VERSION "12.2.7"

NS_ :

BS_:

BU_: AMP CPD EASC HUD MHU XGW_Info PAS_Info PAS_LITE FCAM_Info

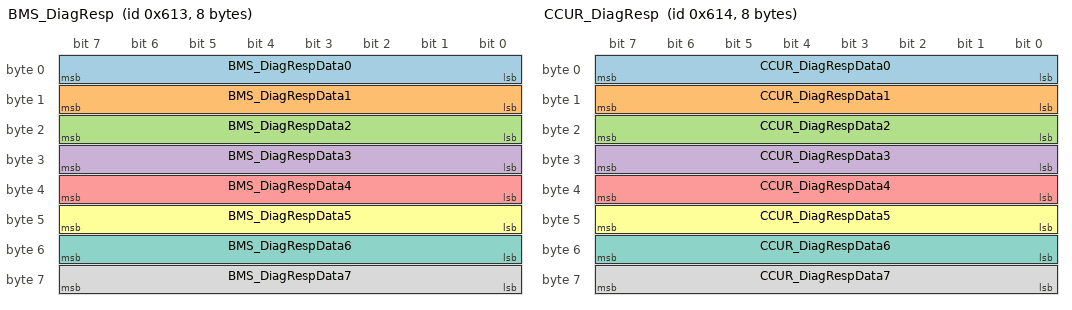
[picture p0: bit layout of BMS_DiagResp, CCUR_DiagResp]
BO_ 1555 BMS_DiagResp: 8 XGW_Info
  SG_ BMS_DiagRespData0 : 7|8@0+ (1,0) [0|255] "" MHU
  SG_ BMS_DiagRespData1 : 15|8@0+ (1,0) [0|255] "" MHU
  SG_ BMS_DiagRespData2 : 23|8@0+ (1,0) [0|255] "" MHU
  SG_ BMS_DiagRespData3 : 31|8@0+ (1,0) [0|255] "" MHU
  SG_ BMS_DiagRespData4 : 39|8@0+ (1,0) [0|255] "" MHU
  SG_ BMS_DiagRespData5 : 47|8@0+ (1,0) [0|255] "" MHU
  SG_ BMS_DiagRespData6 : 55|8@0+ (1,0) [0|255] "" MHU
  SG_ BMS_DiagRespData7 : 63|8@0+ (1,0) [0|255] "-" MHU

BO_ 1556 CCUR_DiagResp: 8 XGW_Info
  SG_ CCUR_DiagRespData0 : 7|8@0+ (1,0) [0|255] "" MHU
  SG_ CCUR_DiagRespData1 : 15|8@0+ (1,0) [0|255] "" MHU
  SG_ CCUR_DiagRespData2 : 23|8@0+ (1,0) [0|255] "" MHU
  SG_ CCUR_DiagRespData3 : 31|8@0+ (1,0) [0|255] "" MHU
  SG_ CCUR_DiagRespData4 : 39|8@0+ (1,0) [0|255] "-" MHU
  SG_ CCUR_DiagRespData5 : 47|8@0+ (1,0) [0|255] "" MHU
  SG_ CCUR_DiagRespData6 : 55|8@0+ (1,0) [0|255] "-" MHU
  SG_ CCUR_DiagRespData7 : 63|8@0+ (1,0) [0|255] "" MHU

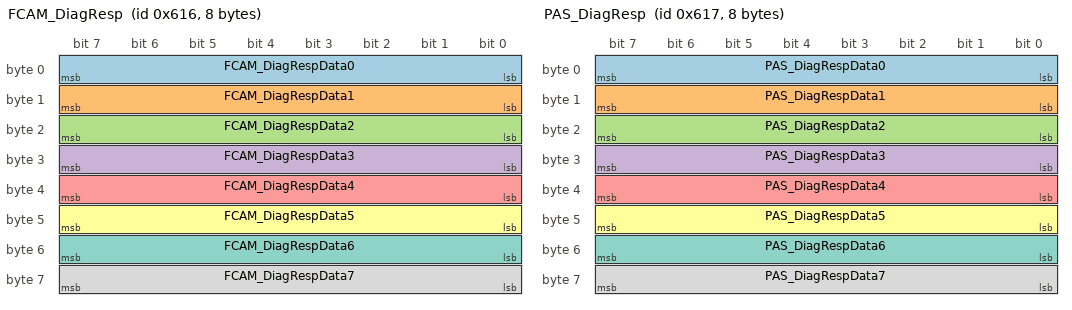
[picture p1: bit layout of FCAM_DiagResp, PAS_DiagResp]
BO_ 1558 FCAM_DiagResp: 8 XGW_Info
 SG_ FCAM_DiagRespData0 : 7|8@0+ (1,0) [0|255] ""  MHU
 SG_ FCAM_DiagRespData1 : 15|8@0+ (1,0) [0|255] ""  MHU
 SG_ FCAM_DiagRespData2 : 23|8@0+ (1,0) [0|255] ""  MHU
 SG_ FCAM_DiagRespData3 : 31|8@0+ (1,0) [0|255] ""  MHU
 SG_ FCAM_DiagRespData4 : 39|8@0+ (1,0) [0|255] ""  MHU
 SG_ FCAM_DiagRespData5 : 47|8@0+ (1,0) [0|255] ""  MHU
 SG_ FCAM_DiagRespData6 : 55|8@0+ (1,0) [0|255] ""  MHU
 SG_ FCAM_DiagRespData7 : 63|8@0+ (1,0) [0|255] ""  MHU

BO_ 1559 PAS_DiagResp: 8 XGW_Info
 SG_ PAS_DiagRespData0 : 7|8@0+ (1,0) [0|255] ""  MHU
 SG_ PAS_DiagRespData1 : 15|8@0+ (1,0) [0|255] ""  MHU
 SG_ PAS_DiagRespData2 : 23|8@0+ (1,0) [0|255] ""  MHU
 SG_ PAS_DiagRespData3 : 31|8@0+ (1,0) [0|255] ""  MHU
 SG_ PAS_DiagRespData4 : 39|8@0+ (1,0) [0|255] ""  MHU
 SG_ PAS_DiagRespData5 : 47|8@0+ (1,0) [0|255] ""  MHU
 SG_ PAS_DiagRespData6 : 55|8@0+ (1,0) [0|255] ""  MHU
 SG_ PAS_DiagRespData7 : 63|8@0+ (1,0) [0|255] ""  MHU

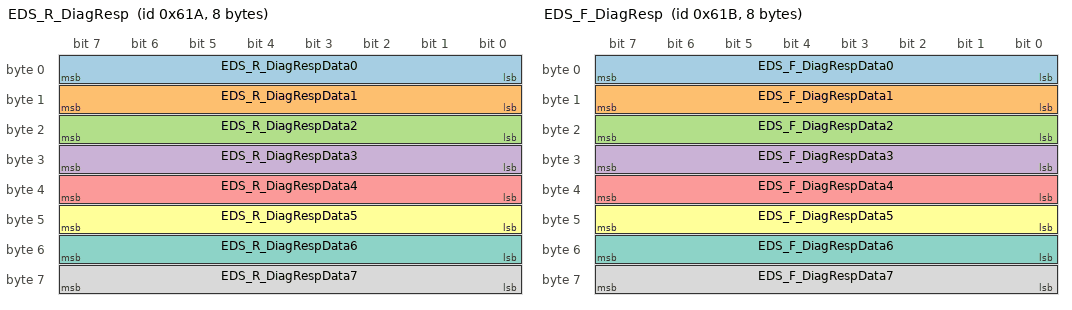
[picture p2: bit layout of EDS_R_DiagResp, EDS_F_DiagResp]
BO_ 1562 EDS_R_DiagResp: 8 XGW_Info
  SG_ EDS_R_DiagRespData0 : 7|8@0+ (1,0) [0|255] "" MHU
  SG_ EDS_R_DiagRespData1 : 15|8@0+ (1,0) [0|255] "" MHU
  SG_ EDS_R_DiagRespData2 : 23|8@0+ (1,0) [0|255] "-" MHU
  SG_ EDS_R_DiagRespData3 : 31|8@0+ (1,0) [0|255] "" MHU
  SG_ EDS_R_DiagRespData4 : 39|8@0+ (1,0) [0|255] "" MHU
  SG_ EDS_R_DiagRespData5 : 47|8@0+ (1,0) [0|255] "-" MHU
  SG_ EDS_R_DiagRespData6 : 55|8@0+ (1,0) [0|255] "-" MHU
  SG_ EDS_R_DiagRespData7 : 63|8@0+ (1,0) [0|255] "-" MHU

BO_ 1563 EDS_F_DiagResp: 8 XGW_Info
  SG_ EDS_F_DiagRespData0 : 7|8@0+ (1,0) [0|255] "" MHU
  SG_ EDS_F_DiagRespData1 : 15|8@0+ (1,0) [0|255] "" MHU
  SG_ EDS_F_DiagRespData2 : 23|8@0+ (1,0) [0|255] "-" MHU
  SG_ EDS_F_DiagRespData3 : 31|8@0+ (1,0) [0|255] "" MHU
  SG_ EDS_F_DiagRespData4 : 39|8@0+ (1,0) [0|255] "" MHU
  SG_ EDS_F_DiagRespData5 : 47|8@0+ (1,0) [0|255] "" MHU
  SG_ EDS_F_DiagRespData6 : 55|8@0+ (1,0) [0|255] "-" MHU
  SG_ EDS_F_DiagRespData7 : 63|8@0+ (1,0) [0|255] "" MHU

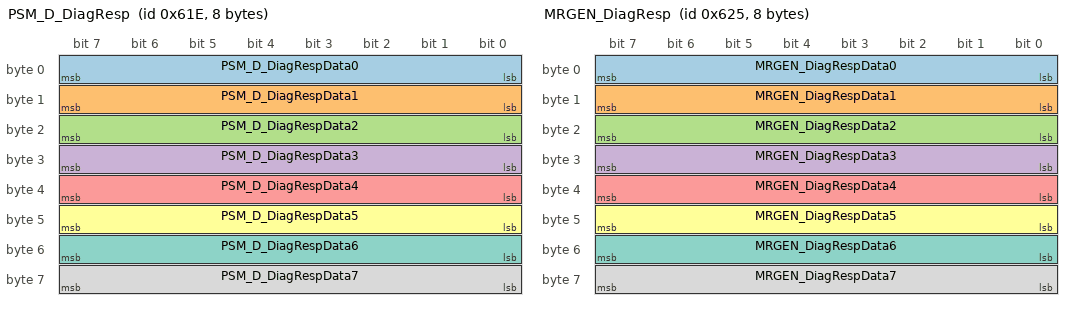
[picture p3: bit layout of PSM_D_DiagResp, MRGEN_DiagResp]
BO_ 1566 PSM_D_DiagResp: 8 XGW_Info
  SG_ PSM_D_DiagRespData0 : 7|8@0+ (1,0) [0|255] "" MHU
  SG_ PSM_D_DiagRespData1 : 15|8@0+ (1,0) [0|255] "" MHU
  SG_ PSM_D_DiagRespData2 : 23|8@0+ (1,0) [0|255] "" MHU
  SG_ PSM_D_DiagRespData3 : 31|8@0+ (1,0) [0|255] "-" MHU
  SG_ PSM_D_DiagRespData4 : 39|8@0+ (1,0) [0|255] "" MHU
  SG_ PSM_D_DiagRespData5 : 47|8@0+ (1,0) [0|255] "" MHU
  SG_ PSM_D_DiagRespData6 : 55|8@0+ (1,0) [0|255] "" MHU
  SG_ PSM_D_DiagRespData7 : 63|8@0+ (1,0) [0|255] "" MHU

BO_ 1573 MRGEN_DiagResp: 8 XGW_Info
  SG_ MRGEN_DiagRespData0 : 7|8@0+ (1,0) [0|255] "" MHU
  SG_ MRGEN_DiagRespData1 : 15|8@0+ (1,0) [0|255] "" MHU
  SG_ MRGEN_DiagRespData2 : 23|8@0+ (1,0) [0|255] "" MHU
  SG_ MRGEN_DiagRespData3 : 31|8@0+ (1,0) [0|255] "" MHU
  SG_ MRGEN_DiagRespData4 : 39|8@0+ (1,0) [0|255] "" MHU
  SG_ MRGEN_DiagRespData5 : 47|8@0+ (1,0) [0|255] "" MHU
  SG_ MRGEN_DiagRespData6 : 55|8@0+ (1,0) [0|255] "" MHU
  SG_ MRGEN_DiagRespData7 : 63|8@0+ (1,0) [0|255] "" MHU

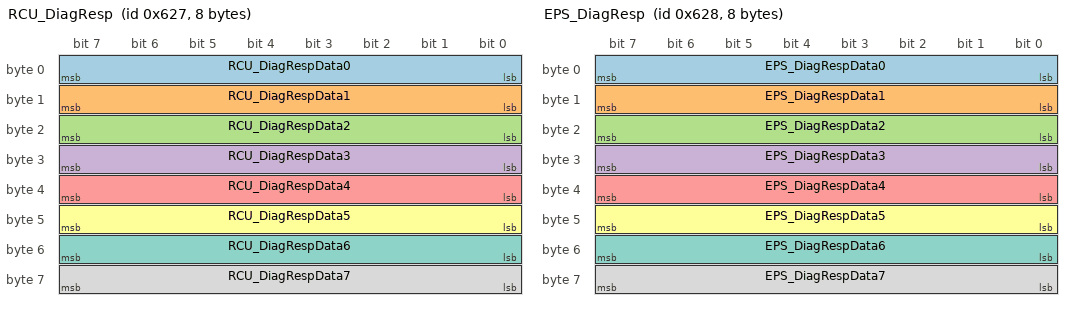
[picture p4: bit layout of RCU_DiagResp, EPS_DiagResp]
BO_ 1575 RCU_DiagResp: 8 XGW_Info
  SG_ RCU_DiagRespData0 : 7|8@0+ (1,0) [0|255] "" MHU
  SG_ RCU_DiagRespData1 : 15|8@0+ (1,0) [0|255] "" MHU
  SG_ RCU_DiagRespData2 : 23|8@0+ (1,0) [0|255] "" MHU
  SG_ RCU_DiagRespData3 : 31|8@0+ (1,0) [0|255] "" MHU
  SG_ RCU_DiagRespData4 : 39|8@0+ (1,0) [0|255] "" MHU
  SG_ RCU_DiagRespData5 : 47|8@0+ (1,0) [0|255] "" MHU
  SG_ RCU_DiagRespData6 : 55|8@0+ (1,0) [0|255] "" MHU
  SG_ RCU_DiagRespData7 : 63|8@0+ (1,0) [0|255] "" MHU

BO_ 1576 EPS_DiagResp: 8 XGW_Info
  SG_ EPS_DiagRespData0 : 7|8@0+ (1,0) [0|255] "-" MHU
  SG_ EPS_DiagRespData1 : 15|8@0+ (1,0) [0|255] "" MHU
  SG_ EPS_DiagRespData2 : 23|8@0+ (1,0) [0|255] "" MHU
  SG_ EPS_DiagRespData3 : 31|8@0+ (1,0) [0|255] "-" MHU
  SG_ EPS_DiagRespData4 : 39|8@0+ (1,0) [0|255] "" MHU
  SG_ EPS_DiagRespData5 : 47|8@0+ (1,0) [0|255] "" MHU
  SG_ EPS_DiagRespData6 : 55|8@0+ (1,0) [0|255] "-" MHU
  SG_ EPS_DiagRespData7 : 63|8@0+ (1,0) [0|255] "-" MHU

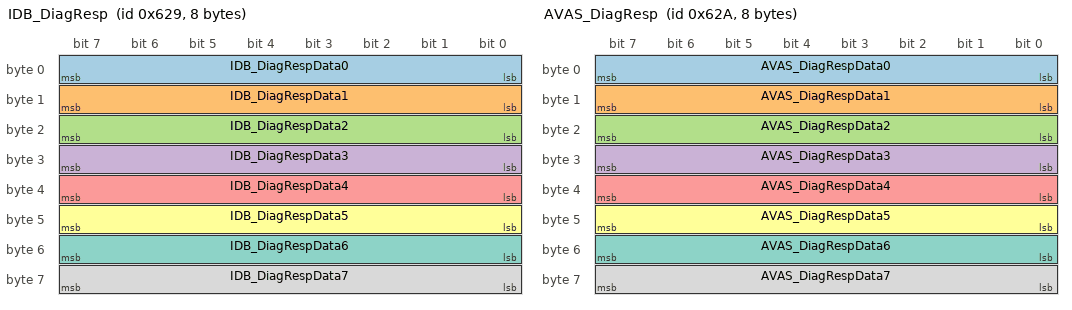
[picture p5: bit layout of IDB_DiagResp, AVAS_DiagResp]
BO_ 1577 IDB_DiagResp: 8 XGW_Info
  SG_ IDB_DiagRespData0 : 7|8@0+ (1,0) [0|255] "" MHU
  SG_ IDB_DiagRespData1 : 15|8@0+ (1,0) [0|255] "-" MHU
  SG_ IDB_DiagRespData2 : 23|8@0+ (1,0) [0|255] "-" MHU
  SG_ IDB_DiagRespData3 : 31|8@0+ (1,0) [0|255] "" MHU
  SG_ IDB_DiagRespData4 : 39|8@0+ (1,0) [0|255] "" MHU
  SG_ IDB_DiagRespData5 : 47|8@0+ (1,0) [0|255] "-" MHU
  SG_ IDB_DiagRespData6 : 55|8@0+ (1,0) [0|255] "-" MHU
  SG_ IDB_DiagRespData7 : 63|8@0+ (1,0) [0|255] "" MHU

BO_ 1578 AVAS_DiagResp: 8 XGW_Info
  SG_ AVAS_DiagRespData0 : 7|8@0+ (1,0) [0|255] "" MHU
  SG_ AVAS_DiagRespData1 : 15|8@0+ (1,0) [0|255] "" MHU
  SG_ AVAS_DiagRespData2 : 23|8@0+ (1,0) [0|255] "" MHU
  SG_ AVAS_DiagRespData3 : 31|8@0+ (1,0) [0|255] "" MHU
  SG_ AVAS_DiagRespData4 : 39|8@0+ (1,0) [0|255] "" MHU
  SG_ AVAS_DiagRespData5 : 47|8@0+ (1,0) [0|255] "" MHU
  SG_ AVAS_DiagRespData6 : 55|8@0+ (1,0) [0|255] "" MHU
  SG_ AVAS_DiagRespData7 : 63|8@0+ (1,0) [0|255] "-" MHU

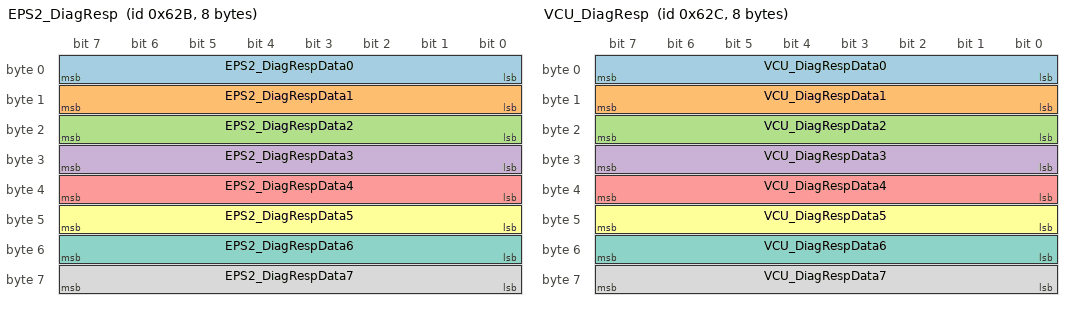
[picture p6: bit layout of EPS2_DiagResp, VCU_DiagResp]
BO_ 1579 EPS2_DiagResp: 8 XGW_Info
  SG_ EPS2_DiagRespData0 : 7|8@0+ (1,0) [0|255] "" MHU
  SG_ EPS2_DiagRespData1 : 15|8@0+ (1,0) [0|255] "-" MHU
  SG_ EPS2_DiagRespData2 : 23|8@0+ (1,0) [0|255] "-" MHU
  SG_ EPS2_DiagRespData3 : 31|8@0+ (1,0) [0|255] "" MHU
  SG_ EPS2_DiagRespData4 : 39|8@0+ (1,0) [0|255] "-" MHU
  SG_ EPS2_DiagRespData5 : 47|8@0+ (1,0) [0|255] "" MHU
  SG_ EPS2_DiagRespData6 : 55|8@0+ (1,0) [0|255] "-" MHU
  SG_ EPS2_DiagRespData7 : 63|8@0+ (1,0) [0|255] "-" MHU

BO_ 1580 VCU_DiagResp: 8 XGW_Info
  SG_ VCU_DiagRespData0 : 7|8@0+ (1,0) [0|255] "" MHU
  SG_ VCU_DiagRespData1 : 15|8@0+ (1,0) [0|255] "" MHU
  SG_ VCU_DiagRespData2 : 23|8@0+ (1,0) [0|255] "" MHU
  SG_ VCU_DiagRespData3 : 31|8@0+ (1,0) [0|255] "" MHU
  SG_ VCU_DiagRespData4 : 39|8@0+ (1,0) [0|255] "-" MHU
  SG_ VCU_DiagRespData5 : 47|8@0+ (1,0) [0|255] "" MHU
  SG_ VCU_DiagRespData6 : 55|8@0+ (1,0) [0|255] "" MHU
  SG_ VCU_DiagRespData7 : 63|8@0+ (1,0) [0|255] "-" MHU

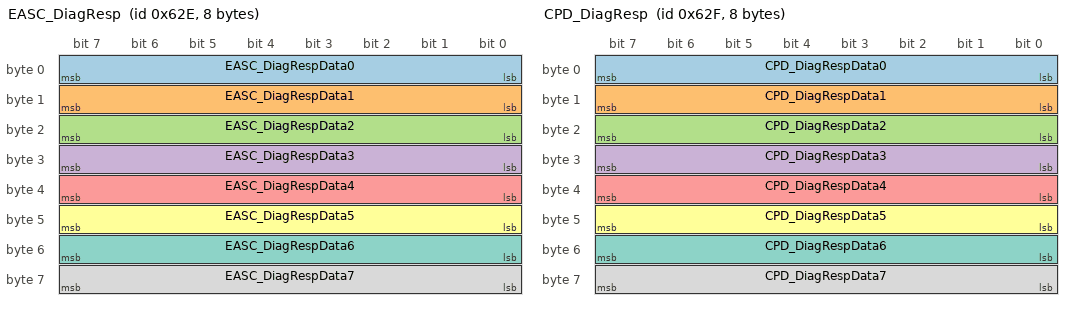
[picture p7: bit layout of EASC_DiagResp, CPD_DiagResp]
BO_ 1582 EASC_DiagResp: 8 EASC
  SG_ EASC_DiagRespData0 : 7|8@0+ (1,0) [0|255] "-" XGW_Info
  SG_ EASC_DiagRespData1 : 15|8@0+ (1,0) [0|255] "-" XGW_Info
  SG_ EASC_DiagRespData2 : 23|8@0+ (1,0) [0|255] "-" XGW_Info
  SG_ EASC_DiagRespData3 : 31|8@0+ (1,0) [0|255] "" XGW_Info
  SG_ EASC_DiagRespData4 : 39|8@0+ (1,0) [0|255] "" XGW_Info
  SG_ EASC_DiagRespData5 : 47|8@0+ (1,0) [0|255] "" XGW_Info
  SG_ EASC_DiagRespData6 : 55|8@0+ (1,0) [0|255] "" XGW_Info
  SG_ EASC_DiagRespData7 : 63|8@0+ (1,0) [0|255] "" XGW_Info

BO_ 1583 CPD_DiagResp: 8 CPD
  SG_ CPD_DiagRespData0 : 7|8@0+ (1,0) [0|255] "-" XGW_Info
  SG_ CPD_DiagRespData1 : 15|8@0+ (1,0) [0|255] "-" XGW_Info
  SG_ CPD_DiagRespData2 : 23|8@0+ (1,0) [0|255] "" XGW_Info
  SG_ CPD_DiagRespData3 : 31|8@0+ (1,0) [0|255] "-" XGW_Info
  SG_ CPD_DiagRespData4 : 39|8@0+ (1,0) [0|255] "-" XGW_Info
  SG_ CPD_DiagRespData5 : 47|8@0+ (1,0) [0|255] "" XGW_Info
  SG_ CPD_DiagRespData6 : 55|8@0+ (1,0) [0|255] "-" XGW_Info
  SG_ CPD_DiagRespData7 : 63|8@0+ (1,0) [0|255] "" XGW_Info

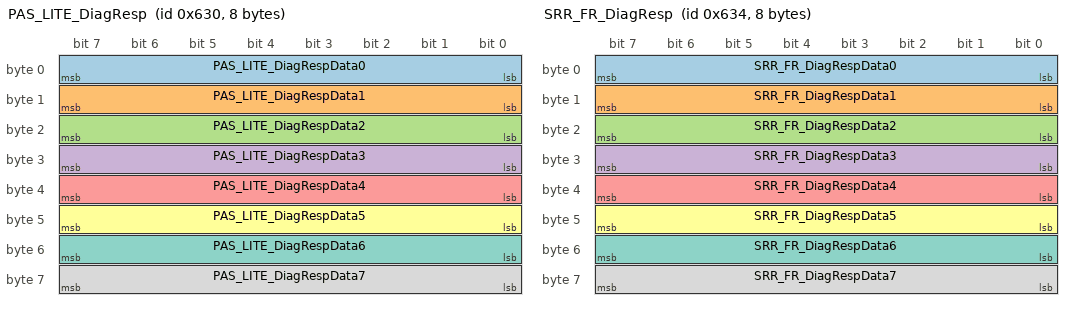
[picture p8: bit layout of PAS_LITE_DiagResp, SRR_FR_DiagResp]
BO_ 1584 PAS_LITE_DiagResp: 8 PAS_LITE
  SG_ PAS_LITE_DiagRespData0 : 7|8@0+ (1,0) [0|255] ""  XGW_Info
  SG_ PAS_LITE_DiagRespData1 : 15|8@0+ (1,0) [0|255] ""  XGW_Info
  SG_ PAS_LITE_DiagRespData2 : 23|8@0+ (1,0) [0|255] ""  XGW_Info
  SG_ PAS_LITE_DiagRespData3 : 31|8@0+ (1,0) [0|255] ""  XGW_Info
  SG_ PAS_LITE_DiagRespData4 : 39|8@0+ (1,0) [0|255] ""  XGW_Info
  SG_ PAS_LITE_DiagRespData5 : 47|8@0+ (1,0) [0|255] ""  XGW_Info
  SG_ PAS_LITE_DiagRespData6 : 55|8@0+ (1,0) [0|255] ""  XGW_Info
  SG_ PAS_LITE_DiagRespData7 : 63|8@0+ (1,0) [0|255] ""  XGW_Info

BO_ 1588 SRR_FR_DiagResp: 8 XGW_Info
  SG_ SRR_FR_DiagRespData0 : 7|8@0+ (1,0) [0|255] "-" MHU
  SG_ SRR_FR_DiagRespData1 : 15|8@0+ (1,0) [0|255] "-" MHU
  SG_ SRR_FR_DiagRespData2 : 23|8@0+ (1,0) [0|255] "-" MHU
  SG_ SRR_FR_DiagRespData3 : 31|8@0+ (1,0) [0|255] "" MHU
  SG_ SRR_FR_DiagRespData4 : 39|8@0+ (1,0) [0|255] "" MHU
  SG_ SRR_FR_DiagRespData5 : 47|8@0+ (1,0) [0|255] "" MHU
  SG_ SRR_FR_DiagRespData6 : 55|8@0+ (1,0) [0|255] "" MHU
  SG_ SRR_FR_DiagRespData7 : 63|8@0+ (1,0) [0|255] "" MHU

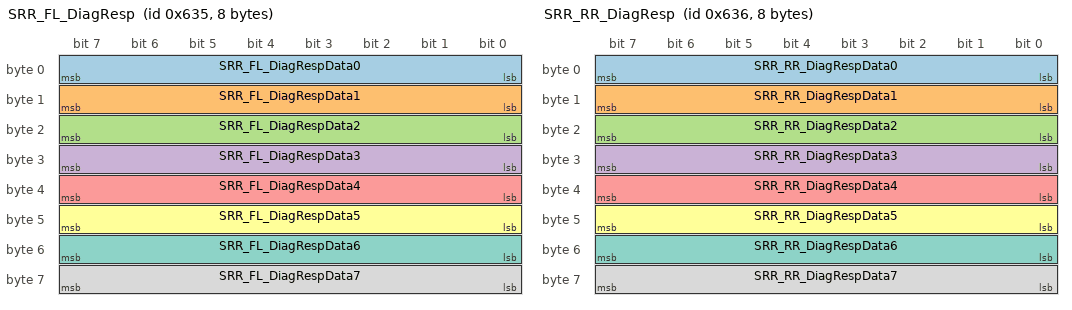
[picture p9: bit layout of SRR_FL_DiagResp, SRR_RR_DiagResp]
BO_ 1589 SRR_FL_DiagResp: 8 XGW_Info
  SG_ SRR_FL_DiagRespData0 : 7|8@0+ (1,0) [0|255] "" MHU
  SG_ SRR_FL_DiagRespData1 : 15|8@0+ (1,0) [0|255] "-" MHU
  SG_ SRR_FL_DiagRespData2 : 23|8@0+ (1,0) [0|255] "" MHU
  SG_ SRR_FL_DiagRespData3 : 31|8@0+ (1,0) [0|255] "-" MHU
  SG_ SRR_FL_DiagRespData4 : 39|8@0+ (1,0) [0|255] "" MHU
  SG_ SRR_FL_DiagRespData5 : 47|8@0+ (1,0) [0|255] "-" MHU
  SG_ SRR_FL_DiagRespData6 : 55|8@0+ (1,0) [0|255] "-" MHU
  SG_ SRR_FL_DiagRespData7 : 63|8@0+ (1,0) [0|255] "" MHU

BO_ 1590 SRR_RR_DiagResp: 8 XGW_Info
  SG_ SRR_RR_DiagRespData0 : 7|8@0+ (1,0) [0|255] "" MHU
  SG_ SRR_RR_DiagRespData1 : 15|8@0+ (1,0) [0|255] "-" MHU
  SG_ SRR_RR_DiagRespData2 : 23|8@0+ (1,0) [0|255] "-" MHU
  SG_ SRR_RR_DiagRespData3 : 31|8@0+ (1,0) [0|255] "" MHU
  SG_ SRR_RR_DiagRespData4 : 39|8@0+ (1,0) [0|255] "-" MHU
  SG_ SRR_RR_DiagRespData5 : 47|8@0+ (1,0) [0|255] "-" MHU
  SG_ SRR_RR_DiagRespData6 : 55|8@0+ (1,0) [0|255] "-" MHU
  SG_ SRR_RR_DiagRespData7 : 63|8@0+ (1,0) [0|255] "-" MHU

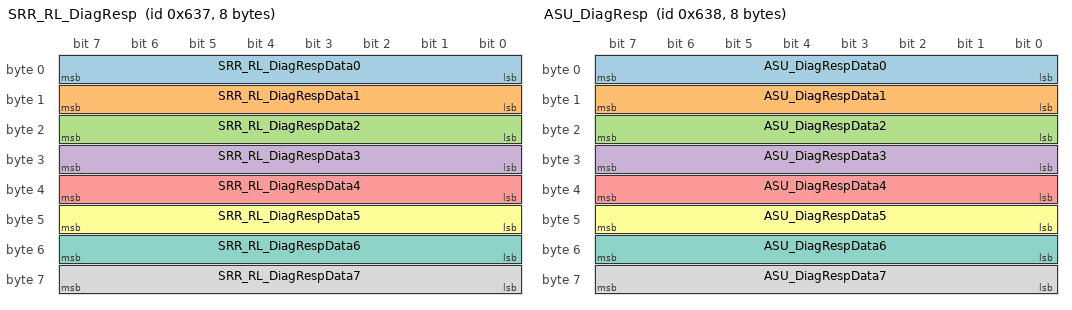
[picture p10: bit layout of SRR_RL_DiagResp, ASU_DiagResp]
BO_ 1591 SRR_RL_DiagResp: 8 XGW_Info
  SG_ SRR_RL_DiagRespData0 : 7|8@0+ (1,0) [0|255] "" MHU
  SG_ SRR_RL_DiagRespData1 : 15|8@0+ (1,0) [0|255] "-" MHU
  SG_ SRR_RL_DiagRespData2 : 23|8@0+ (1,0) [0|255] "-" MHU
  SG_ SRR_RL_DiagRespData3 : 31|8@0+ (1,0) [0|255] "-" MHU
  SG_ SRR_RL_DiagRespData4 : 39|8@0+ (1,0) [0|255] "" MHU
  SG_ SRR_RL_DiagRespData5 : 47|8@0+ (1,0) [0|255] "-" MHU
  SG_ SRR_RL_DiagRespData6 : 55|8@0+ (1,0) [0|255] "-" MHU
  SG_ SRR_RL_DiagRespData7 : 63|8@0+ (1,0) [0|255] "-" MHU

BO_ 1592 ASU_DiagResp: 8 XGW_Info
  SG_ ASU_DiagRespData0 : 7|8@0+ (1,0) [0|255] "-" MHU
  SG_ ASU_DiagRespData1 : 15|8@0+ (1,0) [0|255] "-" MHU
  SG_ ASU_DiagRespData2 : 23|8@0+ (1,0) [0|255] "-" MHU
  SG_ ASU_DiagRespData3 : 31|8@0+ (1,0) [0|255] "-" MHU
  SG_ ASU_DiagRespData4 : 39|8@0+ (1,0) [0|255] "-" MHU
  SG_ ASU_DiagRespData5 : 47|8@0+ (1,0) [0|255] "-" MHU
  SG_ ASU_DiagRespData6 : 55|8@0+ (1,0) [0|255] "-" MHU
  SG_ ASU_DiagRespData7 : 63|8@0+ (1,0) [0|255] "-" MHU

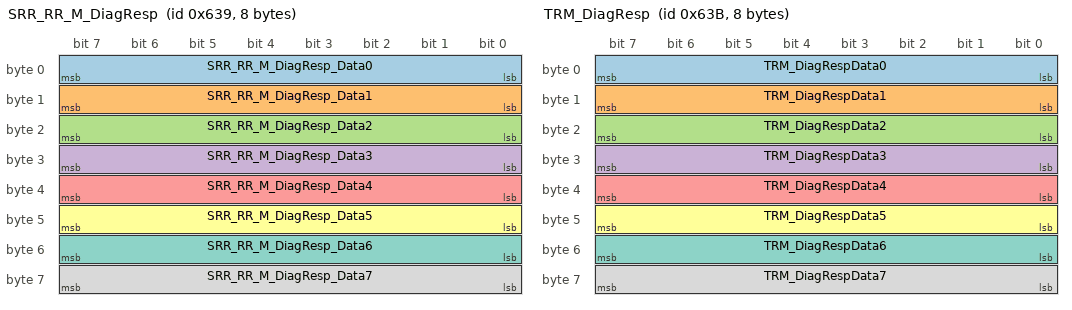
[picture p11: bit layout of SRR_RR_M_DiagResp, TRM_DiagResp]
BO_ 1593 SRR_RR_M_DiagResp: 8 XGW_Info
  SG_ SRR_RR_M_DiagResp_Data0 : 7|8@0+ (1,0) [0|255] "" MHU
  SG_ SRR_RR_M_DiagResp_Data1 : 15|8@0+ (1,0) [0|255] "-" MHU
  SG_ SRR_RR_M_DiagResp_Data2 : 23|8@0+ (1,0) [0|255] "-" MHU
  SG_ SRR_RR_M_DiagResp_Data3 : 31|8@0+ (1,0) [0|255] "" MHU
  SG_ SRR_RR_M_DiagResp_Data4 : 39|8@0+ (1,0) [0|255] "-" MHU
  SG_ SRR_RR_M_DiagResp_Data5 : 47|8@0+ (1,0) [0|255] "-" MHU
  SG_ SRR_RR_M_DiagResp_Data6 : 55|8@0+ (1,0) [0|255] "-" MHU
  SG_ SRR_RR_M_DiagResp_Data7 : 63|8@0+ (1,0) [0|255] "-" MHU

BO_ 1595 TRM_DiagResp: 8 XGW_Info
  SG_ TRM_DiagRespData0 : 7|8@0+ (1,0) [0|255] "" MHU
  SG_ TRM_DiagRespData1 : 15|8@0+ (1,0) [0|255] "" MHU
  SG_ TRM_DiagRespData2 : 23|8@0+ (1,0) [0|255] "" MHU
  SG_ TRM_DiagRespData3 : 31|8@0+ (1,0) [0|255] "-" MHU
  SG_ TRM_DiagRespData4 : 39|8@0+ (1,0) [0|255] "-" MHU
  SG_ TRM_DiagRespData5 : 47|8@0+ (1,0) [0|255] "-" MHU
  SG_ TRM_DiagRespData6 : 55|8@0+ (1,0) [0|255] "" MHU
  SG_ TRM_DiagRespData7 : 63|8@0+ (1,0) [0|255] "-" MHU

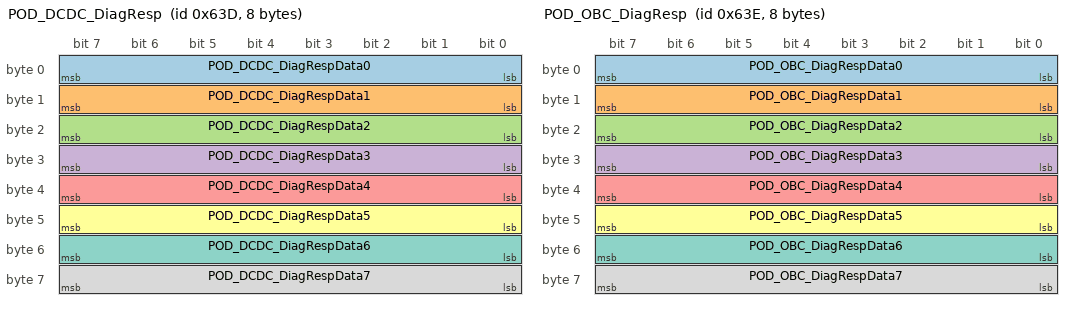
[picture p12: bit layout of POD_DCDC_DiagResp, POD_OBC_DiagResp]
BO_ 1597 POD_DCDC_DiagResp: 8 XGW_Info
  SG_ POD_DCDC_DiagRespData0 : 7|8@0+ (1,0) [0|255] "" MHU
  SG_ POD_DCDC_DiagRespData1 : 15|8@0+ (1,0) [0|255] "" MHU
  SG_ POD_DCDC_DiagRespData2 : 23|8@0+ (1,0) [0|255] "-" MHU
  SG_ POD_DCDC_DiagRespData3 : 31|8@0+ (1,0) [0|255] "-" MHU
  SG_ POD_DCDC_DiagRespData4 : 39|8@0+ (1,0) [0|255] "" MHU
  SG_ POD_DCDC_DiagRespData5 : 47|8@0+ (1,0) [0|255] "" MHU
  SG_ POD_DCDC_DiagRespData6 : 55|8@0+ (1,0) [0|255] "-" MHU
  SG_ POD_DCDC_DiagRespData7 : 63|8@0+ (1,0) [0|255] "" MHU

BO_ 1598 POD_OBC_DiagResp: 8 XGW_Info
  SG_ POD_OBC_DiagRespData0 : 7|8@0+ (1,0) [0|255] "" MHU
  SG_ POD_OBC_DiagRespData1 : 15|8@0+ (1,0) [0|255] "-" MHU
  SG_ POD_OBC_DiagRespData2 : 23|8@0+ (1,0) [0|255] "" MHU
  SG_ POD_OBC_DiagRespData3 : 31|8@0+ (1,0) [0|255] "-" MHU
  SG_ POD_OBC_DiagRespData4 : 39|8@0+ (1,0) [0|255] "" MHU
  SG_ POD_OBC_DiagRespData5 : 47|8@0+ (1,0) [0|255] "-" MHU
  SG_ POD_OBC_DiagRespData6 : 55|8@0+ (1,0) [0|255] "" MHU
  SG_ POD_OBC_DiagRespData7 : 63|8@0+ (1,0) [0|255] "-" MHU

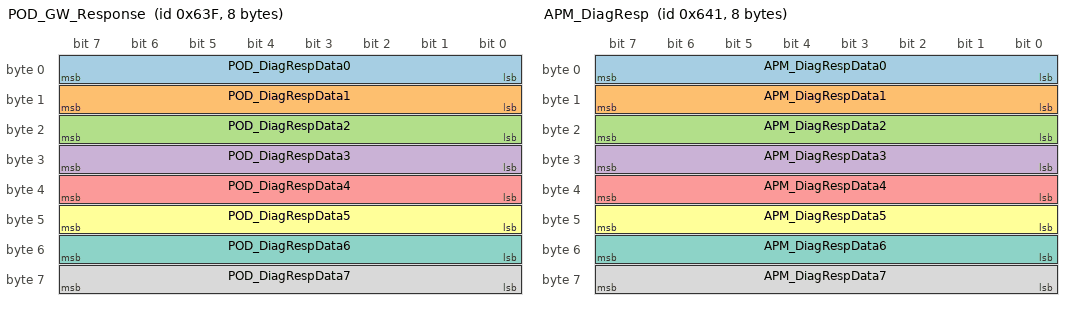
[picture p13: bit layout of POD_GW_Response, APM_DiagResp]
BO_ 1599 POD_GW_Response: 8 XGW_Info
  SG_ POD_DiagRespData0 : 7|8@0+ (1,0) [0|255] "-" MHU
  SG_ POD_DiagRespData1 : 15|8@0+ (1,0) [0|255] "" MHU
  SG_ POD_DiagRespData2 : 23|8@0+ (1,0) [0|255] "" MHU
  SG_ POD_DiagRespData3 : 31|8@0+ (1,0) [0|255] "-" MHU
  SG_ POD_DiagRespData4 : 39|8@0+ (1,0) [0|255] "-" MHU
  SG_ POD_DiagRespData5 : 47|8@0+ (1,0) [0|255] "-" MHU
  SG_ POD_DiagRespData6 : 55|8@0+ (1,0) [0|255] "" MHU
  SG_ POD_DiagRespData7 : 63|8@0+ (1,0) [0|255] "" MHU

BO_ 1601 APM_DiagResp: 8 XGW_Info
  SG_ APM_DiagRespData0 : 7|8@0+ (1,0) [0|255] "" MHU
  SG_ APM_DiagRespData1 : 15|8@0+ (1,0) [0|255] "" MHU
  SG_ APM_DiagRespData2 : 23|8@0+ (1,0) [0|255] "" MHU
  SG_ APM_DiagRespData3 : 31|8@0+ (1,0) [0|255] "" MHU
  SG_ APM_DiagRespData4 : 39|8@0+ (1,0) [0|255] "-" MHU
  SG_ APM_DiagRespData5 : 47|8@0+ (1,0) [0|255] "" MHU
  SG_ APM_DiagRespData6 : 55|8@0+ (1,0) [0|255] "-" MHU
  SG_ APM_DiagRespData7 : 63|8@0+ (1,0) [0|255] "" MHU

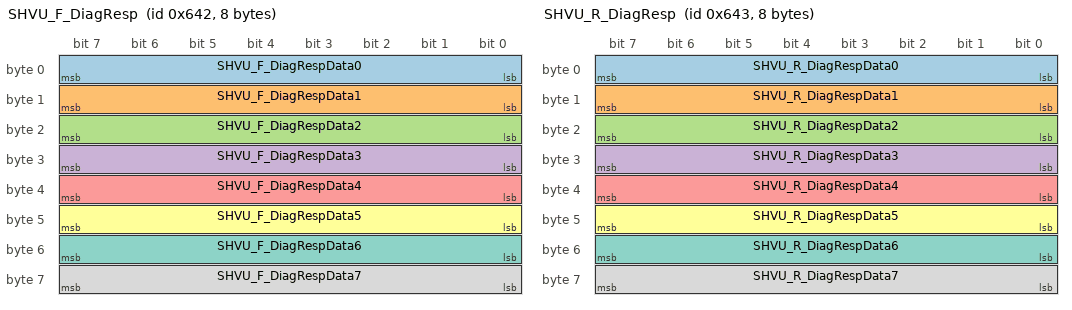
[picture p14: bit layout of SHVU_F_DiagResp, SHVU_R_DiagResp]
BO_ 1602 SHVU_F_DiagResp: 8 XGW_Info
  SG_ SHVU_F_DiagRespData0 : 7|8@0+ (1,0) [0|255] "" MHU
  SG_ SHVU_F_DiagRespData1 : 15|8@0+ (1,0) [0|255] "" MHU
  SG_ SHVU_F_DiagRespData2 : 23|8@0+ (1,0) [0|255] "-" MHU
  SG_ SHVU_F_DiagRespData3 : 31|8@0+ (1,0) [0|255] "" MHU
  SG_ SHVU_F_DiagRespData4 : 39|8@0+ (1,0) [0|255] "" MHU
  SG_ SHVU_F_DiagRespData5 : 47|8@0+ (1,0) [0|255] "" MHU
  SG_ SHVU_F_DiagRespData6 : 55|8@0+ (1,0) [0|255] "-" MHU
  SG_ SHVU_F_DiagRespData7 : 63|8@0+ (1,0) [0|255] "" MHU

BO_ 1603 SHVU_R_DiagResp: 8 XGW_Info
  SG_ SHVU_R_DiagRespData0 : 7|8@0+ (1,0) [0|255] "" MHU
  SG_ SHVU_R_DiagRespData1 : 15|8@0+ (1,0) [0|255] "-" MHU
  SG_ SHVU_R_DiagRespData2 : 23|8@0+ (1,0) [0|255] "" MHU
  SG_ SHVU_R_DiagRespData3 : 31|8@0+ (1,0) [0|255] "-" MHU
  SG_ SHVU_R_DiagRespData4 : 39|8@0+ (1,0) [0|255] "-" MHU
  SG_ SHVU_R_DiagRespData5 : 47|8@0+ (1,0) [0|255] "" MHU
  SG_ SHVU_R_DiagRespData6 : 55|8@0+ (1,0) [0|255] "-" MHU
  SG_ SHVU_R_DiagRespData7 : 63|8@0+ (1,0) [0|255] "" MHU

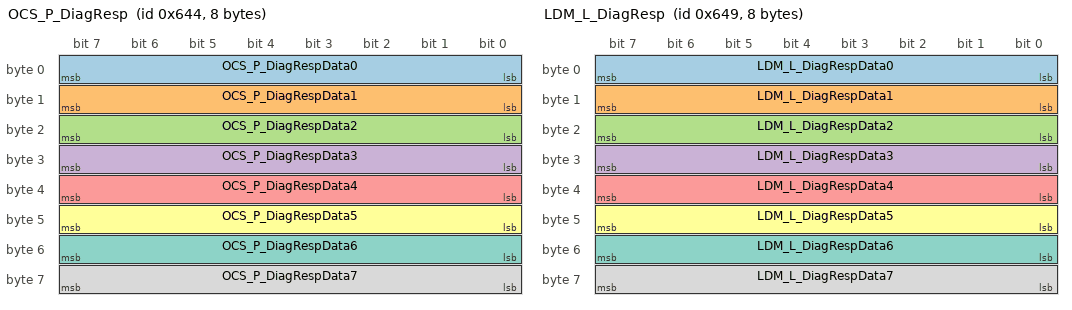
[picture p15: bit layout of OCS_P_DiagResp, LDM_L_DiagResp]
BO_ 1604 OCS_P_DiagResp: 8 XGW_Info
  SG_ OCS_P_DiagRespData0 : 7|8@0+ (1,0) [0|255] "" MHU
  SG_ OCS_P_DiagRespData1 : 15|8@0+ (1,0) [0|255] "-" MHU
  SG_ OCS_P_DiagRespData2 : 23|8@0+ (1,0) [0|255] "" MHU
  SG_ OCS_P_DiagRespData3 : 31|8@0+ (1,0) [0|255] "-" MHU
  SG_ OCS_P_DiagRespData4 : 39|8@0+ (1,0) [0|255] "" MHU
  SG_ OCS_P_DiagRespData5 : 47|8@0+ (1,0) [0|255] "" MHU
  SG_ OCS_P_DiagRespData6 : 55|8@0+ (1,0) [0|255] "" MHU
  SG_ OCS_P_DiagRespData7 : 63|8@0+ (1,0) [0|255] "" MHU

BO_ 1609 LDM_L_DiagResp: 8 XGW_Info
  SG_ LDM_L_DiagRespData0 : 7|8@0+ (1,0) [0|255] "-" MHU
  SG_ LDM_L_DiagRespData1 : 15|8@0+ (1,0) [0|255] "" MHU
  SG_ LDM_L_DiagRespData2 : 23|8@0+ (1,0) [0|255] "-" MHU
  SG_ LDM_L_DiagRespData3 : 31|8@0+ (1,0) [0|255] "" MHU
  SG_ LDM_L_DiagRespData4 : 39|8@0+ (1,0) [0|255] "" MHU
  SG_ LDM_L_DiagRespData5 : 47|8@0+ (1,0) [0|255] "-" MHU
  SG_ LDM_L_DiagRespData6 : 55|8@0+ (1,0) [0|255] "" MHU
  SG_ LDM_L_DiagRespData7 : 63|8@0+ (1,0) [0|255] "-" MHU

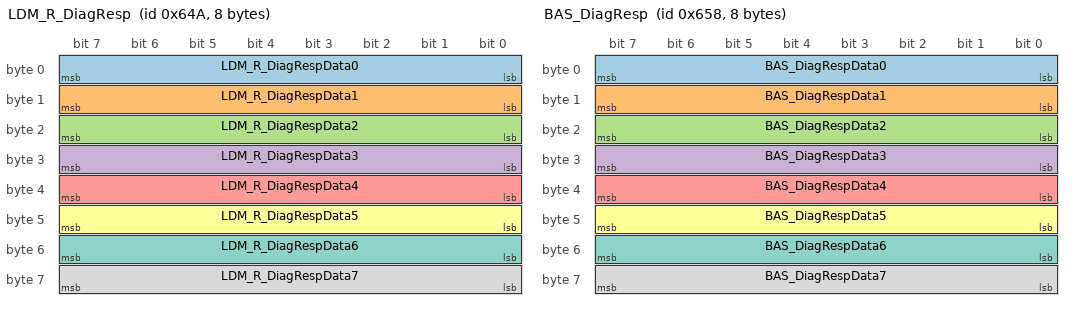
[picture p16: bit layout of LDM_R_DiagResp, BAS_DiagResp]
BO_ 1610 LDM_R_DiagResp: 8 XGW_Info
  SG_ LDM_R_DiagRespData0 : 7|8@0+ (1,0) [0|255] "" MHU
  SG_ LDM_R_DiagRespData1 : 15|8@0+ (1,0) [0|255] "-" MHU
  SG_ LDM_R_DiagRespData2 : 23|8@0+ (1,0) [0|255] "" MHU
  SG_ LDM_R_DiagRespData3 : 31|8@0+ (1,0) [0|255] "" MHU
  SG_ LDM_R_DiagRespData4 : 39|8@0+ (1,0) [0|255] "-" MHU
  SG_ LDM_R_DiagRespData5 : 47|8@0+ (1,0) [0|255] "" MHU
  SG_ LDM_R_DiagRespData6 : 55|8@0+ (1,0) [0|255] "" MHU
  SG_ LDM_R_DiagRespData7 : 63|8@0+ (1,0) [0|255] "-" MHU

BO_ 1624 BAS_DiagResp: 8 XGW_Info
  SG_ BAS_DiagRespData0 : 7|8@0+ (1,0) [0|255] "" MHU
  SG_ BAS_DiagRespData1 : 15|8@0+ (1,0) [0|255] "" MHU
  SG_ BAS_DiagRespData2 : 23|8@0+ (1,0) [0|255] "" MHU
  SG_ BAS_DiagRespData3 : 31|8@0+ (1,0) [0|255] "" MHU
  SG_ BAS_DiagRespData4 : 39|8@0+ (1,0) [0|255] "" MHU
  SG_ BAS_DiagRespData5 : 47|8@0+ (1,0) [0|255] "" MHU
  SG_ BAS_DiagRespData6 : 55|8@0+ (1,0) [0|255] "-" MHU
  SG_ BAS_DiagRespData7 : 63|8@0+ (1,0) [0|255] "-" MHU

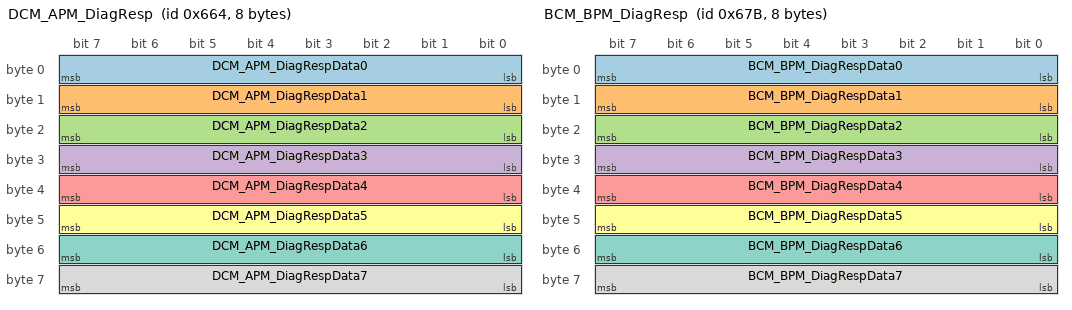
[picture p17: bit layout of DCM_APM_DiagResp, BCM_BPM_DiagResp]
BO_ 1636 DCM_APM_DiagResp: 8 XGW_Info
  SG_ DCM_APM_DiagRespData0 : 7|8@0+ (1,0) [0|255] "-" MHU
  SG_ DCM_APM_DiagRespData1 : 15|8@0+ (1,0) [0|255] "-" MHU
  SG_ DCM_APM_DiagRespData2 : 23|8@0+ (1,0) [0|255] "" MHU
  SG_ DCM_APM_DiagRespData3 : 31|8@0+ (1,0) [0|255] "-" MHU
  SG_ DCM_APM_DiagRespData4 : 39|8@0+ (1,0) [0|255] "" MHU
  SG_ DCM_APM_DiagRespData5 : 47|8@0+ (1,0) [0|255] "-" MHU
  SG_ DCM_APM_DiagRespData6 : 55|8@0+ (1,0) [0|255] "-" MHU
  SG_ DCM_APM_DiagRespData7 : 63|8@0+ (1,0) [0|255] "" MHU

BO_ 1659 BCM_BPM_DiagResp: 8 XGW_Info
  SG_ BCM_BPM_DiagRespData0 : 7|8@0+ (1,0) [0|255] "" MHU
  SG_ BCM_BPM_DiagRespData1 : 15|8@0+ (1,0) [0|255] "-" MHU
  SG_ BCM_BPM_DiagRespData2 : 23|8@0+ (1,0) [0|255] "" MHU
  SG_ BCM_BPM_DiagRespData3 : 31|8@0+ (1,0) [0|255] "" MHU
  SG_ BCM_BPM_DiagRespData4 : 39|8@0+ (1,0) [0|255] "-" MHU
  SG_ BCM_BPM_DiagRespData5 : 47|8@0+ (1,0) [0|255] "" MHU
  SG_ BCM_BPM_DiagRespData6 : 55|8@0+ (1,0) [0|255] "-" MHU
  SG_ BCM_BPM_DiagRespData7 : 63|8@0+ (1,0) [0|255] "" MHU

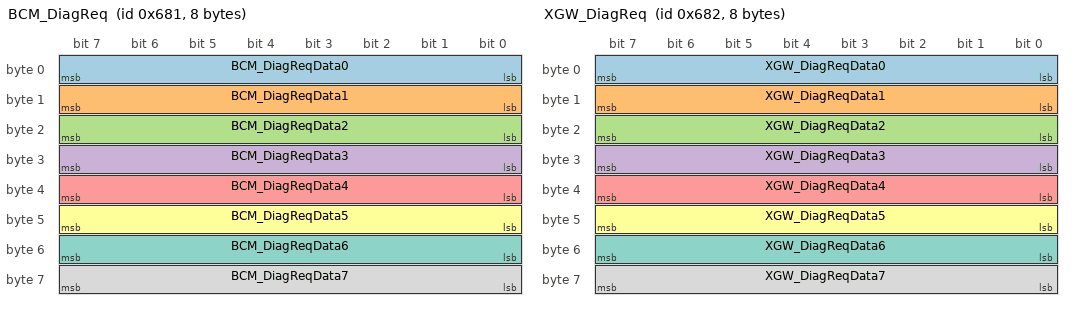
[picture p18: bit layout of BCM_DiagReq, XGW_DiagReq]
BO_ 1665 BCM_DiagReq: 8 MHU
  SG_ BCM_DiagReqData0 : 7|8@0+ (1,0) [0|255] "" XGW_Info
  SG_ BCM_DiagReqData1 : 15|8@0+ (1,0) [0|255] "" XGW_Info
  SG_ BCM_DiagReqData2 : 23|8@0+ (1,0) [0|255] "" XGW_Info
  SG_ BCM_DiagReqData3 : 31|8@0+ (1,0) [0|255] "" XGW_Info
  SG_ BCM_DiagReqData4 : 39|8@0+ (1,0) [0|255] "" XGW_Info
  SG_ BCM_DiagReqData5 : 47|8@0+ (1,0) [0|255] "" XGW_Info
  SG_ BCM_DiagReqData6 : 55|8@0+ (1,0) [0|255] "-" XGW_Info
  SG_ BCM_DiagReqData7 : 63|8@0+ (1,0) [0|255] "-" XGW_Info

BO_ 1666 XGW_DiagReq: 8 MHU
  SG_ XGW_DiagReqData0 : 7|8@0+ (1,0) [0|255] "" XGW_Info
  SG_ XGW_DiagReqData1 : 15|8@0+ (1,0) [0|255] "" XGW_Info
  SG_ XGW_DiagReqData2 : 23|8@0+ (1,0) [0|255] "-" XGW_Info
  SG_ XGW_DiagReqData3 : 31|8@0+ (1,0) [0|255] "-" XGW_Info
  SG_ XGW_DiagReqData4 : 39|8@0+ (1,0) [0|255] "" XGW_Info
  SG_ XGW_DiagReqData5 : 47|8@0+ (1,0) [0|255] "" XGW_Info
  SG_ XGW_DiagReqData6 : 55|8@0+ (1,0) [0|255] "" XGW_Info
  SG_ XGW_DiagReqData7 : 63|8@0+ (1,0) [0|255] "" XGW_Info

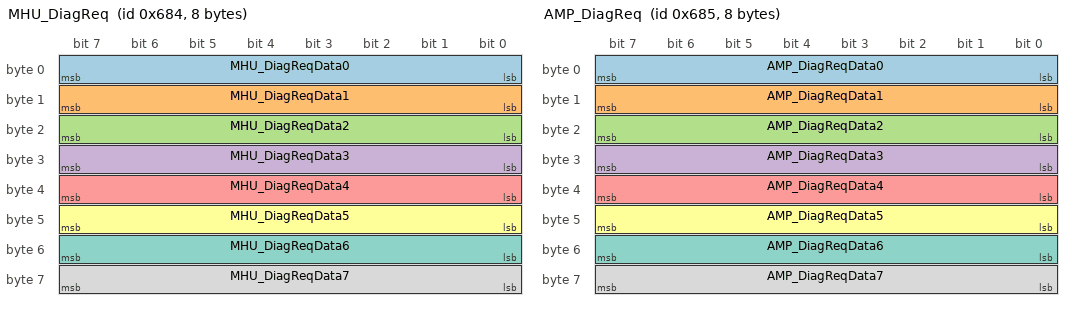
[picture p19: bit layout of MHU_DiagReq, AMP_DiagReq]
BO_ 1668 MHU_DiagReq: 8 XGW_Info
  SG_ MHU_DiagReqData0 : 7|8@0+ (1,0) [0|255] "" MHU
  SG_ MHU_DiagReqData1 : 15|8@0+ (1,0) [0|255] "" MHU
  SG_ MHU_DiagReqData2 : 23|8@0+ (1,0) [0|255] "-" MHU
  SG_ MHU_DiagReqData3 : 31|8@0+ (1,0) [0|255] "-" MHU
  SG_ MHU_DiagReqData4 : 39|8@0+ (1,0) [0|255] "" MHU
  SG_ MHU_DiagReqData5 : 47|8@0+ (1,0) [0|255] "-" MHU
  SG_ MHU_DiagReqData6 : 55|8@0+ (1,0) [0|255] "-" MHU
  SG_ MHU_DiagReqData7 : 63|8@0+ (1,0) [0|255] "-" MHU

BO_ 1669 AMP_DiagReq: 8 XGW_Info
  SG_ AMP_DiagReqData0 : 7|8@0+ (1,0) [0|255] "" AMP
  SG_ AMP_DiagReqData1 : 15|8@0+ (1,0) [0|255] "-" AMP
  SG_ AMP_DiagReqData2 : 23|8@0+ (1,0) [0|255] "" AMP
  SG_ AMP_DiagReqData3 : 31|8@0+ (1,0) [0|255] "" AMP
  SG_ AMP_DiagReqData4 : 39|8@0+ (1,0) [0|255] "" AMP
  SG_ AMP_DiagReqData5 : 47|8@0+ (1,0) [0|255] "-" AMP
  SG_ AMP_DiagReqData6 : 55|8@0+ (1,0) [0|255] "-" AMP
  SG_ AMP_DiagReqData7 : 63|8@0+ (1,0) [0|255] "" AMP

BO_ 1672 ACM_DiagReq: 8 MHU
  SG_ ACM_DiagReqData0 : 7|8@0+ (1,0) [0|255] "" XGW_Info
  SG_ ACM_DiagReqData1 : 15|8@0+ (1,0) [0|255] "" XGW_Info
  SG_ ACM_DiagReqData2 : 23|8@0+ (1,0) [0|255] "" XGW_Info
  SG_ ACM_DiagReqData3 : 31|8@0+ (1,0) [0|255] "-" XGW_Info
  SG_ ACM_DiagReqData4 : 39|8@0+ (1,0) [0|255] "" XGW_Info
  SG_ ACM_DiagReqData5 : 47|8@0+ (1,0) [0|255] "" XGW_Info
  SG_ ACM_DiagReqData6 : 55|8@0+ (1,0) [0|255] "-" XGW_Info
  SG_ ACM_DiagReqData7 : 63|8@0+ (1,0) [0|255] "" XGW_Info

BO_ 1673 CCUF_DiagReq: 8 MHU
  SG_ CCUF_DiagReqData0 : 7|8@0+ (1,0) [0|255] "-" XGW_Info
  SG_ CCUF_DiagReqData1 : 15|8@0+ (1,0) [0|255] "" XGW_Info
  SG_ CCUF_DiagReqData2 : 23|8@0+ (1,0) [0|255] "" XGW_Info
  SG_ CCUF_DiagReqData3 : 31|8@0+ (1,0) [0|255] "" XGW_Info
  SG_ CCUF_DiagReqData4 : 39|8@0+ (1,0) [0|255] "" XGW_Info
  SG_ CCUF_DiagReqData5 : 47|8@0+ (1,0) [0|255] "" XGW_Info
  SG_ CCUF_DiagReqData6 : 55|8@0+ (1,0) [0|255] "" XGW_Info
  SG_ CCUF_DiagReqData7 : 63|8@0+ (1,0) [0|255] "" XGW_Info

BO_ 1677 HUD_DiagReq: 8 XGW_Info
  SG_ HUD_DiagReqData0 : 7|8@0+ (1,0) [0|255] "-" HUD
  SG_ HUD_DiagReqData1 : 15|8@0+ (1,0) [0|255] "" HUD
  SG_ HUD_DiagReqData2 : 23|8@0+ (1,0) [0|255] "-" HUD
  SG_ HUD_DiagReqData3 : 31|8@0+ (1,0) [0|255] "" HUD
  SG_ HUD_DiagReqData4 : 39|8@0+ (1,0) [0|255] "-" HUD
  SG_ HUD_DiagReqData5 : 47|8@0+ (1,0) [0|255] "-" HUD
  SG_ HUD_DiagReqData6 : 55|8@0+ (1,0) [0|255] "" HUD
  SG_ HUD_DiagReqData7 : 63|8@0+ (1,0) [0|255] "" HUD

BO_ 1678 ETG_DiagReq: 8 MHU
  SG_ ETG_DiagReqData0 : 7|8@0+ (1,0) [0|255] "" XGW_Info
  SG_ ETG_DiagReqData1 : 15|8@0+ (1,0) [0|255] "" XGW_Info
  SG_ ETG_DiagReqData2 : 23|8@0+ (1,0) [0|255] "" XGW_Info
  SG_ ETG_DiagReqData3 : 31|8@0+ (1,0) [0|255] "" XGW_Info
  SG_ ETG_DiagReqData4 : 39|8@0+ (1,0) [0|255] "" XGW_Info
  SG_ ETG_DiagReqData5 : 47|8@0+ (1,0) [0|255] "" XGW_Info
  SG_ ETG_DiagReqData6 : 55|8@0+ (1,0) [0|255] "" XGW_Info
  SG_ ETG_DiagReqData7 : 63|8@0+ (1,0) [0|255] "-" XGW_Info

BO_ 1679 YSS_DiagReq: 8 MHU
  SG_ YSS_DiagReqData0 : 7|8@0+ (1,0) [0|255] "" XGW_Info
  SG_ YSS_DiagReqData1 : 15|8@0+ (1,0) [0|255] "" XGW_Info
  SG_ YSS_DiagReqData2 : 23|8@0+ (1,0) [0|255] "-" XGW_Info
  SG_ YSS_DiagReqData3 : 31|8@0+ (1,0) [0|255] "-" XGW_Info
  SG_ YSS_DiagReqData4 : 39|8@0+ (1,0) [0|255] "-" XGW_Info
  SG_ YSS_DiagReqData5 : 47|8@0+ (1,0) [0|255] "-" XGW_Info
  SG_ YSS_DiagReqData6 : 55|8@0+ (1,0) [0|255] "" XGW_Info
  SG_ YSS_DiagReqData7 : 63|8@0+ (1,0) [0|255] "" XGW_Info

BO_ 1680 GS_DiagReq: 8 MHU
  SG_ GS_DiagReqData0 : 7|8@0+ (1,0) [0|255] "" XGW_Info
  SG_ GS_DiagReqData1 : 15|8@0+ (1,0) [0|255] "" XGW_Info
  SG_ GS_DiagReqData2 : 23|8@0+ (1,0) [0|255] "" XGW_Info
  SG_ GS_DiagReqData3 : 31|8@0+ (1,0) [0|255] "" XGW_Info
  SG_ GS_DiagReqData4 : 39|8@0+ (1,0) [0|255] "-" XGW_Info
  SG_ GS_DiagReqData5 : 47|8@0+ (1,0) [0|255] "" XGW_Info
  SG_ GS_DiagReqData6 : 55|8@0+ (1,0) [0|255] "" XGW_Info
  SG_ GS_DiagReqData7 : 63|8@0+ (1,0) [0|255] "" XGW_Info

BO_ 1683 BMS_DiagReq: 8 MHU
  SG_ BMS_DiagReqData0 : 7|8@0+ (1,0) [0|255] "" XGW_Info
  SG_ BMS_DiagReqData1 : 15|8@0+ (1,0) [0|255] "" XGW_Info
  SG_ BMS_DiagReqData2 : 23|8@0+ (1,0) [0|255] "" XGW_Info
  SG_ BMS_DiagReqData3 : 31|8@0+ (1,0) [0|255] "-" XGW_Info
  SG_ BMS_DiagReqData4 : 39|8@0+ (1,0) [0|255] "-" XGW_Info
  SG_ BMS_DiagReqData5 : 47|8@0+ (1,0) [0|255] "-" XGW_Info
  SG_ BMS_DiagReqData6 : 55|8@0+ (1,0) [0|255] "" XGW_Info
  SG_ BMS_DiagReqData7 : 63|8@0+ (1,0) [0|255] "" XGW_Info

BO_ 1684 CCUR_DiagReq: 8 MHU
  SG_ CCUR_DiagReqData0 : 7|8@0+ (1,0) [0|255] "" XGW_Info
  SG_ CCUR_DiagReqData1 : 15|8@0+ (1,0) [0|255] "" XGW_Info
  SG_ CCUR_DiagReqData2 : 23|8@0+ (1,0) [0|255] "" XGW_Info
  SG_ CCUR_DiagReqData3 : 31|8@0+ (1,0) [0|255] "-" XGW_Info
  SG_ CCUR_DiagReqData4 : 39|8@0+ (1,0) [0|255] "-" XGW_Info
  SG_ CCUR_DiagReqData5 : 47|8@0+ (1,0) [0|255] "" XGW_Info
  SG_ CCUR_DiagReqData6 : 55|8@0+ (1,0) [0|255] "" XGW_Info
  SG_ CCUR_DiagReqData7 : 63|8@0+ (1,0) [0|255] "" XGW_Info

BO_ 1686 FCAM_DiagReq: 8 MHU
 SG_ FCAM_DiagReqData0 : 7|8@0+ (1,0) [0|255] ""  XGW_Info
 SG_ FCAM_DiagReqData1 : 15|8@0+ (1,0) [0|255] ""  XGW_Info
 SG_ FCAM_DiagReqData2 : 23|8@0+ (1,0) [0|255] ""  XGW_Info
 SG_ FCAM_DiagReqData3 : 31|8@0+ (1,0) [0|255] ""  XGW_Info
 SG_ FCAM_DiagReqData4 : 39|8@0+ (1,0) [0|255] ""  XGW_Info
 SG_ FCAM_DiagReqData5 : 47|8@0+ (1,0) [0|255] ""  XGW_Info
 SG_ FCAM_DiagReqData6 : 55|8@0+ (1,0) [0|255] ""  XGW_Info
 SG_ FCAM_DiagReqData7 : 63|8@0+ (1,0) [0|255] ""  XGW_Info

BO_ 1687 PAS_DiagReq: 8 MHU
 SG_ PAS_DiagReqData0 : 7|8@0+ (1,0) [0|255] ""  XGW_Info
 SG_ PAS_DiagReqData1 : 15|8@0+ (1,0) [0|255] ""  XGW_Info
 SG_ PAS_DiagReqData2 : 23|8@0+ (1,0) [0|255] ""  XGW_Info
 SG_ PAS_DiagReqData3 : 31|8@0+ (1,0) [0|255] ""  XGW_Info
 SG_ PAS_DiagReqData4 : 39|8@0+ (1,0) [0|255] ""  XGW_Info
 SG_ PAS_DiagReqData5 : 47|8@0+ (1,0) [0|255] ""  XGW_Info
 SG_ PAS_DiagReqData6 : 55|8@0+ (1,0) [0|255] ""  XGW_Info
 SG_ PAS_DiagReqData7 : 63|8@0+ (1,0) [0|255] ""  XGW_Info

BO_ 1690 EDS_R_DiagReq: 8 MHU
  SG_ EDS_R_DiagReqData0 : 7|8@0+ (1,0) [0|255] "" XGW_Info
  SG_ EDS_R_DiagReqData1 : 15|8@0+ (1,0) [0|255] "-" XGW_Info
  SG_ EDS_R_DiagReqData2 : 23|8@0+ (1,0) [0|255] "" XGW_Info
  SG_ EDS_R_DiagReqData3 : 31|8@0+ (1,0) [0|255] "-" XGW_Info
  SG_ EDS_R_DiagReqData4 : 39|8@0+ (1,0) [0|255] "-" XGW_Info
  SG_ EDS_R_DiagReqData5 : 47|8@0+ (1,0) [0|255] "" XGW_Info
  SG_ EDS_R_DiagReqData6 : 55|8@0+ (1,0) [0|255] "-" XGW_Info
  SG_ EDS_R_DiagReqData7 : 63|8@0+ (1,0) [0|255] "" XGW_Info

BO_ 1691 EDS_F_DiagReq: 8 MHU
  SG_ EDS_F_DiagReqData0 : 7|8@0+ (1,0) [0|255] "-" XGW_Info
  SG_ EDS_F_DiagReqData1 : 15|8@0+ (1,0) [0|255] "" XGW_Info
  SG_ EDS_F_DiagReqData2 : 23|8@0+ (1,0) [0|255] "-" XGW_Info
  SG_ EDS_F_DiagReqData3 : 31|8@0+ (1,0) [0|255] "" XGW_Info
  SG_ EDS_F_DiagReqData4 : 39|8@0+ (1,0) [0|255] "" XGW_Info
  SG_ EDS_F_DiagReqData5 : 47|8@0+ (1,0) [0|255] "" XGW_Info
  SG_ EDS_F_DiagReqData6 : 55|8@0+ (1,0) [0|255] "" XGW_Info
  SG_ EDS_F_DiagReqData7 : 63|8@0+ (1,0) [0|255] "" XGW_Info

BO_ 1694 PSM_D_DiagReq: 8 MHU
  SG_ PSM_D_DiagReqData0 : 7|8@0+ (1,0) [0|255] "-" XGW_Info
  SG_ PSM_D_DiagReqData1 : 15|8@0+ (1,0) [0|255] "" XGW_Info
  SG_ PSM_D_DiagReqData2 : 23|8@0+ (1,0) [0|255] "-" XGW_Info
  SG_ PSM_D_DiagReqData3 : 31|8@0+ (1,0) [0|255] "" XGW_Info
  SG_ PSM_D_DiagReqData4 : 39|8@0+ (1,0) [0|255] "" XGW_Info
  SG_ PSM_D_DiagReqData5 : 47|8@0+ (1,0) [0|255] "-" XGW_Info
  SG_ PSM_D_DiagReqData6 : 55|8@0+ (1,0) [0|255] "-" XGW_Info
  SG_ PSM_D_DiagReqData7 : 63|8@0+ (1,0) [0|255] "" XGW_Info

BO_ 1701 MRGEN_DiagReq: 8 MHU
  SG_ MRGEN_DiagReqData0 : 7|8@0+ (1,0) [0|255] "" XGW_Info
  SG_ MRGEN_DiagReqData1 : 15|8@0+ (1,0) [0|255] "" XGW_Info
  SG_ MRGEN_DiagReqData2 : 23|8@0+ (1,0) [0|255] "" XGW_Info
  SG_ MRGEN_DiagReqData3 : 31|8@0+ (1,0) [0|255] "" XGW_Info
  SG_ MRGEN_DiagReqData4 : 39|8@0+ (1,0) [0|255] "" XGW_Info
  SG_ MRGEN_DiagReqData5 : 47|8@0+ (1,0) [0|255] "" XGW_Info
  SG_ MRGEN_DiagReqData6 : 55|8@0+ (1,0) [0|255] "" XGW_Info
  SG_ MRGEN_DiagReqData7 : 63|8@0+ (1,0) [0|255] "" XGW_Info

BO_ 1703 RCU_DiagReq: 8 MHU
  SG_ RCU_DiagReqData0 : 7|8@0+ (1,0) [0|255] "" XGW_Info
  SG_ RCU_DiagReqData1 : 15|8@0+ (1,0) [0|255] "" XGW_Info
  SG_ RCU_DiagReqData2 : 23|8@0+ (1,0) [0|255] "" XGW_Info
  SG_ RCU_DiagReqData3 : 31|8@0+ (1,0) [0|255] "" XGW_Info
  SG_ RCU_DiagReqData4 : 39|8@0+ (1,0) [0|255] "-" XGW_Info
  SG_ RCU_DiagReqData5 : 47|8@0+ (1,0) [0|255] "" XGW_Info
  SG_ RCU_DiagReqData6 : 55|8@0+ (1,0) [0|255] "-" XGW_Info
  SG_ RCU_DiagReqData7 : 63|8@0+ (1,0) [0|255] "-" XGW_Info

BO_ 1704 EPS_DiagReq: 8 MHU
  SG_ EPS_DiagReqData0 : 7|8@0+ (1,0) [0|255] "-" XGW_Info
  SG_ EPS_DiagReqData1 : 15|8@0+ (1,0) [0|255] "" XGW_Info
  SG_ EPS_DiagReqData2 : 23|8@0+ (1,0) [0|255] "" XGW_Info
  SG_ EPS_DiagReqData3 : 31|8@0+ (1,0) [0|255] "" XGW_Info
  SG_ EPS_DiagReqData4 : 39|8@0+ (1,0) [0|255] "-" XGW_Info
  SG_ EPS_DiagReqData5 : 47|8@0+ (1,0) [0|255] "-" XGW_Info
  SG_ EPS_DiagReqData6 : 55|8@0+ (1,0) [0|255] "-" XGW_Info
  SG_ EPS_DiagReqData7 : 63|8@0+ (1,0) [0|255] "" XGW_Info

BO_ 1705 IDB_DiagReq: 8 MHU
  SG_ IDB_DiagReqData0 : 7|8@0+ (1,0) [0|255] "" XGW_Info
  SG_ IDB_DiagReqData1 : 15|8@0+ (1,0) [0|255] "" XGW_Info
  SG_ IDB_DiagReqData2 : 23|8@0+ (1,0) [0|255] "" XGW_Info
  SG_ IDB_DiagReqData3 : 31|8@0+ (1,0) [0|255] "" XGW_Info
  SG_ IDB_DiagReqData4 : 39|8@0+ (1,0) [0|255] "" XGW_Info
  SG_ IDB_DiagReqData5 : 47|8@0+ (1,0) [0|255] "" XGW_Info
  SG_ IDB_DiagReqData6 : 55|8@0+ (1,0) [0|255] "-" XGW_Info
  SG_ IDB_DiagReqData7 : 63|8@0+ (1,0) [0|255] "" XGW_Info

BO_ 1706 AVAS_DiagReq: 8 MHU
  SG_ AVAS_DiagReqData0 : 7|8@0+ (1,0) [0|255] "-" XGW_Info
  SG_ AVAS_DiagReqData1 : 15|8@0+ (1,0) [0|255] "" XGW_Info
  SG_ AVAS_DiagReqData2 : 23|8@0+ (1,0) [0|255] "" XGW_Info
  SG_ AVAS_DiagReqData3 : 31|8@0+ (1,0) [0|255] "-" XGW_Info
  SG_ AVAS_DiagReqData4 : 39|8@0+ (1,0) [0|255] "" XGW_Info
  SG_ AVAS_DiagReqData5 : 47|8@0+ (1,0) [0|255] "" XGW_Info
  SG_ AVAS_DiagReqData6 : 55|8@0+ (1,0) [0|255] "" XGW_Info
  SG_ AVAS_DiagReqData7 : 63|8@0+ (1,0) [0|255] "" XGW_Info

BO_ 1707 EPS2_DiagReq: 8 MHU
  SG_ EPS2_DiagReqData0 : 7|8@0+ (1,0) [0|255] "" XGW_Info
  SG_ EPS2_DiagReqData1 : 15|8@0+ (1,0) [0|255] "" XGW_Info
  SG_ EPS2_DiagReqData2 : 23|8@0+ (1,0) [0|255] "" XGW_Info
  SG_ EPS2_DiagReqData3 : 31|8@0+ (1,0) [0|255] "-" XGW_Info
  SG_ EPS2_DiagReqData4 : 39|8@0+ (1,0) [0|255] "" XGW_Info
  SG_ EPS2_DiagReqData5 : 47|8@0+ (1,0) [0|255] "-" XGW_Info
  SG_ EPS2_DiagReqData6 : 55|8@0+ (1,0) [0|255] "" XGW_Info
  SG_ EPS2_DiagReqData7 : 63|8@0+ (1,0) [0|255] "" XGW_Info

BO_ 1708 VCU_DiagReq: 8 MHU
  SG_ VCU_DiagReqData0 : 7|8@0+ (1,0) [0|255] "-" XGW_Info
  SG_ VCU_DiagReqData1 : 15|8@0+ (1,0) [0|255] "" XGW_Info
  SG_ VCU_DiagReqData2 : 23|8@0+ (1,0) [0|255] "-" XGW_Info
  SG_ VCU_DiagReqData3 : 31|8@0+ (1,0) [0|255] "" XGW_Info
  SG_ VCU_DiagReqData4 : 39|8@0+ (1,0) [0|255] "" XGW_Info
  SG_ VCU_DiagReqData5 : 47|8@0+ (1,0) [0|255] "-" XGW_Info
  SG_ VCU_DiagReqData6 : 55|8@0+ (1,0) [0|255] "" XGW_Info
  SG_ VCU_DiagReqData7 : 63|8@0+ (1,0) [0|255] "-" XGW_Info

BO_ 1710 EASC_DiagReq: 8 XGW_Info
  SG_ EASC_DiagReqData0 : 7|8@0+ (1,0) [0|255] "" EASC
  SG_ EASC_DiagReqData1 : 15|8@0+ (1,0) [0|255] "-" EASC
  SG_ EASC_DiagReqData2 : 23|8@0+ (1,0) [0|255] "-" EASC
  SG_ EASC_DiagReqData3 : 31|8@0+ (1,0) [0|255] "" EASC
  SG_ EASC_DiagReqData4 : 39|8@0+ (1,0) [0|255] "-" EASC
  SG_ EASC_DiagReqData5 : 47|8@0+ (1,0) [0|255] "-" EASC
  SG_ EASC_DiagReqData6 : 55|8@0+ (1,0) [0|255] "" EASC
  SG_ EASC_DiagReqData7 : 63|8@0+ (1,0) [0|255] "-" EASC

BO_ 1711 CPD_DiagReq: 8 XGW_Info
  SG_ CPD_DiagReqData0 : 7|8@0+ (1,0) [0|255] "-" CPD
  SG_ CPD_DiagReqData1 : 15|8@0+ (1,0) [0|255] "-" CPD
  SG_ CPD_DiagReqData2 : 23|8@0+ (1,0) [0|255] "-" CPD
  SG_ CPD_DiagReqData3 : 31|8@0+ (1,0) [0|255] "" CPD
  SG_ CPD_DiagReqData4 : 39|8@0+ (1,0) [0|255] "-" CPD
  SG_ CPD_DiagReqData5 : 47|8@0+ (1,0) [0|255] "" CPD
  SG_ CPD_DiagReqData6 : 55|8@0+ (1,0) [0|255] "-" CPD
  SG_ CPD_DiagReqData7 : 63|8@0+ (1,0) [0|255] "-" CPD

BO_ 1712 PAS_LITE_DiagReq: 8 XGW_Info
  SG_ PAS_LITE_DiagReqData0 : 7|8@0+ (1,0) [0|255] ""  PAS_LITE
  SG_ PAS_LITE_DiagReqData1 : 15|8@0+ (1,0) [0|255] ""  PAS_LITE
  SG_ PAS_LITE_DiagReqData2 : 23|8@0+ (1,0) [0|255] ""  PAS_LITE
  SG_ PAS_LITE_DiagReqData3 : 31|8@0+ (1,0) [0|255] ""  PAS_LITE
  SG_ PAS_LITE_DiagReqData4 : 39|8@0+ (1,0) [0|255] ""  PAS_LITE
  SG_ PAS_LITE_DiagReqData5 : 47|8@0+ (1,0) [0|255] ""  PAS_LITE
  SG_ PAS_LITE_DiagReqData6 : 55|8@0+ (1,0) [0|255] ""  PAS_LITE
  SG_ PAS_LITE_DiagReqData7 : 63|8@0+ (1,0) [0|255] ""  PAS_LITE

BO_ 1716 SRR_FR_DiagReq: 8 MHU
  SG_ SRR_FR_DiagReqData0 : 7|8@0+ (1,0) [0|255] "" XGW_Info
  SG_ SRR_FR_DiagReqData1 : 15|8@0+ (1,0) [0|255] "" XGW_Info
  SG_ SRR_FR_DiagReqData2 : 23|8@0+ (1,0) [0|255] "" XGW_Info
  SG_ SRR_FR_DiagReqData3 : 31|8@0+ (1,0) [0|255] "" XGW_Info
  SG_ SRR_FR_DiagReqData4 : 39|8@0+ (1,0) [0|255] "" XGW_Info
  SG_ SRR_FR_DiagReqData5 : 47|8@0+ (1,0) [0|255] "" XGW_Info
  SG_ SRR_FR_DiagReqData6 : 55|8@0+ (1,0) [0|255] "" XGW_Info
  SG_ SRR_FR_DiagReqData7 : 63|8@0+ (1,0) [0|255] "" XGW_Info

BO_ 1717 SRR_FL_DiagReq: 8 MHU
  SG_ SRR_FL_DiagReqData0 : 7|8@0+ (1,0) [0|255] "" XGW_Info
  SG_ SRR_FL_DiagReqData1 : 15|8@0+ (1,0) [0|255] "" XGW_Info
  SG_ SRR_FL_DiagReqData2 : 23|8@0+ (1,0) [0|255] "" XGW_Info
  SG_ SRR_FL_DiagReqData3 : 31|8@0+ (1,0) [0|255] "" XGW_Info
  SG_ SRR_FL_DiagReqData4 : 39|8@0+ (1,0) [0|255] "" XGW_Info
  SG_ SRR_FL_DiagReqData5 : 47|8@0+ (1,0) [0|255] "" XGW_Info
  SG_ SRR_FL_DiagReqData6 : 55|8@0+ (1,0) [0|255] "" XGW_Info
  SG_ SRR_FL_DiagReqData7 : 63|8@0+ (1,0) [0|255] "" XGW_Info

BO_ 1718 SRR_RR_DiagReq: 8 MHU
  SG_ SRR_RR_DiagReqData0 : 7|8@0+ (1,0) [0|255] "" XGW_Info
  SG_ SRR_RR_DiagReqData1 : 15|8@0+ (1,0) [0|255] "" XGW_Info
  SG_ SRR_RR_DiagReqData2 : 23|8@0+ (1,0) [0|255] "" XGW_Info
  SG_ SRR_RR_DiagReqData3 : 31|8@0+ (1,0) [0|255] "" XGW_Info
  SG_ SRR_RR_DiagReqData4 : 39|8@0+ (1,0) [0|255] "" XGW_Info
  SG_ SRR_RR_DiagReqData5 : 47|8@0+ (1,0) [0|255] "" XGW_Info
  SG_ SRR_RR_DiagReqData6 : 55|8@0+ (1,0) [0|255] "" XGW_Info
  SG_ SRR_RR_DiagReqData7 : 63|8@0+ (1,0) [0|255] "" XGW_Info

BO_ 1719 SRR_RL_DiagReq: 8 MHU
  SG_ SRR_RL_DiagReqData0 : 7|8@0+ (1,0) [0|255] "" XGW_Info
  SG_ SRR_RL_DiagReqData1 : 15|8@0+ (1,0) [0|255] "" XGW_Info
  SG_ SRR_RL_DiagReqData2 : 23|8@0+ (1,0) [0|255] "" XGW_Info
  SG_ SRR_RL_DiagReqData3 : 31|8@0+ (1,0) [0|255] "" XGW_Info
  SG_ SRR_RL_DiagReqData4 : 39|8@0+ (1,0) [0|255] "" XGW_Info
  SG_ SRR_RL_DiagReqData5 : 47|8@0+ (1,0) [0|255] "" XGW_Info
  SG_ SRR_RL_DiagReqData6 : 55|8@0+ (1,0) [0|255] "" XGW_Info
  SG_ SRR_RL_DiagReqData7 : 63|8@0+ (1,0) [0|255] "" XGW_Info

BO_ 1721 SRR_RR_M_DiagReq: 8 MHU
  SG_ SRR_RR_M_DiagReq_Data0 : 7|8@0+ (1,0) [0|255] "" XGW_Info
  SG_ SRR_RR_M_DiagReq_Data1 : 15|8@0+ (1,0) [0|255] "" XGW_Info
  SG_ SRR_RR_M_DiagReq_Data2 : 23|8@0+ (1,0) [0|255] "" XGW_Info
  SG_ SRR_RR_M_DiagReq_Data3 : 31|8@0+ (1,0) [0|255] "" XGW_Info
  SG_ SRR_RR_M_DiagReq_Data4 : 39|8@0+ (1,0) [0|255] "" XGW_Info
  SG_ SRR_RR_M_DiagReq_Data5 : 47|8@0+ (1,0) [0|255] "" XGW_Info
  SG_ SRR_RR_M_DiagReq_Data6 : 55|8@0+ (1,0) [0|255] "" XGW_Info
  SG_ SRR_RR_M_DiagReq_Data7 : 63|8@0+ (1,0) [0|255] "" XGW_Info

BO_ 1723 TRM_DiagReq: 8 MHU
  SG_ TRM_DiagReqData0 : 7|8@0+ (1,0) [0|255] "" XGW_Info
  SG_ TRM_DiagReqData1 : 15|8@0+ (1,0) [0|255] "" XGW_Info
  SG_ TRM_DiagReqData2 : 23|8@0+ (1,0) [0|255] "-" XGW_Info
  SG_ TRM_DiagReqData3 : 31|8@0+ (1,0) [0|255] "-" XGW_Info
  SG_ TRM_DiagReqData4 : 39|8@0+ (1,0) [0|255] "-" XGW_Info
  SG_ TRM_DiagReqData5 : 47|8@0+ (1,0) [0|255] "" XGW_Info
  SG_ TRM_DiagReqData6 : 55|8@0+ (1,0) [0|255] "" XGW_Info
  SG_ TRM_DiagReqData7 : 63|8@0+ (1,0) [0|255] "-" XGW_Info

BO_ 1725 POD_DCDC_DiagReq: 8 MHU
  SG_ POD_DCDC_DiagReqData0 : 7|8@0+ (1,0) [0|255] "" XGW_Info
  SG_ POD_DCDC_DiagReqData1 : 15|8@0+ (1,0) [0|255] "" XGW_Info
  SG_ POD_DCDC_DiagReqData2 : 23|8@0+ (1,0) [0|255] "-" XGW_Info
  SG_ POD_DCDC_DiagReqData3 : 31|8@0+ (1,0) [0|255] "" XGW_Info
  SG_ POD_DCDC_DiagReqData4 : 39|8@0+ (1,0) [0|255] "-" XGW_Info
  SG_ POD_DCDC_DiagReqData5 : 47|8@0+ (1,0) [0|255] "-" XGW_Info
  SG_ POD_DCDC_DiagReqData6 : 55|8@0+ (1,0) [0|255] "" XGW_Info
  SG_ POD_DCDC_DiagReqData7 : 63|8@0+ (1,0) [0|255] "" XGW_Info

BO_ 1726 POD_OBC_DiagReq: 8 MHU
  SG_ POD_OBC_DiagReqData0 : 7|8@0+ (1,0) [0|255] "" XGW_Info
  SG_ POD_OBC_DiagReqData1 : 15|8@0+ (1,0) [0|255] "" XGW_Info
  SG_ POD_OBC_DiagReqData2 : 23|8@0+ (1,0) [0|255] "" XGW_Info
  SG_ POD_OBC_DiagReqData3 : 31|8@0+ (1,0) [0|255] "-" XGW_Info
  SG_ POD_OBC_DiagReqData4 : 39|8@0+ (1,0) [0|255] "" XGW_Info
  SG_ POD_OBC_DiagReqData5 : 47|8@0+ (1,0) [0|255] "" XGW_Info
  SG_ POD_OBC_DiagReqData6 : 55|8@0+ (1,0) [0|255] "" XGW_Info
  SG_ POD_OBC_DiagReqData7 : 63|8@0+ (1,0) [0|255] "-" XGW_Info

BO_ 1727 POD_GW_Request: 8 MHU
  SG_ POD_DiagReqData0 : 7|8@0+ (1,0) [0|255] "-" XGW_Info
  SG_ POD_DiagReqData1 : 15|8@0+ (1,0) [0|255] "" XGW_Info
  SG_ POD_DiagReqData2 : 23|8@0+ (1,0) [0|255] "" XGW_Info
  SG_ POD_DiagReqData3 : 31|8@0+ (1,0) [0|255] "" XGW_Info
  SG_ POD_DiagReqData4 : 39|8@0+ (1,0) [0|255] "" XGW_Info
  SG_ POD_DiagReqData5 : 47|8@0+ (1,0) [0|255] "" XGW_Info
  SG_ POD_DiagReqData6 : 55|8@0+ (1,0) [0|255] "" XGW_Info
  SG_ POD_DiagReqData7 : 63|8@0+ (1,0) [0|255] "" XGW_Info

BO_ 1729 APM_DiagReq: 8 MHU
  SG_ APM_DiagReqData0 : 7|8@0+ (1,0) [0|255] "" XGW_Info
  SG_ APM_DiagReqData1 : 15|8@0+ (1,0) [0|255] "" XGW_Info
  SG_ APM_DiagReqData2 : 23|8@0+ (1,0) [0|255] "-" XGW_Info
  SG_ APM_DiagReqData3 : 31|8@0+ (1,0) [0|255] "" XGW_Info
  SG_ APM_DiagReqData4 : 39|8@0+ (1,0) [0|255] "" XGW_Info
  SG_ APM_DiagReqData5 : 47|8@0+ (1,0) [0|255] "-" XGW_Info
  SG_ APM_DiagReqData6 : 55|8@0+ (1,0) [0|255] "" XGW_Info
  SG_ APM_DiagReqData7 : 63|8@0+ (1,0) [0|255] "" XGW_Info

BO_ 1730 SHVU_F_DiagReq: 8 MHU
  SG_ SHVU_F_DiagReqData0 : 7|8@0+ (1,0) [0|255] "" XGW_Info
  SG_ SHVU_F_DiagReqData1 : 15|8@0+ (1,0) [0|255] "" XGW_Info
  SG_ SHVU_F_DiagReqData2 : 23|8@0+ (1,0) [0|255] "" XGW_Info
  SG_ SHVU_F_DiagReqData3 : 31|8@0+ (1,0) [0|255] "-" XGW_Info
  SG_ SHVU_F_DiagReqData4 : 39|8@0+ (1,0) [0|255] "" XGW_Info
  SG_ SHVU_F_DiagReqData5 : 47|8@0+ (1,0) [0|255] "" XGW_Info
  SG_ SHVU_F_DiagReqData6 : 55|8@0+ (1,0) [0|255] "-" XGW_Info
  SG_ SHVU_F_DiagReqData7 : 63|8@0+ (1,0) [0|255] "" XGW_Info

BO_ 1731 SHVU_R_DiagReq: 8 MHU
  SG_ SHVU_R_DiagReqData0 : 7|8@0+ (1,0) [0|255] "" XGW_Info
  SG_ SHVU_R_DiagReqData1 : 15|8@0+ (1,0) [0|255] "" XGW_Info
  SG_ SHVU_R_DiagReqData2 : 23|8@0+ (1,0) [0|255] "" XGW_Info
  SG_ SHVU_R_DiagReqData3 : 31|8@0+ (1,0) [0|255] "" XGW_Info
  SG_ SHVU_R_DiagReqData4 : 39|8@0+ (1,0) [0|255] "" XGW_Info
  SG_ SHVU_R_DiagReqData5 : 47|8@0+ (1,0) [0|255] "-" XGW_Info
  SG_ SHVU_R_DiagReqData6 : 55|8@0+ (1,0) [0|255] "" XGW_Info
  SG_ SHVU_R_DiagReqData7 : 63|8@0+ (1,0) [0|255] "" XGW_Info

BO_ 1732 OCS_P_DiagReq: 8 MHU
  SG_ OCS_P_DiagReqData0 : 7|8@0+ (1,0) [0|255] "-" XGW_Info
  SG_ OCS_P_DiagReqData1 : 15|8@0+ (1,0) [0|255] "" XGW_Info
  SG_ OCS_P_DiagReqData2 : 23|8@0+ (1,0) [0|255] "" XGW_Info
  SG_ OCS_P_DiagReqData3 : 31|8@0+ (1,0) [0|255] "" XGW_Info
  SG_ OCS_P_DiagReqData4 : 39|8@0+ (1,0) [0|255] "" XGW_Info
  SG_ OCS_P_DiagReqData5 : 47|8@0+ (1,0) [0|255] "" XGW_Info
  SG_ OCS_P_DiagReqData6 : 55|8@0+ (1,0) [0|255] "" XGW_Info
  SG_ OCS_P_DiagReqData7 : 63|8@0+ (1,0) [0|255] "-" XGW_Info

BO_ 1737 LDM_L_DiagReq: 8 MHU
  SG_ LDM_L_DiagReqData0 : 7|8@0+ (1,0) [0|255] "-" XGW_Info
  SG_ LDM_L_DiagReqData1 : 15|8@0+ (1,0) [0|255] "" XGW_Info
  SG_ LDM_L_DiagReqData2 : 23|8@0+ (1,0) [0|255] "" XGW_Info
  SG_ LDM_L_DiagReqData3 : 31|8@0+ (1,0) [0|255] "" XGW_Info
  SG_ LDM_L_DiagReqData4 : 39|8@0+ (1,0) [0|255] "-" XGW_Info
  SG_ LDM_L_DiagReqData5 : 47|8@0+ (1,0) [0|255] "" XGW_Info
  SG_ LDM_L_DiagReqData6 : 55|8@0+ (1,0) [0|255] "" XGW_Info
  SG_ LDM_L_DiagReqData7 : 63|8@0+ (1,0) [0|255] "" XGW_Info

BO_ 1738 LDM_R_DiagReq: 8 MHU
  SG_ LDM_R_DiagReqData0 : 7|8@0+ (1,0) [0|255] "" XGW_Info
  SG_ LDM_R_DiagReqData1 : 15|8@0+ (1,0) [0|255] "" XGW_Info
  SG_ LDM_R_DiagReqData2 : 23|8@0+ (1,0) [0|255] "" XGW_Info
  SG_ LDM_R_DiagReqData3 : 31|8@0+ (1,0) [0|255] "-" XGW_Info
  SG_ LDM_R_DiagReqData4 : 39|8@0+ (1,0) [0|255] "" XGW_Info
  SG_ LDM_R_DiagReqData5 : 47|8@0+ (1,0) [0|255] "" XGW_Info
  SG_ LDM_R_DiagReqData6 : 55|8@0+ (1,0) [0|255] "-" XGW_Info
  SG_ LDM_R_DiagReqData7 : 63|8@0+ (1,0) [0|255] "-" XGW_Info

BO_ 1752 BAS_DiagReq: 8 MHU
  SG_ BAS_DiagReqData0 : 7|8@0+ (1,0) [0|255] "" XGW_Info
  SG_ BAS_DiagReqData1 : 15|8@0+ (1,0) [0|255] "" XGW_Info
  SG_ BAS_DiagReqData2 : 23|8@0+ (1,0) [0|255] "" XGW_Info
  SG_ BAS_DiagReqData3 : 31|8@0+ (1,0) [0|255] "-" XGW_Info
  SG_ BAS_DiagReqData4 : 39|8@0+ (1,0) [0|255] "" XGW_Info
  SG_ BAS_DiagReqData5 : 47|8@0+ (1,0) [0|255] "" XGW_Info
  SG_ BAS_DiagReqData6 : 55|8@0+ (1,0) [0|255] "-" XGW_Info
  SG_ BAS_DiagReqData7 : 63|8@0+ (1,0) [0|255] "-" XGW_Info

BO_ 1764 DCM_APM_DiagReq: 8 MHU
  SG_ DCM_APM_DiagReqData0 : 7|8@0+ (1,0) [0|255] "-" XGW_Info
  SG_ DCM_APM_DiagReqData1 : 15|8@0+ (1,0) [0|255] "-" XGW_Info
  SG_ DCM_APM_DiagReqData2 : 23|8@0+ (1,0) [0|255] "-" XGW_Info
  SG_ DCM_APM_DiagReqData3 : 31|8@0+ (1,0) [0|255] "-" XGW_Info
  SG_ DCM_APM_DiagReqData4 : 39|8@0+ (1,0) [0|255] "" XGW_Info
  SG_ DCM_APM_DiagReqData5 : 47|8@0+ (1,0) [0|255] "" XGW_Info
  SG_ DCM_APM_DiagReqData6 : 55|8@0+ (1,0) [0|255] "" XGW_Info
  SG_ DCM_APM_DiagReqData7 : 63|8@0+ (1,0) [0|255] "" XGW_Info

BO_ 1774 MHU_FOTA_ReqAll: 8 MHU
  SG_ MHU_FOTA_ReqAll_00 : 7|8@0+ (1,0) [0|255] "-" XGW_Info
  SG_ MHU_FOTA_ReqAll_01 : 15|8@0+ (1,0) [0|255] "-" XGW_Info
  SG_ MHU_FOTA_ReqAll_02 : 23|8@0+ (1,0) [0|255] "-" XGW_Info
  SG_ MHU_FOTA_ReqAll_03 : 31|8@0+ (1,0) [0|255] "-" XGW_Info
  SG_ MHU_FOTA_ReqAll_04 : 39|8@0+ (1,0) [0|255] "-" XGW_Info
  SG_ MHU_FOTA_ReqAll_05 : 47|8@0+ (1,0) [0|255] "-" XGW_Info
  SG_ MHU_FOTA_ReqAll_06 : 55|8@0+ (1,0) [0|255] "-" XGW_Info
  SG_ MHU_FOTA_ReqAll_07 : 63|8@0+ (1,0) [0|255] "-" XGW_Info

BO_ 1777 ASU_DiagReq: 8 MHU
  SG_ ASU_DiagReqData0 : 7|8@0+ (1,0) [0|255] "-" XGW_Info
  SG_ ASU_DiagReqData1 : 15|8@0+ (1,0) [0|255] "-" XGW_Info
  SG_ ASU_DiagReqData2 : 23|8@0+ (1,0) [0|255] "-" XGW_Info
  SG_ ASU_DiagReqData3 : 31|8@0+ (1,0) [0|255] "-" XGW_Info
  SG_ ASU_DiagReqData4 : 39|8@0+ (1,0) [0|255] "-" XGW_Info
  SG_ ASU_DiagReqData5 : 47|8@0+ (1,0) [0|255] "-" XGW_Info
  SG_ ASU_DiagReqData6 : 55|8@0+ (1,0) [0|255] "-" XGW_Info
  SG_ ASU_DiagReqData7 : 63|8@0+ (1,0) [0|255] "-" XGW_Info

BO_ 1787 BCM_BPM_DiagReq: 8 MHU
  SG_ BCM_BPM_DiagReqData0 : 7|8@0+ (1,0) [0|255] "-" XGW_Info
  SG_ BCM_BPM_DiagReqData1 : 15|8@0+ (1,0) [0|255] "" XGW_Info
  SG_ BCM_BPM_DiagReqData2 : 23|8@0+ (1,0) [0|255] "" XGW_Info
  SG_ BCM_BPM_DiagReqData3 : 31|8@0+ (1,0) [0|255] "" XGW_Info
  SG_ BCM_BPM_DiagReqData4 : 39|8@0+ (1,0) [0|255] "" XGW_Info
  SG_ BCM_BPM_DiagReqData5 : 47|8@0+ (1,0) [0|255] "" XGW_Info
  SG_ BCM_BPM_DiagReqData6 : 55|8@0+ (1,0) [0|255] "-" XGW_Info
  SG_ BCM_BPM_DiagReqData7 : 63|8@0+ (1,0) [0|255] "-" XGW_Info

BO_ 1791 DIAG_Req_All_Ecu: 8 XGW_Info
  SG_ DiagReqAllEcuData0 : 7|8@0+ (1,0) [0|255] "-" AMP,CPD,EASC,HUD,MHU
  SG_ DiagReqAllEcuData1 : 15|8@0+ (1,0) [0|255] "" AMP,CPD,EASC,HUD,MHU
  SG_ DiagReqAllEcuData2 : 23|8@0+ (1,0) [0|255] "" AMP,CPD,EASC,HUD,MHU
  SG_ DiagReqAllEcuData3 : 31|8@0+ (1,0) [0|255] "" AMP,CPD,EASC,HUD,MHU
  SG_ DiagReqAllEcuData4 : 39|8@0+ (1,0) [0|255] "-" AMP,CPD,EASC,HUD,MHU
  SG_ DiagReqAllEcuData5 : 47|8@0+ (1,0) [0|255] "" AMP,CPD,EASC,HUD,MHU
  SG_ DiagReqAllEcuData6 : 55|8@0+ (1,0) [0|255] "" AMP,CPD,EASC,HUD,MHU
  SG_ DiagReqAllEcuData7 : 63|8@0+ (1,0) [0|255] "" AMP,CPD,EASC,HUD,MHU

BO_ 1803 SEED_CAN_Req6_BCM: 8 XGW_Info
  SG_ SEED_CAN_Req6 : 7|64@0+ (1,0) [0|1.84467440737096E+019] "" MHU,FCAM_Info,PAS_Info

BO_ 1805 SEED_CAN_Req7_VCU_PT: 8 XGW_Info
  SG_ SEED_CAN_Req7 : 7|64@0+ (1,0) [0|1.84467440737096E+019] "" MHU, PAS_Info

BO_ 1841 SEED_CAN_Req17_HUD: 8 HUD
  SG_ SEED_CAN_Req17 : 7|64@0+ (1,0) [0|1.84467440737096E+019] "" MHU

BO_ 1843 SEED_CAN_Req18_MHU: 8 MHU
  SG_ SEED_CAN_Req18 : 7|64@0+ (1,0) [0|1.84467440737096E+019] "" Vector__XXX,EASC,HUD,XGW_Info,PAS_Info,FCAM_Info

BO_ 1845 SEED_CAN_Req20_EASC: 8 EASC
  SG_ SEED_CAN_Req20 : 7|64@0+ (1,0) [0|1.84467440737096E+019] "" MHU

BO_ 1847 SEED_CAN_Req21_ETG: 8 XGW_Info
  SG_ SEED_CAN_Req21 : 7|64@0+ (1,0) [0|1.84467440737096E+019] "" MHU

BO_ 1850 SEED_CAN_Req25_FCAM: 8 FCAM_Info
 SG_ SEED_CAN_Req25 : 7|64@0+ (1,0) [0|1.84467440737096E+019] ""  MHU,XGW_Info

BO_ 1853 SEED_CAN_Req29_PAS: 8 PAS_Info
 SG_ SEED_CAN_Req29 : 7|64@0+ (1,0) [0|1.84467440737096E+019] ""  MHU, XGW_Info

BO_ 1873 VCU_DebugDiag: 8 XGW_Info
  SG_ VCU_DebugDiag2 : 4|3@0+ (1,0) [0|4] "" MHU
  SG_ VCU_DebugDiag1 : 7|3@0+ (1,0) [0|4] "" MHU
  SG_ VCU_DebugDiag5 : 9|3@0+ (1,0) [0|4] "" MHU
  SG_ VCU_DebugDiag4 : 12|3@0+ (1,0) [0|4] "" MHU
  SG_ VCU_DebugDiag3 : 15|3@0+ (1,0) [0|4] "" MHU
  SG_ VCU_DebugDiag8 : 16|3@0+ (1,0) [0|4] "" MHU
  SG_ VCU_DebugDiag7 : 19|3@0+ (1,0) [0|4] "" MHU
  SG_ VCU_DebugDiag6 : 22|3@0+ (1,0) [0|4] "" MHU
  SG_ VCU_DebugDiag10 : 26|3@0+ (1,0) [0|4] "" MHU
  SG_ VCU_DebugDiag9 : 29|3@0+ (1,0) [0|4] "" MHU
  SG_ VCU_DebugDiag13 : 33|3@0+ (1,0) [0|4] "" MHU
  SG_ VCU_DebugDiag12 : 36|3@0+ (1,0) [0|4] "" MHU
  SG_ VCU_DebugDiag11 : 39|3@0+ (1,0) [0|4] "" MHU
  SG_ VCU_DebugDiag16 : 40|3@0+ (1,0) [0|4] "" MHU
  SG_ VCU_DebugDiag15 : 43|3@0+ (1,0) [0|4] "" MHU
  SG_ VCU_DebugDiag14 : 46|3@0+ (1,0) [0|4] "" MHU
  SG_ VCU_DebugDiag18 : 50|3@0+ (1,0) [0|4] "" MHU
  SG_ VCU_DebugDiag17 : 53|3@0+ (1,0) [0|4] "" MHU
  SG_ VCU_DebugDiag20 : 60|3@0+ (1,0) [0|4] "" MHU
  SG_ VCU_DebugDiag19 : 63|3@0+ (1,0) [0|4] "" MHU

BO_ 2015 Diag_Request_ECU: 8 XGW_Info
  SG_ Diag_Request_ECU_Data0 : 7|8@0+ (1,0) [0|255] "" AMP,CPD,EASC,HUD,MHU
  SG_ Diag_Request_ECU_Data1 : 15|8@0+ (1,0) [0|255] "-" AMP,CPD,EASC,HUD,MHU
  SG_ Diag_Request_ECU_Data2 : 23|8@0+ (1,0) [0|255] "-" AMP,CPD,EASC,HUD,MHU
  SG_ Diag_Request_ECU_Data3 : 31|8@0+ (1,0) [0|255] "" AMP,CPD,EASC,HUD,MHU
  SG_ Diag_Request_ECU_Data4 : 39|8@0+ (1,0) [0|255] "-" AMP,CPD,EASC,HUD,MHU
  SG_ Diag_Request_ECU_Data5 : 47|8@0+ (1,0) [0|255] "" AMP,CPD,EASC,HUD,MHU
  SG_ Diag_Request_ECU_Data6 : 55|8@0+ (1,0) [0|255] "-" AMP,CPD,EASC,HUD,MHU
  SG_ Diag_Request_ECU_Data7 : 63|8@0+ (1,0) [0|255] "" AMP,CPD,EASC,HUD,MHU

BO_ 287 MHU_BCM_Ctrl: 8 MHU
 SG_ MHU_DrvInhibitSts : 13|2@0+ (1,0) [0|3] "" XGW_Info
 SG_ TBOX_AuthCode_0x11F : 55|16@0+ (1,0) [0|65535] "" XGW_Info

BO_ 280 BCM_MHU_Ctrl_Fbk: 8 XGW_Info
 SG_ CHKSM_BCM_MHU_Ctrl_Fbk : 7|8@0+ (1,0) [0|255] "" MHU
 SG_ ALV_BCM_MHU_Ctrl_Fbk : 11|4@0+ (1,0) [0|14] "" MHU
 SG_ BCM_DrvInhibitStsFbk : 13|2@0+ (1,0) [0|3] "" MHU

CM_ BO_ 1555 "BMS Diagnostic Responde";
CM_ BO_ 1556 "CCUR Diagnostic Response";
CM_ BO_ 1558 "FCAM Diagnostic Response";
CM_ BO_ 1559 "PAS Diagnostic Response";
CM_ BO_ 1562 "EDS Rear Diagnostic Responde";
CM_ BO_ 1563 "EDS Front Diagnostic Responde";
CM_ BO_ 1566 "PSM D DiagResp";
CM_ BO_ 1573 "MRGEN_DiagResp";
CM_ BO_ 1575 "Diagnostic Response for RCU     ";
CM_ BO_ 1576 "Diagnostic response";
CM_ BO_ 1577 "IDB Diagnostic Response";
CM_ BO_ 1578 "AVAS Diagnostic Responde";
CM_ BO_ 1579 "Diagnostic Response for EPS2     ";
CM_ BO_ 1580 "VCU Diagnostic Responde";
CM_ BO_ 1582 "EASC DiagResp";
CM_ BO_ 1583 "CPD DiagResp";
CM_ BO_ 1584 "PAS_LITE DiagResp";
CM_ BO_ 1588 "SRR FR Diagnostic Response";
CM_ BO_ 1589 "SRR FL Diagnostic Response";
CM_ BO_ 1590 "SRR RR Diagnostic Response";
CM_ BO_ 1591 "SRR RL Diagnostic Response";
CM_ BO_ 1592 "ASU Diagnostic Response";
CM_ BO_ 1593 "SRR RR M Diagnostic Response";
CM_ BO_ 1595 "TRM DiagResp";
CM_ BO_ 1597 "POD DCDC Diagnostic Response";
CM_ BO_ 1598 "POD OBC Diagnostic Response";
CM_ BO_ 1599 "POD Diagnostic Response";
CM_ BO_ 1601 "APM DiagResp";
CM_ BO_ 1602 "SHVU F DiagResp";
CM_ BO_ 1603 "SHVU R DiagResp";
CM_ BO_ 1604 "OCS_P_DiagResp";
CM_ BO_ 1609 "LDM_L DiagResp";
CM_ BO_ 1610 "LDM_R DiagResp";
CM_ BO_ 1624 "BAS DiagResp";
CM_ BO_ 1636 "DCM_APM_DiagResp";
CM_ BO_ 1659 "BCM_BPM Diagnostic Response";
CM_ BO_ 1665 "BCM DiagReq";
CM_ BO_ 1666 "XGW DiagReq";
CM_ BO_ 1668 "MHU DiagReq";
CM_ BO_ 1669 "AMP DiagReq";
CM_ BO_ 1672 "ACM DiagReq";
CM_ BO_ 1673 "CCU DiagReq";
CM_ BO_ 1677 "HUD DiagReq";
CM_ BO_ 1678 "ETG DiagReq";
CM_ BO_ 1679 "Diagnostic Request for YSS     ";
CM_ BO_ 1680 "GS Diagnostic Request";
CM_ BO_ 1683 "BMS Diagnostic Request";
CM_ BO_ 1684 "CCUR Diagnostic Request";
CM_ BO_ 1686 "FCAM Diagnostic Request";
CM_ BO_ 1687 "PAS Diagnostic Request";
CM_ BO_ 1690 "EDS Rear Diagnostic Request";
CM_ BO_ 1691 "EDS Front Diagnostic Request";
CM_ BO_ 1694 "PSM D DiagReq";
CM_ BO_ 1701 "MRGEN_DiagReq";
CM_ BO_ 1703 "Diagnostic Request for RCU     ";
CM_ BO_ 1704 "Diagnostic request";
CM_ BO_ 1705 "IDB Diagnostic Request";
CM_ BO_ 1706 "AVAS Diagnostic Request";
CM_ BO_ 1707 "Diagnostic Request for EPS2     ";
CM_ BO_ 1708 "VCU Diagnostic Request";
CM_ BO_ 1710 "EASC DiagReq";
CM_ BO_ 1711 "CPD DiagReq";
CM_ BO_ 1712 "PAS_LITE DiagReq";
CM_ BO_ 1716 "SRR FR Diagnostic Request";
CM_ BO_ 1717 "SRR FL Diagnostic Request";
CM_ BO_ 1718 "SRR RR Diagnostic Request";
CM_ BO_ 1719 "SRR RL Diagnostic Request";
CM_ BO_ 1721 "SRR RR M Diagnostic Request";
CM_ BO_ 1723 "TRM DiagReq";
CM_ BO_ 1725 "POD DCDC Diagnostic Request";
CM_ BO_ 1726 "POD OBC Diagnostic Request";
CM_ BO_ 1727 "POD Diagnostic Request";
CM_ BO_ 1729 "APM DiagReq";
CM_ BO_ 1730 "SHVU F DiagReq";
CM_ BO_ 1731 "SHVU R DiagReq";
CM_ BO_ 1732 "OCS P DiagReq";
CM_ BO_ 1737 "LDM_L DiagReq";
CM_ BO_ 1738 "LDM_R DiagReq";
CM_ BO_ 1752 "BAS DiagReq";
CM_ BO_ 1764 "DCM APM DiagReq";
CM_ BO_ 1774 "MHU_FOTA_ReqAll";
CM_ BO_ 1777 "ASU Diagnostic Request";
CM_ BO_ 1787 "BCM_BPM Diagnostic Request";
CM_ BO_ 1791 "Diagnostic Request for all ECUs";
CM_ BO_ 1803 "SEED_CAN_Req6";
CM_ BO_ 1805 "SEED_CAN_Req7";
CM_ BO_ 1841 "SEED_CAN_Req17";
CM_ BO_ 1843 "SEED_CAN_Req18";
CM_ BO_ 1845 "SEED_CAN_Req20";
CM_ BO_ 1847 "SEED_CAN_Req21";
CM_ BO_ 1873 "VCU_DebugDiag";
CM_ BO_ 2015 "Diagnostic Request for all ECUs";
CM_ SG_ 1555 BMS_DiagRespData0 "Diagnostic signal Data response";
CM_ SG_ 1555 BMS_DiagRespData1 "Diagnostic signal Data response";
CM_ SG_ 1555 BMS_DiagRespData2 "Diagnostic signal Data response";
CM_ SG_ 1555 BMS_DiagRespData3 "Diagnostic signal Data response";
CM_ SG_ 1555 BMS_DiagRespData4 "Diagnostic signal Data response";
CM_ SG_ 1555 BMS_DiagRespData5 "Diagnostic signal Data response";
CM_ SG_ 1555 BMS_DiagRespData6 "Diagnostic signal Data response";
CM_ SG_ 1555 BMS_DiagRespData7 "Remote Diagnostic signal Data response";
CM_ SG_ 1556 CCUR_DiagRespData0 "Diagnostic signal Data response";
CM_ SG_ 1556 CCUR_DiagRespData1 "Diagnostic signal Data response";
CM_ SG_ 1556 CCUR_DiagRespData2 "Diagnostic signal Data response";
CM_ SG_ 1556 CCUR_DiagRespData3 "Diagnostic signal Data response";
CM_ SG_ 1556 CCUR_DiagRespData4 "Remote Diagnostic signal Data response";
CM_ SG_ 1556 CCUR_DiagRespData5 "Diagnostic signal Data response";
CM_ SG_ 1556 CCUR_DiagRespData6 "Remote Diagnostic signal Data response";
CM_ SG_ 1556 CCUR_DiagRespData7 "Diagnostic signal Data response";
CM_ SG_ 1558 FCAM_DiagRespData0 "Diagnostic signal Data response";
CM_ SG_ 1558 FCAM_DiagRespData1 "Diagnostic signal Data response";
CM_ SG_ 1558 FCAM_DiagRespData2 "Diagnostic signal Data response";
CM_ SG_ 1558 FCAM_DiagRespData3 "Diagnostic signal Data response";
CM_ SG_ 1558 FCAM_DiagRespData4 "Diagnostic signal Data response";
CM_ SG_ 1558 FCAM_DiagRespData5 "Diagnostic signal Data response";
CM_ SG_ 1558 FCAM_DiagRespData6 "Diagnostic signal Data response";
CM_ SG_ 1558 FCAM_DiagRespData7 "Diagnostic signal Data response";
CM_ SG_ 1559 PAS_DiagRespData0 "Diagnostic signal Data response";
CM_ SG_ 1559 PAS_DiagRespData1 "Diagnostic signal Data response";
CM_ SG_ 1559 PAS_DiagRespData2 "Diagnostic signal Data response";
CM_ SG_ 1559 PAS_DiagRespData3 "Diagnostic signal Data response";
CM_ SG_ 1559 PAS_DiagRespData4 "Diagnostic signal Data response";
CM_ SG_ 1559 PAS_DiagRespData5 "Diagnostic signal Data response";
CM_ SG_ 1559 PAS_DiagRespData6 "Diagnostic signal Data response";
CM_ SG_ 1559 PAS_DiagRespData7 "Diagnostic signal Data response";
CM_ SG_ 1562 EDS_R_DiagRespData0 "Diagnostic signal Data response";
CM_ SG_ 1562 EDS_R_DiagRespData1 "Diagnostic signal Data response";
CM_ SG_ 1562 EDS_R_DiagRespData2 "Remote Diagnostic signal Data response";
CM_ SG_ 1562 EDS_R_DiagRespData3 "Diagnostic signal Data response";
CM_ SG_ 1562 EDS_R_DiagRespData4 "Diagnostic signal Data response";
CM_ SG_ 1562 EDS_R_DiagRespData5 "Remote Diagnostic signal Data response";
CM_ SG_ 1562 EDS_R_DiagRespData6 "Remote Diagnostic signal Data response";
CM_ SG_ 1562 EDS_R_DiagRespData7 "Remote Diagnostic signal Data response";
CM_ SG_ 1563 EDS_F_DiagRespData0 "Diagnostic signal Data response";
CM_ SG_ 1563 EDS_F_DiagRespData1 "Diagnostic signal Data response";
CM_ SG_ 1563 EDS_F_DiagRespData2 "Remote Diagnostic signal Data response";
CM_ SG_ 1563 EDS_F_DiagRespData3 "Diagnostic signal Data response";
CM_ SG_ 1563 EDS_F_DiagRespData4 "Diagnostic signal Data response";
CM_ SG_ 1563 EDS_F_DiagRespData5 "Diagnostic signal Data response";
CM_ SG_ 1563 EDS_F_DiagRespData6 "Remote Diagnostic signal Data response";
CM_ SG_ 1563 EDS_F_DiagRespData7 "Diagnostic signal Data response";
CM_ SG_ 1566 PSM_D_DiagRespData0 "Diagnostic signal Data response";
CM_ SG_ 1566 PSM_D_DiagRespData1 "Diagnostic signal Data response";
CM_ SG_ 1566 PSM_D_DiagRespData2 "Diagnostic signal Data response";
CM_ SG_ 1566 PSM_D_DiagRespData3 "Remote Diagnostic signal Data response";
CM_ SG_ 1566 PSM_D_DiagRespData4 "Diagnostic signal Data response";
CM_ SG_ 1566 PSM_D_DiagRespData5 "Diagnostic signal Data response";
CM_ SG_ 1566 PSM_D_DiagRespData6 "Diagnostic signal Data response";
CM_ SG_ 1566 PSM_D_DiagRespData7 "Diagnostic signal Data response";
CM_ SG_ 1573 MRGEN_DiagRespData0 "Diagnostic signal Data response";
CM_ SG_ 1573 MRGEN_DiagRespData1 "Remote Diagnostic signal Data response";
CM_ SG_ 1573 MRGEN_DiagRespData2 "Diagnostic signal Data response";
CM_ SG_ 1573 MRGEN_DiagRespData3 "Diagnostic signal Data response";
CM_ SG_ 1573 MRGEN_DiagRespData4 "Diagnostic signal Data response";
CM_ SG_ 1573 MRGEN_DiagRespData5 "Diagnostic signal Data response";
CM_ SG_ 1573 MRGEN_DiagRespData6 "Diagnostic signal Data response";
CM_ SG_ 1573 MRGEN_DiagRespData7 "Remote Diagnostic signal Data response";
CM_ SG_ 1575 RCU_DiagRespData0 "Diagnostic signal Data response";
CM_ SG_ 1575 RCU_DiagRespData1 "Diagnostic signal Data response";
CM_ SG_ 1575 RCU_DiagRespData2 "Diagnostic signal Data response";
CM_ SG_ 1575 RCU_DiagRespData3 "Diagnostic signal Data response";
CM_ SG_ 1575 RCU_DiagRespData4 "Diagnostic signal Data response";
CM_ SG_ 1575 RCU_DiagRespData5 "Diagnostic signal Data response...";
CM_ SG_ 1575 RCU_DiagRespData6 "Diagnostic signal Data response";
CM_ SG_ 1575 RCU_DiagRespData7 "Diagnostic signal Data response...";
CM_ SG_ 1576 EPS_DiagRespData0 "Remote Diagnostic signal Data response";
CM_ SG_ 1576 EPS_DiagRespData1 "Diagnostic signal Data response";
CM_ SG_ 1576 EPS_DiagRespData2 "Diagnostic signal Data response";
CM_ SG_ 1576 EPS_DiagRespData3 "Remote Diagnostic signal Data response";
CM_ SG_ 1576 EPS_DiagRespData4 "Diagnostic signal Data response";
CM_ SG_ 1576 EPS_DiagRespData5 "Diagnostic signal Data response";
CM_ SG_ 1576 EPS_DiagRespData6 "Remote Diagnostic signal Data response";
CM_ SG_ 1576 EPS_DiagRespData7 "Remote Diagnostic signal Data response";
CM_ SG_ 1577 IDB_DiagRespData0 "Diagnostic signal Data response";
CM_ SG_ 1577 IDB_DiagRespData1 "Remote Diagnostic signal Data response";
CM_ SG_ 1577 IDB_DiagRespData2 "Remote Diagnostic signal Data response";
CM_ SG_ 1577 IDB_DiagRespData3 "Diagnostic signal Data response";
CM_ SG_ 1577 IDB_DiagRespData4 "Diagnostic signal Data response";
CM_ SG_ 1577 IDB_DiagRespData5 "Remote Diagnostic signal Data response";
CM_ SG_ 1577 IDB_DiagRespData6 "Remote Diagnostic signal Data response";
CM_ SG_ 1577 IDB_DiagRespData7 "Diagnostic signal Data response";
CM_ SG_ 1578 AVAS_DiagRespData0 "Diagnostic signal Data response";
CM_ SG_ 1578 AVAS_DiagRespData1 "Diagnostic signal Data response";
CM_ SG_ 1578 AVAS_DiagRespData2 "Diagnostic signal Data response";
CM_ SG_ 1578 AVAS_DiagRespData3 "Diagnostic signal Data response";
CM_ SG_ 1578 AVAS_DiagRespData4 "Diagnostic signal Data response";
CM_ SG_ 1578 AVAS_DiagRespData5 "Diagnostic signal Data response";
CM_ SG_ 1578 AVAS_DiagRespData6 "Diagnostic signal Data response";
CM_ SG_ 1578 AVAS_DiagRespData7 "Remote Diagnostic signal Data response";
CM_ SG_ 1579 EPS2_DiagRespData0 "Diagnostic signal Data response...";
CM_ SG_ 1579 EPS2_DiagRespData1 "Remote Diagnostic signal Data response";
CM_ SG_ 1579 EPS2_DiagRespData2 "Remote Diagnostic signal Data response";
CM_ SG_ 1579 EPS2_DiagRespData3 "Diagnostic signal Data response";
CM_ SG_ 1579 EPS2_DiagRespData4 "Remote Diagnostic signal Data response";
CM_ SG_ 1579 EPS2_DiagRespData5 "Diagnostic signal Data response";
CM_ SG_ 1579 EPS2_DiagRespData6 "Remote Diagnostic signal Data response";
CM_ SG_ 1579 EPS2_DiagRespData7 "Remote Diagnostic signal Data response";
CM_ SG_ 1580 VCU_DiagRespData0 "Diagnostic signal Data response";
CM_ SG_ 1580 VCU_DiagRespData1 "Diagnostic signal Data response";
CM_ SG_ 1580 VCU_DiagRespData2 "Diagnostic signal Data response";
CM_ SG_ 1580 VCU_DiagRespData3 "Diagnostic signal Data response";
CM_ SG_ 1580 VCU_DiagRespData4 "Remote Diagnostic signal Data response";
CM_ SG_ 1580 VCU_DiagRespData5 "Diagnostic signal Data response";
CM_ SG_ 1580 VCU_DiagRespData6 "Diagnostic signal Data response";
CM_ SG_ 1580 VCU_DiagRespData7 "Remote Diagnostic signal Data response";
CM_ SG_ 1582 EASC_DiagRespData0 "Remote Diagnostic signal Data response";
CM_ SG_ 1582 EASC_DiagRespData1 "Remote Diagnostic signal Data response";
CM_ SG_ 1582 EASC_DiagRespData2 "Remote Diagnostic signal Data response";
CM_ SG_ 1582 EASC_DiagRespData3 "Remote Diagnostic signal Data response";
CM_ SG_ 1582 EASC_DiagRespData4 "Remote Diagnostic signal Data response";
CM_ SG_ 1582 EASC_DiagRespData5 "Remote Diagnostic signal Data response";
CM_ SG_ 1582 EASC_DiagRespData6 "Remote Diagnostic signal Data response";
CM_ SG_ 1582 EASC_DiagRespData7 "Remote Diagnostic signal Data response";
CM_ SG_ 1583 CPD_DiagRespData0 "Diagnostic signal Data response";
CM_ SG_ 1583 CPD_DiagRespData1 "Diagnostic signal Data response";
CM_ SG_ 1583 CPD_DiagRespData2 "Diagnostic signal Data response";
CM_ SG_ 1583 CPD_DiagRespData3 "Diagnostic signal Data response";
CM_ SG_ 1583 CPD_DiagRespData4 "Diagnostic signal Data response";
CM_ SG_ 1583 CPD_DiagRespData5 "Diagnostic signal Data response";
CM_ SG_ 1583 CPD_DiagRespData6 "Diagnostic signal Data response";
CM_ SG_ 1583 CPD_DiagRespData7 "Diagnostic signal Data response";
CM_ SG_ 1584 PAS_LITE_DiagRespData0 "Diagnostic signal Data response";
CM_ SG_ 1584 PAS_LITE_DiagRespData1 "Diagnostic signal Data response";
CM_ SG_ 1584 PAS_LITE_DiagRespData2 "Diagnostic signal Data response";
CM_ SG_ 1584 PAS_LITE_DiagRespData3 "Diagnostic signal Data response";
CM_ SG_ 1584 PAS_LITE_DiagRespData4 "Diagnostic signal Data response";
CM_ SG_ 1584 PAS_LITE_DiagRespData5 "Diagnostic signal Data response";
CM_ SG_ 1584 PAS_LITE_DiagRespData6 "Diagnostic signal Data response";
CM_ SG_ 1584 PAS_LITE_DiagRespData7 "Diagnostic signal Data response";
CM_ SG_ 1588 SRR_FR_DiagRespData0 "SRR_Diagnostic Response";
CM_ SG_ 1588 SRR_FR_DiagRespData1 "SRR_Diagnostic Response";
CM_ SG_ 1588 SRR_FR_DiagRespData2 "SRR_Diagnostic Response";
CM_ SG_ 1588 SRR_FR_DiagRespData3 "SRR_Diagnostic Response";
CM_ SG_ 1588 SRR_FR_DiagRespData4 "SRR_Diagnostic Response";
CM_ SG_ 1588 SRR_FR_DiagRespData5 "SRR_Diagnostic Response";
CM_ SG_ 1588 SRR_FR_DiagRespData6 "SRR_Diagnostic Response";
CM_ SG_ 1588 SRR_FR_DiagRespData7 "SRR_Diagnostic Response";
CM_ SG_ 1589 SRR_FL_DiagRespData0 "SRR_Diagnostic Response";
CM_ SG_ 1589 SRR_FL_DiagRespData1 "SRR_Diagnostic Response";
CM_ SG_ 1589 SRR_FL_DiagRespData2 "SRR_Diagnostic Response";
CM_ SG_ 1589 SRR_FL_DiagRespData3 "SRR_Diagnostic Response";
CM_ SG_ 1589 SRR_FL_DiagRespData4 "SRR_Diagnostic Response";
CM_ SG_ 1589 SRR_FL_DiagRespData5 "SRR_Diagnostic Response";
CM_ SG_ 1589 SRR_FL_DiagRespData6 "SRR_Diagnostic Response";
CM_ SG_ 1589 SRR_FL_DiagRespData7 "SRR_Diagnostic Response";
CM_ SG_ 1590 SRR_RR_DiagRespData0 "SRR_Diagnostic Response";
CM_ SG_ 1590 SRR_RR_DiagRespData1 "SRR_Diagnostic Response";
CM_ SG_ 1590 SRR_RR_DiagRespData2 "SRR_Diagnostic Response";
CM_ SG_ 1590 SRR_RR_DiagRespData3 "SRR_Diagnostic Response";
CM_ SG_ 1590 SRR_RR_DiagRespData4 "SRR_Diagnostic Response";
CM_ SG_ 1590 SRR_RR_DiagRespData5 "SRR_Diagnostic Response";
CM_ SG_ 1590 SRR_RR_DiagRespData6 "SRR_Diagnostic Response";
CM_ SG_ 1590 SRR_RR_DiagRespData7 "SRR_Diagnostic Response";
CM_ SG_ 1591 SRR_RL_DiagRespData0 "SRR_Diagnostic Response";
CM_ SG_ 1591 SRR_RL_DiagRespData1 "SRR_Diagnostic Response";
CM_ SG_ 1591 SRR_RL_DiagRespData2 "SRR_Diagnostic Response";
CM_ SG_ 1591 SRR_RL_DiagRespData3 "SRR_Diagnostic Response";
CM_ SG_ 1591 SRR_RL_DiagRespData4 "SRR_Diagnostic Response";
CM_ SG_ 1591 SRR_RL_DiagRespData5 "SRR_Diagnostic Response";
CM_ SG_ 1591 SRR_RL_DiagRespData6 "SRR_Diagnostic Response";
CM_ SG_ 1591 SRR_RL_DiagRespData7 "SRR_Diagnostic Response";
CM_ SG_ 1592 ASU_DiagRespData0 "Diagnostic signal Data response";
CM_ SG_ 1592 ASU_DiagRespData1 "Diagnostic signal Data response";
CM_ SG_ 1592 ASU_DiagRespData2 "Diagnostic signal Data response";
CM_ SG_ 1592 ASU_DiagRespData3 "Diagnostic signal Data response";
CM_ SG_ 1592 ASU_DiagRespData4 "Diagnostic signal Data response";
CM_ SG_ 1592 ASU_DiagRespData5 "Diagnostic signal Data response";
CM_ SG_ 1592 ASU_DiagRespData6 "Diagnostic signal Data response";
CM_ SG_ 1592 ASU_DiagRespData7 "Diagnostic signal Data response";
CM_ SG_ 1593 SRR_RR_M_DiagResp_Data0 "SRR_M_Diagnostic Response";
CM_ SG_ 1593 SRR_RR_M_DiagResp_Data1 "SRR_M_Diagnostic Response";
CM_ SG_ 1593 SRR_RR_M_DiagResp_Data2 "SRR_M_Diagnostic Response";
CM_ SG_ 1593 SRR_RR_M_DiagResp_Data3 "SRR_M_Diagnostic Response";
CM_ SG_ 1593 SRR_RR_M_DiagResp_Data4 "SRR_M_Diagnostic Response";
CM_ SG_ 1593 SRR_RR_M_DiagResp_Data5 "SRR_M_Diagnostic Response";
CM_ SG_ 1593 SRR_RR_M_DiagResp_Data6 "SRR_M_Diagnostic Response";
CM_ SG_ 1593 SRR_RR_M_DiagResp_Data7 "SRR_M_Diagnostic Response";
CM_ SG_ 1595 TRM_DiagRespData0 "Diagnostic signal Data response";
CM_ SG_ 1595 TRM_DiagRespData1 "Diagnostic signal Data response";
CM_ SG_ 1595 TRM_DiagRespData2 "Diagnostic signal Data response";
CM_ SG_ 1595 TRM_DiagRespData3 "Remote Diagnostic signal Data response";
CM_ SG_ 1595 TRM_DiagRespData4 "Remote Diagnostic signal Data response";
CM_ SG_ 1595 TRM_DiagRespData5 "Remote Diagnostic signal Data response";
CM_ SG_ 1595 TRM_DiagRespData6 "Diagnostic signal Data response";
CM_ SG_ 1595 TRM_DiagRespData7 "Remote Diagnostic signal Data response";
CM_ SG_ 1597 POD_DCDC_DiagRespData0 "Diagnostic signal Data response";
CM_ SG_ 1597 POD_DCDC_DiagRespData1 "Diagnostic signal Data response";
CM_ SG_ 1597 POD_DCDC_DiagRespData2 "Remote Diagnostic signal Data response";
CM_ SG_ 1597 POD_DCDC_DiagRespData3 "Remote Diagnostic signal Data response";
CM_ SG_ 1597 POD_DCDC_DiagRespData4 "Diagnostic signal Data response";
CM_ SG_ 1597 POD_DCDC_DiagRespData5 "Diagnostic signal Data response";
CM_ SG_ 1597 POD_DCDC_DiagRespData6 "Remote Diagnostic signal Data response";
CM_ SG_ 1597 POD_DCDC_DiagRespData7 "Diagnostic signal Data response";
CM_ SG_ 1598 POD_OBC_DiagRespData0 "Diagnostic signal Data response";
CM_ SG_ 1598 POD_OBC_DiagRespData1 "Remote Diagnostic signal Data response";
CM_ SG_ 1598 POD_OBC_DiagRespData2 "Diagnostic signal Data response";
CM_ SG_ 1598 POD_OBC_DiagRespData3 "Remote Diagnostic signal Data response";
CM_ SG_ 1598 POD_OBC_DiagRespData4 "Diagnostic signal Data response";
CM_ SG_ 1598 POD_OBC_DiagRespData5 "Remote Diagnostic signal Data response";
CM_ SG_ 1598 POD_OBC_DiagRespData6 "Diagnostic signal Data response";
CM_ SG_ 1598 POD_OBC_DiagRespData7 "Remote Diagnostic signal Data response";
CM_ SG_ 1599 POD_DiagRespData0 "Diagnostic signal Data response";
CM_ SG_ 1599 POD_DiagRespData1 "Diagnostic signal Data response";
CM_ SG_ 1599 POD_DiagRespData2 "Diagnostic signal Data response";
CM_ SG_ 1599 POD_DiagRespData3 "Diagnostic signal Data response";
CM_ SG_ 1599 POD_DiagRespData4 "Diagnostic signal Data response";
CM_ SG_ 1599 POD_DiagRespData5 "Diagnostic signal Data response";
CM_ SG_ 1599 POD_DiagRespData6 "Diagnostic signal Data response";
CM_ SG_ 1599 POD_DiagRespData7 "Diagnostic signal Data response";
CM_ SG_ 1601 APM_DiagRespData0 "Diagnostic signal Data response";
CM_ SG_ 1601 APM_DiagRespData1 "Diagnostic signal Data response";
CM_ SG_ 1601 APM_DiagRespData2 "Diagnostic signal Data response";
CM_ SG_ 1601 APM_DiagRespData3 "Diagnostic signal Data response";
CM_ SG_ 1601 APM_DiagRespData4 "Remote Diagnostic signal Data response";
CM_ SG_ 1601 APM_DiagRespData5 "Diagnostic signal Data response";
CM_ SG_ 1601 APM_DiagRespData6 "Remote Diagnostic signal Data response";
CM_ SG_ 1601 APM_DiagRespData7 "Diagnostic signal Data response";
CM_ SG_ 1602 SHVU_F_DiagRespData0 "Diagnostic signal Data response";
CM_ SG_ 1602 SHVU_F_DiagRespData1 "Diagnostic signal Data response";
CM_ SG_ 1602 SHVU_F_DiagRespData2 "Remote Diagnostic signal Data response";
CM_ SG_ 1602 SHVU_F_DiagRespData3 "Diagnostic signal Data response";
CM_ SG_ 1602 SHVU_F_DiagRespData4 "Diagnostic signal Data response";
CM_ SG_ 1602 SHVU_F_DiagRespData5 "Diagnostic signal Data response";
CM_ SG_ 1602 SHVU_F_DiagRespData6 "Remote Diagnostic signal Data response";
CM_ SG_ 1602 SHVU_F_DiagRespData7 "Diagnostic signal Data response";
CM_ SG_ 1603 SHVU_R_DiagRespData0 "Diagnostic signal Data response";
CM_ SG_ 1603 SHVU_R_DiagRespData1 "Remote Diagnostic signal Data response";
CM_ SG_ 1603 SHVU_R_DiagRespData2 "Diagnostic signal Data response";
CM_ SG_ 1603 SHVU_R_DiagRespData3 "Remote Diagnostic signal Data response";
CM_ SG_ 1603 SHVU_R_DiagRespData4 "Remote Diagnostic signal Data response";
CM_ SG_ 1603 SHVU_R_DiagRespData5 "Diagnostic signal Data response";
CM_ SG_ 1603 SHVU_R_DiagRespData6 "Remote Diagnostic signal Data response";
CM_ SG_ 1603 SHVU_R_DiagRespData7 "Diagnostic signal Data response";
CM_ SG_ 1604 OCS_P_DiagRespData0 "Diagnostic signal Data response";
CM_ SG_ 1604 OCS_P_DiagRespData1 "Remote Diagnostic signal Data response";
CM_ SG_ 1604 OCS_P_DiagRespData2 "Diagnostic signal Data response";
CM_ SG_ 1604 OCS_P_DiagRespData3 "Remote Diagnostic signal Data response";
CM_ SG_ 1604 OCS_P_DiagRespData4 "Diagnostic signal Data response";
CM_ SG_ 1604 OCS_P_DiagRespData5 "Diagnostic signal Data response";
CM_ SG_ 1604 OCS_P_DiagRespData6 "Diagnostic signal Data response";
CM_ SG_ 1604 OCS_P_DiagRespData7 "Diagnostic signal Data response";
CM_ SG_ 1609 LDM_L_DiagRespData0 "Remote Diagnostic signal Data response";
CM_ SG_ 1609 LDM_L_DiagRespData1 "Diagnostic signal Data response";
CM_ SG_ 1609 LDM_L_DiagRespData2 "Remote Diagnostic signal Data response";
CM_ SG_ 1609 LDM_L_DiagRespData3 "Diagnostic signal Data response";
CM_ SG_ 1609 LDM_L_DiagRespData4 "Diagnostic signal Data response";
CM_ SG_ 1609 LDM_L_DiagRespData5 "Remote Diagnostic signal Data response";
CM_ SG_ 1609 LDM_L_DiagRespData6 "Diagnostic signal Data response";
CM_ SG_ 1609 LDM_L_DiagRespData7 "Remote Diagnostic signal Data response";
CM_ SG_ 1610 LDM_R_DiagRespData0 "Diagnostic signal Data response";
CM_ SG_ 1610 LDM_R_DiagRespData1 "Remote Diagnostic signal Data response";
CM_ SG_ 1610 LDM_R_DiagRespData2 "Diagnostic signal Data response";
CM_ SG_ 1610 LDM_R_DiagRespData3 "Diagnostic signal Data response";
CM_ SG_ 1610 LDM_R_DiagRespData4 "Remote Diagnostic signal Data response";
CM_ SG_ 1610 LDM_R_DiagRespData5 "Diagnostic signal Data response";
CM_ SG_ 1610 LDM_R_DiagRespData6 "Diagnostic signal Data response";
CM_ SG_ 1610 LDM_R_DiagRespData7 "Remote Diagnostic signal Data response";
CM_ SG_ 1624 BAS_DiagRespData0 "Diagnostic signal Data response";
CM_ SG_ 1624 BAS_DiagRespData1 "Diagnostic signal Data response";
CM_ SG_ 1624 BAS_DiagRespData2 "Diagnostic signal Data response";
CM_ SG_ 1624 BAS_DiagRespData3 "Diagnostic signal Data response";
CM_ SG_ 1624 BAS_DiagRespData4 "Diagnostic signal Data response";
CM_ SG_ 1624 BAS_DiagRespData5 "Diagnostic signal Data response";
CM_ SG_ 1624 BAS_DiagRespData6 "Diagnostic signal Data response";
CM_ SG_ 1624 BAS_DiagRespData7 "Diagnostic signal Data response";
CM_ SG_ 1636 DCM_APM_DiagRespData0 "Remote Diagnostic signal Data response";
CM_ SG_ 1636 DCM_APM_DiagRespData1 "Remote Diagnostic signal Data response";
CM_ SG_ 1636 DCM_APM_DiagRespData2 "Diagnostic signal Data response";
CM_ SG_ 1636 DCM_APM_DiagRespData3 "Remote Diagnostic signal Data response";
CM_ SG_ 1636 DCM_APM_DiagRespData4 "Diagnostic signal Data response";
CM_ SG_ 1636 DCM_APM_DiagRespData5 "Remote Diagnostic signal Data response";
CM_ SG_ 1636 DCM_APM_DiagRespData6 "Remote Diagnostic signal Data response";
CM_ SG_ 1636 DCM_APM_DiagRespData7 "Diagnostic signal Data response";
CM_ SG_ 1659 BCM_BPM_DiagRespData0 "Diagnostic signal Data response";
CM_ SG_ 1659 BCM_BPM_DiagRespData1 "Diagnostic signal Data response";
CM_ SG_ 1659 BCM_BPM_DiagRespData2 "Diagnostic signal Data response";
CM_ SG_ 1659 BCM_BPM_DiagRespData3 "Diagnostic signal Data response";
CM_ SG_ 1659 BCM_BPM_DiagRespData4 "Diagnostic signal Data response";
CM_ SG_ 1659 BCM_BPM_DiagRespData5 "Diagnostic signal Data response";
CM_ SG_ 1659 BCM_BPM_DiagRespData6 "Diagnostic signal Data response";
CM_ SG_ 1659 BCM_BPM_DiagRespData7 "Diagnostic signal Data response";
CM_ SG_ 1665 BCM_DiagReqData0 "Diagnostic signal Data request";
CM_ SG_ 1665 BCM_DiagReqData1 "Diagnostic signal Data request";
CM_ SG_ 1665 BCM_DiagReqData2 "Diagnostic signal Data request";
CM_ SG_ 1665 BCM_DiagReqData3 "Diagnostic signal Data request";
CM_ SG_ 1665 BCM_DiagReqData4 "Diagnostic signal Data request";
CM_ SG_ 1665 BCM_DiagReqData5 "Diagnostic signal Data request";
CM_ SG_ 1665 BCM_DiagReqData6 "Remote Diagnostic signal Data request";
CM_ SG_ 1665 BCM_DiagReqData7 "Remote Diagnostic signal Data request";
CM_ SG_ 1666 XGW_DiagReqData0 "Diagnostic signal Data request";
CM_ SG_ 1666 XGW_DiagReqData1 "Diagnostic signal Data request";
CM_ SG_ 1666 XGW_DiagReqData2 "Remote Diagnostic signal Data request";
CM_ SG_ 1666 XGW_DiagReqData3 "Remote Diagnostic signal Data request";
CM_ SG_ 1666 XGW_DiagReqData4 "Diagnostic signal Data request";
CM_ SG_ 1666 XGW_DiagReqData5 "Diagnostic signal Data request";
CM_ SG_ 1666 XGW_DiagReqData6 "Diagnostic signal Data request";
CM_ SG_ 1666 XGW_DiagReqData7 "Diagnostic signal Data request";
CM_ SG_ 1668 MHU_DiagReqData0 "Diagnostic signal Data request";
CM_ SG_ 1668 MHU_DiagReqData1 "Diagnostic signal Data request";
CM_ SG_ 1668 MHU_DiagReqData2 "Diagnostic signal Data request";
CM_ SG_ 1668 MHU_DiagReqData3 "Diagnostic signal Data request";
CM_ SG_ 1668 MHU_DiagReqData4 "Diagnostic signal Data request";
CM_ SG_ 1668 MHU_DiagReqData5 "Diagnostic signal Data request";
CM_ SG_ 1668 MHU_DiagReqData6 "Diagnostic signal Data request";
CM_ SG_ 1668 MHU_DiagReqData7 "Diagnostic signal Data request";
CM_ SG_ 1669 AMP_DiagReqData0 "Diagnostic signal Data request";
CM_ SG_ 1669 AMP_DiagReqData1 "Remote Diagnostic signal Data request";
CM_ SG_ 1669 AMP_DiagReqData2 "Diagnostic signal Data request";
CM_ SG_ 1669 AMP_DiagReqData3 "Diagnostic signal Data request";
CM_ SG_ 1669 AMP_DiagReqData4 "Diagnostic signal Data request";
CM_ SG_ 1669 AMP_DiagReqData5 "Remote Diagnostic signal Data request";
CM_ SG_ 1669 AMP_DiagReqData6 "Remote Diagnostic signal Data request";
CM_ SG_ 1669 AMP_DiagReqData7 "Diagnostic signal Data request";
CM_ SG_ 1672 ACM_DiagReqData0 "Diagnostic signal Data request";
CM_ SG_ 1672 ACM_DiagReqData1 "Diagnostic signal Data request";
CM_ SG_ 1672 ACM_DiagReqData2 "Diagnostic signal Data request";
CM_ SG_ 1672 ACM_DiagReqData3 "Remote Diagnostic signal Data request";
CM_ SG_ 1672 ACM_DiagReqData4 "Diagnostic signal Data request";
CM_ SG_ 1672 ACM_DiagReqData5 "Diagnostic signal Data request";
CM_ SG_ 1672 ACM_DiagReqData6 "Remote Diagnostic signal Data request";
CM_ SG_ 1672 ACM_DiagReqData7 "Diagnostic signal Data request";
CM_ SG_ 1673 CCUF_DiagReqData0 "Remote Diagnostic signal Data request";
CM_ SG_ 1673 CCUF_DiagReqData1 "Diagnostic signal Data request";
CM_ SG_ 1673 CCUF_DiagReqData2 "Diagnostic signal Data request";
CM_ SG_ 1673 CCUF_DiagReqData3 "Diagnostic signal Data request";
CM_ SG_ 1673 CCUF_DiagReqData4 "Diagnostic signal Data request";
CM_ SG_ 1673 CCUF_DiagReqData5 "Diagnostic signal Data request";
CM_ SG_ 1673 CCUF_DiagReqData6 "Diagnostic signal Data request";
CM_ SG_ 1673 CCUF_DiagReqData7 "Diagnostic signal Data request";
CM_ SG_ 1677 HUD_DiagReqData0 "Diagnostic signal Data request";
CM_ SG_ 1677 HUD_DiagReqData1 "Diagnostic signal Data request";
CM_ SG_ 1677 HUD_DiagReqData2 "Diagnostic signal Data request";
CM_ SG_ 1677 HUD_DiagReqData3 "Diagnostic signal Data request";
CM_ SG_ 1677 HUD_DiagReqData4 "Diagnostic signal Data request";
CM_ SG_ 1677 HUD_DiagReqData5 "Diagnostic signal Data request";
CM_ SG_ 1677 HUD_DiagReqData6 "Diagnostic signal Data request";
CM_ SG_ 1677 HUD_DiagReqData7 "Diagnostic signal Data request";
CM_ SG_ 1678 ETG_DiagReqData0 "Diagnostic signal Data request";
CM_ SG_ 1678 ETG_DiagReqData1 "Diagnostic signal Data request";
CM_ SG_ 1678 ETG_DiagReqData2 "Diagnostic signal Data request";
CM_ SG_ 1678 ETG_DiagReqData3 "Diagnostic signal Data request";
CM_ SG_ 1678 ETG_DiagReqData4 "Diagnostic signal Data request";
CM_ SG_ 1678 ETG_DiagReqData5 "Diagnostic signal Data request";
CM_ SG_ 1678 ETG_DiagReqData6 "Diagnostic signal Data request";
CM_ SG_ 1678 ETG_DiagReqData7 "Remote Diagnostic signal Data request";
CM_ SG_ 1679 YSS_DiagReqData0 "Diagnostic signal Data request";
CM_ SG_ 1679 YSS_DiagReqData1 "Diagnostic signal Data request";
CM_ SG_ 1679 YSS_DiagReqData2 "Diagnostic signal Data request";
CM_ SG_ 1679 YSS_DiagReqData3 "Diagnostic signal Data request";
CM_ SG_ 1679 YSS_DiagReqData4 "Remote Diagnostic signal Data request";
CM_ SG_ 1679 YSS_DiagReqData5 "Diagnostic signal Data request";
CM_ SG_ 1679 YSS_DiagReqData6 "Diagnostic signal Data request";
CM_ SG_ 1679 YSS_DiagReqData7 "Diagnostic signal Data request";
CM_ SG_ 1680 GS_DiagReqData0 "Diagnostic signal Data request";
CM_ SG_ 1680 GS_DiagReqData1 "Diagnostic signal Data request";
CM_ SG_ 1680 GS_DiagReqData2 "Diagnostic signal Data request";
CM_ SG_ 1680 GS_DiagReqData3 "Diagnostic signal Data request";
CM_ SG_ 1680 GS_DiagReqData4 "Remote Diagnostic signal Data request";
CM_ SG_ 1680 GS_DiagReqData5 "Diagnostic signal Data request";
CM_ SG_ 1680 GS_DiagReqData6 "Diagnostic signal Data request";
CM_ SG_ 1680 GS_DiagReqData7 "Diagnostic signal Data request";
CM_ SG_ 1683 BMS_DiagReqData0 "Diagnostic signal Data request";
CM_ SG_ 1683 BMS_DiagReqData1 "Diagnostic signal Data request";
CM_ SG_ 1683 BMS_DiagReqData2 "Diagnostic signal Data request";
CM_ SG_ 1683 BMS_DiagReqData3 "Remote Diagnostic signal Data request";
CM_ SG_ 1683 BMS_DiagReqData4 "Remote Diagnostic signal Data request";
CM_ SG_ 1683 BMS_DiagReqData5 "Remote Diagnostic signal Data request";
CM_ SG_ 1683 BMS_DiagReqData6 "Diagnostic signal Data request";
CM_ SG_ 1683 BMS_DiagReqData7 "Diagnostic signal Data request";
CM_ SG_ 1684 CCUR_DiagReqData0 "Diagnostic signal Data request";
CM_ SG_ 1684 CCUR_DiagReqData1 "Diagnostic signal Data request";
CM_ SG_ 1684 CCUR_DiagReqData2 "Diagnostic signal Data request";
CM_ SG_ 1684 CCUR_DiagReqData3 "Remote Diagnostic signal Data request";
CM_ SG_ 1684 CCUR_DiagReqData4 "Remote Diagnostic signal Data request";
CM_ SG_ 1684 CCUR_DiagReqData5 "Diagnostic signal Data request";
CM_ SG_ 1684 CCUR_DiagReqData6 "Diagnostic signal Data request";
CM_ SG_ 1684 CCUR_DiagReqData7 "Diagnostic signal Data request";
CM_ SG_ 1686 FCAM_DiagReqData0 "Remote Diagnostic signal Data request";
CM_ SG_ 1686 FCAM_DiagReqData1 "Remote Diagnostic signal Data request";
CM_ SG_ 1686 FCAM_DiagReqData2 "Remote Diagnostic signal Data request";
CM_ SG_ 1686 FCAM_DiagReqData3 "Remote Diagnostic signal Data request";
CM_ SG_ 1686 FCAM_DiagReqData4 "Remote Diagnostic signal Data request";
CM_ SG_ 1686 FCAM_DiagReqData5 "Remote Diagnostic signal Data request";
CM_ SG_ 1686 FCAM_DiagReqData6 "Remote Diagnostic signal Data request";
CM_ SG_ 1686 FCAM_DiagReqData7 "Remote Diagnostic signal Data request";
CM_ SG_ 1687 PAS_DiagReqData0 "Diagnostic signal Data request";
CM_ SG_ 1687 PAS_DiagReqData1 "Diagnostic signal Data request";
CM_ SG_ 1687 PAS_DiagReqData2 "Diagnostic signal Data request";
CM_ SG_ 1687 PAS_DiagReqData3 "Diagnostic signal Data request";
CM_ SG_ 1687 PAS_DiagReqData4 "Diagnostic signal Data request";
CM_ SG_ 1687 PAS_DiagReqData5 "Diagnostic signal Data request";
CM_ SG_ 1687 PAS_DiagReqData6 "Diagnostic signal Data request";
CM_ SG_ 1687 PAS_DiagReqData7 "Diagnostic signal Data request";
CM_ SG_ 1690 EDS_R_DiagReqData0 "Diagnostic signal Data request";
CM_ SG_ 1690 EDS_R_DiagReqData1 "Remote Diagnostic signal Data request";
CM_ SG_ 1690 EDS_R_DiagReqData2 "Diagnostic signal Data request";
CM_ SG_ 1690 EDS_R_DiagReqData3 "Remote Diagnostic signal Data request";
CM_ SG_ 1690 EDS_R_DiagReqData4 "Remote Diagnostic signal Data request";
CM_ SG_ 1690 EDS_R_DiagReqData5 "Diagnostic signal Data request";
CM_ SG_ 1690 EDS_R_DiagReqData6 "Remote Diagnostic signal Data request";
CM_ SG_ 1690 EDS_R_DiagReqData7 "Diagnostic signal Data request";
CM_ SG_ 1691 EDS_F_DiagReqData0 "Remote Diagnostic signal Data request";
CM_ SG_ 1691 EDS_F_DiagReqData1 "Diagnostic signal Data request";
CM_ SG_ 1691 EDS_F_DiagReqData2 "Remote Diagnostic signal Data request";
CM_ SG_ 1691 EDS_F_DiagReqData3 "Diagnostic signal Data request";
CM_ SG_ 1691 EDS_F_DiagReqData4 "Diagnostic signal Data request";
CM_ SG_ 1691 EDS_F_DiagReqData5 "Diagnostic signal Data request";
CM_ SG_ 1691 EDS_F_DiagReqData6 "Diagnostic signal Data request";
CM_ SG_ 1691 EDS_F_DiagReqData7 "Diagnostic signal Data request";
CM_ SG_ 1694 PSM_D_DiagReqData0 "Remote Diagnostic signal Data request";
CM_ SG_ 1694 PSM_D_DiagReqData1 "Diagnostic signal Data request";
CM_ SG_ 1694 PSM_D_DiagReqData2 "Remote Diagnostic signal Data request";
CM_ SG_ 1694 PSM_D_DiagReqData3 "Diagnostic signal Data request";
CM_ SG_ 1694 PSM_D_DiagReqData4 "Diagnostic signal Data request";
CM_ SG_ 1694 PSM_D_DiagReqData5 "Remote Diagnostic signal Data request";
CM_ SG_ 1694 PSM_D_DiagReqData6 "Remote Diagnostic signal Data request";
CM_ SG_ 1694 PSM_D_DiagReqData7 "Diagnostic signal Data request";
CM_ SG_ 1701 MRGEN_DiagReqData0 "Diagnostic signal Data request";
CM_ SG_ 1701 MRGEN_DiagReqData1 "Diagnostic signal Data request";
CM_ SG_ 1701 MRGEN_DiagReqData2 "Diagnostic signal Data request";
CM_ SG_ 1701 MRGEN_DiagReqData3 "Diagnostic signal Data request";
CM_ SG_ 1701 MRGEN_DiagReqData4 "Diagnostic signal Data request";
CM_ SG_ 1701 MRGEN_DiagReqData5 "Remote Diagnostic signal Data request";
CM_ SG_ 1701 MRGEN_DiagReqData6 "Diagnostic signal Data request";
CM_ SG_ 1701 MRGEN_DiagReqData7 "Diagnostic signal Data request";
CM_ SG_ 1703 RCU_DiagReqData0 "Diagnostic signal Data request";
CM_ SG_ 1703 RCU_DiagReqData1 "Diagnostic signal Data request";
CM_ SG_ 1703 RCU_DiagReqData2 "Diagnostic signal Data request";
CM_ SG_ 1703 RCU_DiagReqData3 "Diagnostic signal Data request";
CM_ SG_ 1703 RCU_DiagReqData4 "Remote Diagnostic signal Data request";
CM_ SG_ 1703 RCU_DiagReqData5 "Diagnostic signal Data request";
CM_ SG_ 1703 RCU_DiagReqData6 "Remote Diagnostic signal Data request";
CM_ SG_ 1703 RCU_DiagReqData7 "Remote Diagnostic signal Data request";
CM_ SG_ 1704 EPS_DiagReqData0 "Remote Diagnostic signal Data request";
CM_ SG_ 1704 EPS_DiagReqData1 "Diagnostic signal Data request";
CM_ SG_ 1704 EPS_DiagReqData2 "Diagnostic signal Data request";
CM_ SG_ 1704 EPS_DiagReqData3 "Diagnostic signal Data request";
CM_ SG_ 1704 EPS_DiagReqData4 "Remote Diagnostic signal Data request";
CM_ SG_ 1704 EPS_DiagReqData5 "Remote Diagnostic signal Data request";
CM_ SG_ 1704 EPS_DiagReqData6 "Remote Diagnostic signal Data request";
CM_ SG_ 1704 EPS_DiagReqData7 "Diagnostic signal Data request";
CM_ SG_ 1705 IDB_DiagReqData0 "Diagnostic signal Data request";
CM_ SG_ 1705 IDB_DiagReqData1 "Diagnostic signal Data request";
CM_ SG_ 1705 IDB_DiagReqData2 "Diagnostic signal Data request";
CM_ SG_ 1705 IDB_DiagReqData3 "Diagnostic signal Data request";
CM_ SG_ 1705 IDB_DiagReqData4 "Diagnostic signal Data request";
CM_ SG_ 1705 IDB_DiagReqData5 "Diagnostic signal Data request";
CM_ SG_ 1705 IDB_DiagReqData6 "Remote Diagnostic signal Data request";
CM_ SG_ 1705 IDB_DiagReqData7 "Diagnostic signal Data request";
CM_ SG_ 1706 AVAS_DiagReqData0 "Remote Diagnostic signal Data request";
CM_ SG_ 1706 AVAS_DiagReqData1 "Diagnostic signal Data request";
CM_ SG_ 1706 AVAS_DiagReqData2 "Diagnostic signal Data request";
CM_ SG_ 1706 AVAS_DiagReqData3 "Remote Diagnostic signal Data request";
CM_ SG_ 1706 AVAS_DiagReqData4 "Diagnostic signal Data request";
CM_ SG_ 1706 AVAS_DiagReqData5 "Diagnostic signal Data request";
CM_ SG_ 1706 AVAS_DiagReqData6 "Diagnostic signal Data request";
CM_ SG_ 1706 AVAS_DiagReqData7 "Diagnostic signal Data request";
CM_ SG_ 1707 EPS2_DiagReqData0 "Diagnostic signal Data request";
CM_ SG_ 1707 EPS2_DiagReqData1 "Diagnostic signal Data request";
CM_ SG_ 1707 EPS2_DiagReqData2 "Diagnostic signal Data request";
CM_ SG_ 1707 EPS2_DiagReqData3 "Remote Diagnostic signal Data request";
CM_ SG_ 1707 EPS2_DiagReqData4 "Diagnostic signal Data request";
CM_ SG_ 1707 EPS2_DiagReqData5 "Remote Diagnostic signal Data request";
CM_ SG_ 1707 EPS2_DiagReqData6 "Diagnostic signal Data request";
CM_ SG_ 1707 EPS2_DiagReqData7 "Diagnostic signal Data request";
CM_ SG_ 1708 VCU_DiagReqData0 "Remote Diagnostic signal Data request";
CM_ SG_ 1708 VCU_DiagReqData1 "Diagnostic signal Data request";
CM_ SG_ 1708 VCU_DiagReqData2 "Remote Diagnostic signal Data request";
CM_ SG_ 1708 VCU_DiagReqData3 "Diagnostic signal Data request";
CM_ SG_ 1708 VCU_DiagReqData4 "Diagnostic signal Data request";
CM_ SG_ 1708 VCU_DiagReqData5 "Remote Diagnostic signal Data request";
CM_ SG_ 1708 VCU_DiagReqData6 "Diagnostic signal Data request";
CM_ SG_ 1708 VCU_DiagReqData7 "Remote Diagnostic signal Data request";
CM_ SG_ 1710 EASC_DiagReqData0 "Diagnostic signal Data request";
CM_ SG_ 1710 EASC_DiagReqData1 "Diagnostic signal Data request";
CM_ SG_ 1710 EASC_DiagReqData2 "Diagnostic signal Data request";
CM_ SG_ 1710 EASC_DiagReqData3 "Diagnostic signal Data request";
CM_ SG_ 1710 EASC_DiagReqData4 "Diagnostic signal Data request";
CM_ SG_ 1710 EASC_DiagReqData5 "Diagnostic signal Data request";
CM_ SG_ 1710 EASC_DiagReqData6 "Diagnostic signal Data request";
CM_ SG_ 1710 EASC_DiagReqData7 "Diagnostic signal Data request";
CM_ SG_ 1711 CPD_DiagReqData0 "Diagnostic signal Data request";
CM_ SG_ 1711 CPD_DiagReqData1 "Diagnostic signal Data request";
CM_ SG_ 1711 CPD_DiagReqData2 "Diagnostic signal Data request";
CM_ SG_ 1711 CPD_DiagReqData3 "Diagnostic signal Data request";
CM_ SG_ 1711 CPD_DiagReqData4 "Diagnostic signal Data request";
CM_ SG_ 1711 CPD_DiagReqData5 "Diagnostic signal Data request";
CM_ SG_ 1711 CPD_DiagReqData6 "Diagnostic signal Data request";
CM_ SG_ 1711 CPD_DiagReqData7 "Diagnostic signal Data request";
CM_ SG_ 1712 PAS_LITE_DiagReqData0 "Diagnostic signal Data request";
CM_ SG_ 1712 PAS_LITE_DiagReqData1 "Diagnostic signal Data request";
CM_ SG_ 1712 PAS_LITE_DiagReqData2 "Diagnostic signal Data request";
CM_ SG_ 1712 PAS_LITE_DiagReqData3 "Diagnostic signal Data request";
CM_ SG_ 1712 PAS_LITE_DiagReqData4 "Diagnostic signal Data request";
CM_ SG_ 1712 PAS_LITE_DiagReqData5 "Diagnostic signal Data request";
CM_ SG_ 1712 PAS_LITE_DiagReqData6 "Diagnostic signal Data request";
CM_ SG_ 1712 PAS_LITE_DiagReqData7 "Diagnostic signal Data request";
CM_ SG_ 1716 SRR_FR_DiagReqData0 "SRR_Diagnostic Request";
CM_ SG_ 1716 SRR_FR_DiagReqData1 "SRR_Diagnostic Request";
CM_ SG_ 1716 SRR_FR_DiagReqData2 "Diagnostic signal Data request";
CM_ SG_ 1716 SRR_FR_DiagReqData3 "Diagnostic signal Data request";
CM_ SG_ 1716 SRR_FR_DiagReqData4 "Diagnostic signal Data request";
CM_ SG_ 1716 SRR_FR_DiagReqData5 "SRR_Diagnostic Request";
CM_ SG_ 1716 SRR_FR_DiagReqData6 "Diagnostic signal Data request";
CM_ SG_ 1716 SRR_FR_DiagReqData7 "SRR_Diagnostic Request";
CM_ SG_ 1717 SRR_FL_DiagReqData0 "Diagnostic signal Data request";
CM_ SG_ 1717 SRR_FL_DiagReqData1 "Diagnostic signal Data request";
CM_ SG_ 1717 SRR_FL_DiagReqData2 "SRR_Diagnostic Request";
CM_ SG_ 1717 SRR_FL_DiagReqData3 "SRR_Diagnostic Request";
CM_ SG_ 1717 SRR_FL_DiagReqData4 "Diagnostic signal Data request";
CM_ SG_ 1717 SRR_FL_DiagReqData5 "Diagnostic signal Data request";
CM_ SG_ 1717 SRR_FL_DiagReqData6 "Diagnostic signal Data request";
CM_ SG_ 1717 SRR_FL_DiagReqData7 "Diagnostic signal Data request";
CM_ SG_ 1718 SRR_RR_DiagReqData0 "Diagnostic signal Data request";
CM_ SG_ 1718 SRR_RR_DiagReqData1 "SRR_Diagnostic Request";
CM_ SG_ 1718 SRR_RR_DiagReqData2 "Diagnostic signal Data request";
CM_ SG_ 1718 SRR_RR_DiagReqData3 "Diagnostic signal Data request";
CM_ SG_ 1718 SRR_RR_DiagReqData4 "SRR_Diagnostic Request";
CM_ SG_ 1718 SRR_RR_DiagReqData5 "SRR_Diagnostic Request";
CM_ SG_ 1718 SRR_RR_DiagReqData6 "SRR_Diagnostic Request";
CM_ SG_ 1718 SRR_RR_DiagReqData7 "Diagnostic signal Data request";
CM_ SG_ 1719 SRR_RL_DiagReqData0 "SRR_Diagnostic Request";
CM_ SG_ 1719 SRR_RL_DiagReqData1 "Diagnostic signal Data request";
CM_ SG_ 1719 SRR_RL_DiagReqData2 "Diagnostic signal Data request";
CM_ SG_ 1719 SRR_RL_DiagReqData3 "Diagnostic signal Data request";
CM_ SG_ 1719 SRR_RL_DiagReqData4 "Diagnostic signal Data request";
CM_ SG_ 1719 SRR_RL_DiagReqData5 "SRR_Diagnostic Request";
CM_ SG_ 1719 SRR_RL_DiagReqData6 "Diagnostic signal Data request";
CM_ SG_ 1719 SRR_RL_DiagReqData7 "Diagnostic signal Data request";
CM_ SG_ 1721 SRR_RR_M_DiagReq_Data0 "SRR_RR_M Diagnostic signal Data request";
CM_ SG_ 1721 SRR_RR_M_DiagReq_Data1 "SRR_RR_M Diagnostic Request";
CM_ SG_ 1721 SRR_RR_M_DiagReq_Data2 "SRR_RR_M Diagnostic signal Data request";
CM_ SG_ 1721 SRR_RR_M_DiagReq_Data3 "SRR_RR_M Diagnostic signal Data request";
CM_ SG_ 1721 SRR_RR_M_DiagReq_Data4 "SRR_RR_M Diagnostic Request";
CM_ SG_ 1721 SRR_RR_M_DiagReq_Data5 "SRR_RR_M Diagnostic Request";
CM_ SG_ 1721 SRR_RR_M_DiagReq_Data6 "SRR_RR_M Diagnostic Request";
CM_ SG_ 1721 SRR_RR_M_DiagReq_Data7 "SRR_RR_M Diagnostic signal Data request";
CM_ SG_ 1723 TRM_DiagReqData0 "Diagnostic signal Data request";
CM_ SG_ 1723 TRM_DiagReqData1 "Diagnostic signal Data request";
CM_ SG_ 1723 TRM_DiagReqData2 "Remote Diagnostic signal Data request
";
CM_ SG_ 1723 TRM_DiagReqData3 "Remote Diagnostic signal Data request
";
CM_ SG_ 1723 TRM_DiagReqData4 "Remote Diagnostic signal Data request
";
CM_ SG_ 1723 TRM_DiagReqData5 "Diagnostic signal Data request";
CM_ SG_ 1723 TRM_DiagReqData6 "Diagnostic signal Data request";
CM_ SG_ 1723 TRM_DiagReqData7 "Remote Diagnostic signal Data request
";
CM_ SG_ 1725 POD_DCDC_DiagReqData0 "Diagnostic signal Data request";
CM_ SG_ 1725 POD_DCDC_DiagReqData1 "Diagnostic signal Data request";
CM_ SG_ 1725 POD_DCDC_DiagReqData2 "Remote Diagnostic signal Data request";
CM_ SG_ 1725 POD_DCDC_DiagReqData3 "Diagnostic signal Data request";
CM_ SG_ 1725 POD_DCDC_DiagReqData4 "Remote Diagnostic signal Data request";
CM_ SG_ 1725 POD_DCDC_DiagReqData5 "Remote Diagnostic signal Data request";
CM_ SG_ 1725 POD_DCDC_DiagReqData6 "Diagnostic signal Data request";
CM_ SG_ 1725 POD_DCDC_DiagReqData7 "Diagnostic signal Data request";
CM_ SG_ 1726 POD_OBC_DiagReqData0 "Diagnostic signal Data request";
CM_ SG_ 1726 POD_OBC_DiagReqData1 "Diagnostic signal Data request";
CM_ SG_ 1726 POD_OBC_DiagReqData2 "Diagnostic signal Data request";
CM_ SG_ 1726 POD_OBC_DiagReqData3 "Remote Diagnostic signal Data request";
CM_ SG_ 1726 POD_OBC_DiagReqData4 "Diagnostic signal Data request";
CM_ SG_ 1726 POD_OBC_DiagReqData5 "Diagnostic signal Data request";
CM_ SG_ 1726 POD_OBC_DiagReqData6 "Diagnostic signal Data request";
CM_ SG_ 1726 POD_OBC_DiagReqData7 "Remote Diagnostic signal Data request";
CM_ SG_ 1727 POD_DiagReqData0 "Diagnostic signal Data request";
CM_ SG_ 1727 POD_DiagReqData1 "Diagnostic signal Data request";
CM_ SG_ 1727 POD_DiagReqData2 "Diagnostic signal Data request";
CM_ SG_ 1727 POD_DiagReqData3 "Diagnostic signal Data request";
CM_ SG_ 1727 POD_DiagReqData4 "Diagnostic signal Data request";
CM_ SG_ 1727 POD_DiagReqData5 "Diagnostic signal Data request";
CM_ SG_ 1727 POD_DiagReqData6 "Diagnostic signal Data request";
CM_ SG_ 1727 POD_DiagReqData7 "Diagnostic signal Data request";
CM_ SG_ 1729 APM_DiagReqData0 "Diagnostic signal Data request";
CM_ SG_ 1729 APM_DiagReqData1 "Diagnostic signal Data request";
CM_ SG_ 1729 APM_DiagReqData2 "Remote Diagnostic signal Data request";
CM_ SG_ 1729 APM_DiagReqData3 "Diagnostic signal Data request";
CM_ SG_ 1729 APM_DiagReqData4 "Diagnostic signal Data request";
CM_ SG_ 1729 APM_DiagReqData5 "Remote Diagnostic signal Data request";
CM_ SG_ 1729 APM_DiagReqData6 "Diagnostic signal Data request";
CM_ SG_ 1729 APM_DiagReqData7 "Diagnostic signal Data request";
CM_ SG_ 1730 SHVU_F_DiagReqData0 "Diagnostic signal Data request";
CM_ SG_ 1730 SHVU_F_DiagReqData1 "Diagnostic signal Data request";
CM_ SG_ 1730 SHVU_F_DiagReqData2 "Diagnostic signal Data request";
CM_ SG_ 1730 SHVU_F_DiagReqData3 "Remote Diagnostic signal Data request";
CM_ SG_ 1730 SHVU_F_DiagReqData4 "Diagnostic signal Data request";
CM_ SG_ 1730 SHVU_F_DiagReqData5 "Diagnostic signal Data request";
CM_ SG_ 1730 SHVU_F_DiagReqData6 "Remote Diagnostic signal Data request";
CM_ SG_ 1730 SHVU_F_DiagReqData7 "Diagnostic signal Data request";
CM_ SG_ 1731 SHVU_R_DiagReqData0 "Diagnostic signal Data request";
CM_ SG_ 1731 SHVU_R_DiagReqData1 "Diagnostic signal Data request";
CM_ SG_ 1731 SHVU_R_DiagReqData2 "Diagnostic signal Data request";
CM_ SG_ 1731 SHVU_R_DiagReqData3 "Diagnostic signal Data request";
CM_ SG_ 1731 SHVU_R_DiagReqData4 "Diagnostic signal Data request";
CM_ SG_ 1731 SHVU_R_DiagReqData5 "Remote Diagnostic signal Data request";
CM_ SG_ 1731 SHVU_R_DiagReqData6 "Diagnostic signal Data request";
CM_ SG_ 1731 SHVU_R_DiagReqData7 "Diagnostic signal Data request";
CM_ SG_ 1732 OCS_P_DiagReqData0 "Remote Diagnostic signal Data request";
CM_ SG_ 1732 OCS_P_DiagReqData1 "Diagnostic signal Data request";
CM_ SG_ 1732 OCS_P_DiagReqData2 "Diagnostic signal Data request";
CM_ SG_ 1732 OCS_P_DiagReqData3 "Diagnostic signal Data request";
CM_ SG_ 1732 OCS_P_DiagReqData4 "Diagnostic signal Data request";
CM_ SG_ 1732 OCS_P_DiagReqData5 "Diagnostic signal Data request";
CM_ SG_ 1732 OCS_P_DiagReqData6 "Diagnostic signal Data request";
CM_ SG_ 1732 OCS_P_DiagReqData7 "Remote Diagnostic signal Data request";
CM_ SG_ 1737 LDM_L_DiagReqData0 "Remote Diagnostic signal Data request";
CM_ SG_ 1737 LDM_L_DiagReqData1 "Diagnostic signal Data request";
CM_ SG_ 1737 LDM_L_DiagReqData2 "Diagnostic signal Data request";
CM_ SG_ 1737 LDM_L_DiagReqData3 "Diagnostic signal Data request";
CM_ SG_ 1737 LDM_L_DiagReqData4 "Remote Diagnostic signal Data request";
CM_ SG_ 1737 LDM_L_DiagReqData5 "Diagnostic signal Data request";
CM_ SG_ 1737 LDM_L_DiagReqData6 "Diagnostic signal Data request";
CM_ SG_ 1737 LDM_L_DiagReqData7 "Diagnostic signal Data request";
CM_ SG_ 1738 LDM_R_DiagReqData0 "Diagnostic signal Data request";
CM_ SG_ 1738 LDM_R_DiagReqData1 "Diagnostic signal Data request";
CM_ SG_ 1738 LDM_R_DiagReqData2 "Diagnostic signal Data request";
CM_ SG_ 1738 LDM_R_DiagReqData3 "Remote Diagnostic signal Data request";
CM_ SG_ 1738 LDM_R_DiagReqData4 "Diagnostic signal Data request";
CM_ SG_ 1738 LDM_R_DiagReqData5 "Diagnostic signal Data request";
CM_ SG_ 1738 LDM_R_DiagReqData6 "Remote Diagnostic signal Data request";
CM_ SG_ 1738 LDM_R_DiagReqData7 "Remote Diagnostic signal Data request";
CM_ SG_ 1752 BAS_DiagReqData0 "Diagnostic signal Data request";
CM_ SG_ 1752 BAS_DiagReqData1 "Diagnostic signal Data request";
CM_ SG_ 1752 BAS_DiagReqData2 "Diagnostic signal Data request";
CM_ SG_ 1752 BAS_DiagReqData3 "Diagnostic signal Data request";
CM_ SG_ 1752 BAS_DiagReqData4 "Diagnostic signal Data request";
CM_ SG_ 1752 BAS_DiagReqData5 "Diagnostic signal Data request";
CM_ SG_ 1752 BAS_DiagReqData6 "Diagnostic signal Data request";
CM_ SG_ 1752 BAS_DiagReqData7 "Diagnostic signal Data request";
CM_ SG_ 1764 DCM_APM_DiagReqData0 "Remote Diagnostic signal Data request";
CM_ SG_ 1764 DCM_APM_DiagReqData1 "Remote Diagnostic signal Data request";
CM_ SG_ 1764 DCM_APM_DiagReqData2 "Remote Diagnostic signal Data request";
CM_ SG_ 1764 DCM_APM_DiagReqData3 "Remote Diagnostic signal Data request";
CM_ SG_ 1764 DCM_APM_DiagReqData4 "Diagnostic signal Data request";
CM_ SG_ 1764 DCM_APM_DiagReqData5 "Diagnostic signal Data request";
CM_ SG_ 1764 DCM_APM_DiagReqData6 "Diagnostic signal Data request";
CM_ SG_ 1764 DCM_APM_DiagReqData7 "Diagnostic signal Data request";
CM_ SG_ 1774 MHU_FOTA_ReqAll_00 "FOTA broadcast request all will be routed by XGW to 0x6FF on all buses";
CM_ SG_ 1774 MHU_FOTA_ReqAll_01 "FOTA broadcast request all will be routed by XGW to 0x6FF on all buses";
CM_ SG_ 1774 MHU_FOTA_ReqAll_02 "FOTA broadcast request all will be routed by XGW to 0x6FF on all buses";
CM_ SG_ 1774 MHU_FOTA_ReqAll_03 "FOTA broadcast request all will be routed by XGW to 0x6FF on all buses";
CM_ SG_ 1774 MHU_FOTA_ReqAll_04 "FOTA broadcast request all will be routed by XGW to 0x6FF on all buses";
CM_ SG_ 1774 MHU_FOTA_ReqAll_05 "FOTA broadcast request all will be routed by XGW to 0x6FF on all buses";
CM_ SG_ 1774 MHU_FOTA_ReqAll_06 "FOTA broadcast request all will be routed by XGW to 0x6FF on all buses";
CM_ SG_ 1774 MHU_FOTA_ReqAll_07 "FOTA broadcast request all will be routed by XGW to 0x6FF on all buses";
CM_ SG_ 1777 ASU_DiagReqData0 "Diagnostic signal Data request";
CM_ SG_ 1777 ASU_DiagReqData1 "Diagnostic signal Data request";
CM_ SG_ 1777 ASU_DiagReqData2 "Diagnostic signal Data request";
CM_ SG_ 1777 ASU_DiagReqData3 "Diagnostic signal Data request";
CM_ SG_ 1777 ASU_DiagReqData4 "Diagnostic signal Data request";
CM_ SG_ 1777 ASU_DiagReqData5 "Diagnostic signal Data request";
CM_ SG_ 1777 ASU_DiagReqData6 "Diagnostic signal Data request";
CM_ SG_ 1777 ASU_DiagReqData7 "Diagnostic signal Data request";
CM_ SG_ 1787 BCM_BPM_DiagReqData0 "Diagnostic signal Data request";
CM_ SG_ 1787 BCM_BPM_DiagReqData1 "Diagnostic signal Data request";
CM_ SG_ 1787 BCM_BPM_DiagReqData2 "Diagnostic signal Data request";
CM_ SG_ 1787 BCM_BPM_DiagReqData3 "Diagnostic signal Data request";
CM_ SG_ 1787 BCM_BPM_DiagReqData4 "Diagnostic signal Data request";
CM_ SG_ 1787 BCM_BPM_DiagReqData5 "Diagnostic signal Data request";
CM_ SG_ 1787 BCM_BPM_DiagReqData6 "Diagnostic signal Data request";
CM_ SG_ 1787 BCM_BPM_DiagReqData7 "Diagnostic signal Data request";
CM_ SG_ 1791 DiagReqAllEcuData0 "Diagnostic message all ECUs";
CM_ SG_ 1791 DiagReqAllEcuData1 "Diagnostic message all ECUs";
CM_ SG_ 1791 DiagReqAllEcuData2 "Diagnostic message all ECUs";
CM_ SG_ 1791 DiagReqAllEcuData3 "Diagnostic message all ECUs";
CM_ SG_ 1791 DiagReqAllEcuData4 "Diagnostic message all ECUs";
CM_ SG_ 1791 DiagReqAllEcuData5 "Diagnostic message all ECUs";
CM_ SG_ 1791 DiagReqAllEcuData6 "Diagnostic message all ECUs";
CM_ SG_ 1791 DiagReqAllEcuData7 "Diagnostic message all ECUs";
CM_ SG_ 1803 SEED_CAN_Req6 "byte 0/1 identifier of target ECU
byte 2/3 service request type 270x/670x
byte 4-7 seed key";
CM_ SG_ 1805 SEED_CAN_Req7 "byte 0/1 identifier of target ECU
byte 2/3 service request type 270x/670x
byte 4-7 seed key";
CM_ SG_ 1841 SEED_CAN_Req17 "byte 0/1 identifier of target ECU
byte 2/3 service request type 270x/670x
byte 4-7 seed key";
CM_ SG_ 1843 SEED_CAN_Req18 "byte 0/1 identifier of target ECU...";
CM_ SG_ 1845 SEED_CAN_Req20 "byte 0/1 identifier of target ECU
byte 2/3 service request type 270x/670x
byte 4-7 seed key";
CM_ SG_ 1847 SEED_CAN_Req21 "byte 0/1 identifier of target ECU...";
CM_ SG_ 1850 SEED_CAN_Req25 "Secret portion from Secure CAN algorithm";
CM_ SG_ 1853 SEED_CAN_Req29 "Secret portion from Secure CAN algorithm";
CM_ SG_ 1873 VCU_DebugDiag2 "VCU Acm component error level";
CM_ SG_ 1873 VCU_DebugDiag1 "VCU xGW component error level";
CM_ SG_ 1873 VCU_DebugDiag5 "VCU Regen brake component error level";
CM_ SG_ 1873 VCU_DebugDiag4 "VCU Idb component error level";
CM_ SG_ 1873 VCU_DebugDiag3 "VCU Brake component error level";
CM_ SG_ 1873 VCU_DebugDiag8 "VCU Ags component error level";
CM_ SG_ 1873 VCU_DebugDiag7 "VCU Lvd component error level";
CM_ SG_ 1873 VCU_DebugDiag6 "VCU Eds component error level";
CM_ SG_ 1873 VCU_DebugDiag10 "VCU Fan component error level";
CM_ SG_ 1873 VCU_DebugDiag9 "VCU Ptc component error level";
CM_ SG_ 1873 VCU_DebugDiag13 "VCU Valve component error level";
CM_ SG_ 1873 VCU_DebugDiag12 "VCU Tsen component error level";
CM_ SG_ 1873 VCU_DebugDiag11 "VCU Hvac component error level";
CM_ SG_ 1873 VCU_DebugDiag16 "VCU Bms component error level";
CM_ SG_ 1873 VCU_DebugDiag15 "VCU Vehicle speed component error level";
CM_ SG_ 1873 VCU_DebugDiag14 "VCU Water pump component error level";
CM_ SG_ 1873 VCU_DebugDiag18 "VCU Accelerator pedal component error level";
CM_ SG_ 1873 VCU_DebugDiag17 "VCU Obc component error level";
CM_ SG_ 1873 VCU_DebugDiag20 "VCU Dcdc component error level";
CM_ SG_ 1873 VCU_DebugDiag19 "VCU charging component errror level";
CM_ SG_ 2015 Diag_Request_ECU_Data0 "Diagnostic message all ECUs";
CM_ SG_ 2015 Diag_Request_ECU_Data1 "Diagnostic message all ECUs";
CM_ SG_ 2015 Diag_Request_ECU_Data2 "Diagnostic message all ECUs";
CM_ SG_ 2015 Diag_Request_ECU_Data3 "Diagnostic message all ECUs";
CM_ SG_ 2015 Diag_Request_ECU_Data4 "Diagnostic message all ECUs";
CM_ SG_ 2015 Diag_Request_ECU_Data5 "Diagnostic message all ECUs";
CM_ SG_ 2015 Diag_Request_ECU_Data6 "Diagnostic message all ECUs";
CM_ SG_ 2015 Diag_Request_ECU_Data7 "Diagnostic message all ECUs";
CM_ BO_ 287  "MHU_BCM_DrivingInhibition";
CM_ SG_ 287 MHU_DrvInhibitSts "MHU_DrivingInhibitionStatus";
CM_ SG_ 287 TBOX_AuthCode_0x11F "TBOX Message Authentication Code of message 0x11F";
CM_ BO_ 280  "BCM_MHU_DrivingInhibitionFeed";
CM_ SG_ 280 CHKSM_BCM_MHU_Ctrl_Fbk "Checksum";
CM_ SG_ 280 ALV_BCM_MHU_Ctrl_Fbk "Alive Counter";
CM_ SG_ 280 BCM_DrvInhibitStsFbk "BCM Feedback status for Driving Inhibition";

BA_DEF_ BO_  "GenMsgSendType" ENUM "Cyclic","NotUsed","NotUsed","NotUsed","NotUsed","NotUsed","NotUsed","IfActive","NoMsgSendType","NotUsed";
BA_DEF_ BO_  "GenMsgILSupport" ENUM "No","Yes";
BA_DEF_ BO_  "DiagResponse" ENUM "No","Yes";
BA_DEF_ BO_  "DiagRequest" ENUM "No","Yes";
BA_DEF_ BO_  "NmAsrMessage" ENUM "No","Yes";
BA_DEF_ BO_  "DiagState" ENUM "No","Yes";
BA_DEF_ BO_  "DiagUudtResponse" ENUM "False","True";
BA_DEF_ BO_  "GenMsgStartDelayTime" INT 0 65535;
BA_DEF_ BO_  "GenMsgDelayTime" INT 0 0;
BA_DEF_ BO_  "GenMsgNrOfRepetition" INT 0 0;
BA_DEF_ BO_  "GenMsgCycleTimeFast" INT 0 0;
BA_DEF_ BO_  "GenMsgCycleTime" INT 0 0;
BA_DEF_ SG_  "GenSigSendType" ENUM "Cyclic","OnWrite","OnWriteWithRepetition","OnChange","OnChangeWithRepetition","IfActive","IfActiveWithRepetition","NoSigSendType","NotUsed","NotUsed","NotUsed","NotUsed","NotUsed";
BA_DEF_ SG_  "InvalidValue" STRING;
BA_DEF_ SG_  "GenSigStartValue" INT 0 0;
BA_DEF_ SG_  "GenSigTimeoutTime_ALL" INT 0 65535;
BA_DEF_DEF_  "DiagRequest" "No";
BA_DEF_DEF_  "DiagResponse" "No";
BA_DEF_DEF_  "DiagState" "No";
BA_DEF_DEF_  "DiagUudtResponse" "False";
BA_DEF_DEF_  "GenMsgCycleTime" 0;
BA_DEF_DEF_  "GenMsgCycleTimeFast" 0;
BA_DEF_DEF_  "GenMsgDelayTime" 0;
BA_DEF_DEF_  "GenMsgILSupport" "Yes";
BA_DEF_DEF_  "GenMsgNrOfRepetition" 0;
BA_DEF_DEF_  "GenMsgSendType" "NoMsgSendType";
BA_DEF_DEF_  "GenMsgStartDelayTime" 0;
BA_DEF_DEF_  "GenSigSendType" "Cyclic";
BA_DEF_DEF_  "GenSigStartValue" 0;
BA_DEF_DEF_  "GenSigTimeoutTime_ALL" 0;
BA_DEF_DEF_  "NmAsrMessage" "No";
BA_ "DiagResponse" BO_ 1555 1;
BA_ "GenMsgILSupport" BO_ 1555 0;
BA_ "DiagResponse" BO_ 1556 1;
BA_ "GenMsgILSupport" BO_ 1556 0;
BA_ "DiagResponse" BO_ 1558 1;
BA_ "DiagResponse" BO_ 1559 1;
BA_ "DiagResponse" BO_ 1562 1;
BA_ "GenMsgILSupport" BO_ 1562 0;
BA_ "DiagResponse" BO_ 1563 1;
BA_ "GenMsgILSupport" BO_ 1563 0;
BA_ "DiagResponse" BO_ 1566 1;
BA_ "GenMsgILSupport" BO_ 1566 0;
BA_ "GenMsgILSupport" BO_ 1573 0;
BA_ "DiagResponse" BO_ 1573 1;
BA_ "DiagResponse" BO_ 1575 1;
BA_ "GenMsgILSupport" BO_ 1575 0;
BA_ "DiagResponse" BO_ 1576 1;
BA_ "GenMsgILSupport" BO_ 1576 0;
BA_ "DiagResponse" BO_ 1577 1;
BA_ "GenMsgILSupport" BO_ 1577 0;
BA_ "DiagResponse" BO_ 1578 1;
BA_ "GenMsgILSupport" BO_ 1578 0;
BA_ "DiagResponse" BO_ 1579 1;
BA_ "GenMsgILSupport" BO_ 1579 0;
BA_ "DiagResponse" BO_ 1580 1;
BA_ "GenMsgILSupport" BO_ 1580 0;
BA_ "DiagResponse" BO_ 1582 1;
BA_ "GenMsgILSupport" BO_ 1582 0;
BA_ "DiagResponse" BO_ 1583 1;
BA_ "GenMsgILSupport" BO_ 1583 0;
BA_ "DiagResponse" BO_ 1584 1;
BA_ "DiagResponse" BO_ 1588 1;
BA_ "DiagResponse" BO_ 1589 1;
BA_ "DiagResponse" BO_ 1590 1;
BA_ "DiagResponse" BO_ 1591 1;
BA_ "DiagResponse" BO_ 1592 1;
BA_ "DiagResponse" BO_ 1593 1;
BA_ "DiagResponse" BO_ 1595 1;
BA_ "DiagResponse" BO_ 1597 1;
BA_ "GenMsgILSupport" BO_ 1597 0;
BA_ "DiagResponse" BO_ 1598 1;
BA_ "GenMsgILSupport" BO_ 1598 0;
BA_ "DiagResponse" BO_ 1599 1;
BA_ "DiagResponse" BO_ 1601 1;
BA_ "DiagResponse" BO_ 1602 1;
BA_ "GenMsgILSupport" BO_ 1602 0;
BA_ "DiagResponse" BO_ 1603 1;
BA_ "GenMsgILSupport" BO_ 1603 0;
BA_ "DiagResponse" BO_ 1604 1;
BA_ "GenMsgILSupport" BO_ 1604 0;
BA_ "DiagResponse" BO_ 1609 1;
BA_ "DiagResponse" BO_ 1610 1;
BA_ "DiagResponse" BO_ 1624 1;
BA_ "DiagResponse" BO_ 1636 1;
BA_ "DiagResponse" BO_ 1659 1;
BA_ "GenMsgILSupport" BO_ 1659 0;
BA_ "DiagRequest" BO_ 1665 1;
BA_ "GenMsgILSupport" BO_ 1665 0;
BA_ "DiagRequest" BO_ 1666 1;
BA_ "GenMsgILSupport" BO_ 1666 0;
BA_ "DiagRequest" BO_ 1668 1;
BA_ "GenMsgILSupport" BO_ 1668 0;
BA_ "DiagRequest" BO_ 1669 1;
BA_ "GenMsgILSupport" BO_ 1669 0;
BA_ "DiagRequest" BO_ 1672 1;
BA_ "GenMsgILSupport" BO_ 1672 0;
BA_ "DiagRequest" BO_ 1673 1;
BA_ "GenMsgILSupport" BO_ 1673 0;
BA_ "DiagRequest" BO_ 1677 1;
BA_ "GenMsgILSupport" BO_ 1677 0;
BA_ "DiagRequest" BO_ 1678 1;
BA_ "GenMsgILSupport" BO_ 1678 0;
BA_ "DiagRequest" BO_ 1679 1;
BA_ "GenMsgILSupport" BO_ 1679 0;
BA_ "DiagRequest" BO_ 1680 1;
BA_ "GenMsgILSupport" BO_ 1680 0;
BA_ "DiagRequest" BO_ 1683 1;
BA_ "GenMsgILSupport" BO_ 1683 0;
BA_ "DiagRequest" BO_ 1684 1;
BA_ "GenMsgILSupport" BO_ 1684 0;
BA_ "DiagRequest" BO_ 1686 1;
BA_ "DiagRequest" BO_ 1687 1;
BA_ "DiagRequest" BO_ 1690 1;
BA_ "GenMsgILSupport" BO_ 1690 0;
BA_ "DiagRequest" BO_ 1691 1;
BA_ "GenMsgILSupport" BO_ 1691 0;
BA_ "DiagRequest" BO_ 1694 1;
BA_ "GenMsgILSupport" BO_ 1694 0;
BA_ "GenMsgILSupport" BO_ 1701 0;
BA_ "DiagRequest" BO_ 1701 1;
BA_ "DiagRequest" BO_ 1703 1;
BA_ "GenMsgILSupport" BO_ 1703 0;
BA_ "DiagRequest" BO_ 1704 1;
BA_ "GenMsgILSupport" BO_ 1704 0;
BA_ "DiagRequest" BO_ 1705 1;
BA_ "GenMsgILSupport" BO_ 1705 0;
BA_ "DiagRequest" BO_ 1706 1;
BA_ "GenMsgILSupport" BO_ 1706 0;
BA_ "DiagRequest" BO_ 1707 1;
BA_ "GenMsgILSupport" BO_ 1707 0;
BA_ "DiagRequest" BO_ 1708 1;
BA_ "GenMsgILSupport" BO_ 1708 0;
BA_ "DiagRequest" BO_ 1710 1;
BA_ "GenMsgILSupport" BO_ 1710 0;
BA_ "DiagRequest" BO_ 1711 1;
BA_ "GenMsgILSupport" BO_ 1711 0;
BA_ "DiagRequest" BO_ 1712 1;
BA_ "DiagRequest" BO_ 1716 1;
BA_ "DiagRequest" BO_ 1717 1;
BA_ "DiagRequest" BO_ 1718 1;
BA_ "DiagRequest" BO_ 1719 1;
BA_ "DiagRequest" BO_ 1721 1;
BA_ "DiagRequest" BO_ 1723 1;
BA_ "DiagRequest" BO_ 1725 1;
BA_ "GenMsgILSupport" BO_ 1725 0;
BA_ "DiagRequest" BO_ 1726 1;
BA_ "GenMsgILSupport" BO_ 1726 0;
BA_ "DiagRequest" BO_ 1727 1;
BA_ "DiagRequest" BO_ 1729 1;
BA_ "DiagRequest" BO_ 1730 1;
BA_ "GenMsgILSupport" BO_ 1730 0;
BA_ "DiagRequest" BO_ 1731 1;
BA_ "GenMsgILSupport" BO_ 1731 0;
BA_ "DiagRequest" BO_ 1732 1;
BA_ "GenMsgILSupport" BO_ 1732 0;
BA_ "DiagRequest" BO_ 1737 1;
BA_ "DiagRequest" BO_ 1738 1;
BA_ "DiagRequest" BO_ 1752 1;
BA_ "DiagRequest" BO_ 1764 1;
BA_ "DiagRequest" BO_ 1774 1;
BA_ "DiagRequest" BO_ 1777 1;
BA_ "DiagRequest" BO_ 1787 1;
BA_ "GenMsgILSupport" BO_ 1787 0;
BA_ "DiagRequest" BO_ 1791 1;
BA_ "DiagState" BO_ 1791 1;
BA_ "GenMsgILSupport" BO_ 1791 0;
BA_ "GenMsgCycleTime" BO_ 1873 100;
BA_ "GenMsgSendType" BO_ 1873 0;
BA_ "DiagRequest" BO_ 2015 1;
BA_ "GenMsgCycleTimeFast" BO_ 287 30;
BA_ "GenMsgNrOfRepetition" BO_ 287 3;
BA_ "GenMsgCycleTime" BO_ 280 500;
BA_ "GenMsgSendType" BO_ 280 0;
BA_ "GenSigSendType" SG_ 1555 BMS_DiagRespData0 7;
BA_ "InvalidValue" SG_ 1555 BMS_DiagRespData0 "null";
BA_ "GenSigSendType" SG_ 1555 BMS_DiagRespData1 7;
BA_ "InvalidValue" SG_ 1555 BMS_DiagRespData1 "null";
BA_ "GenSigSendType" SG_ 1555 BMS_DiagRespData2 7;
BA_ "InvalidValue" SG_ 1555 BMS_DiagRespData2 "null";
BA_ "GenSigSendType" SG_ 1555 BMS_DiagRespData3 7;
BA_ "InvalidValue" SG_ 1555 BMS_DiagRespData3 "null";
BA_ "GenSigSendType" SG_ 1555 BMS_DiagRespData4 7;
BA_ "InvalidValue" SG_ 1555 BMS_DiagRespData4 "null";
BA_ "GenSigSendType" SG_ 1555 BMS_DiagRespData5 7;
BA_ "InvalidValue" SG_ 1555 BMS_DiagRespData5 "null";
BA_ "GenSigSendType" SG_ 1555 BMS_DiagRespData6 7;
BA_ "InvalidValue" SG_ 1555 BMS_DiagRespData6 "null";
BA_ "GenSigSendType" SG_ 1555 BMS_DiagRespData7 7;
BA_ "InvalidValue" SG_ 1555 BMS_DiagRespData7 "null";
BA_ "GenSigSendType" SG_ 1556 CCUR_DiagRespData0 7;
BA_ "InvalidValue" SG_ 1556 CCUR_DiagRespData0 "null";
BA_ "GenSigSendType" SG_ 1556 CCUR_DiagRespData1 7;
BA_ "InvalidValue" SG_ 1556 CCUR_DiagRespData1 "null";
BA_ "GenSigSendType" SG_ 1556 CCUR_DiagRespData2 7;
BA_ "InvalidValue" SG_ 1556 CCUR_DiagRespData2 "null";
BA_ "GenSigSendType" SG_ 1556 CCUR_DiagRespData3 7;
BA_ "InvalidValue" SG_ 1556 CCUR_DiagRespData3 "null";
BA_ "GenSigSendType" SG_ 1556 CCUR_DiagRespData4 7;
BA_ "InvalidValue" SG_ 1556 CCUR_DiagRespData4 "null";
BA_ "GenSigSendType" SG_ 1556 CCUR_DiagRespData5 7;
BA_ "InvalidValue" SG_ 1556 CCUR_DiagRespData5 "null";
BA_ "GenSigSendType" SG_ 1556 CCUR_DiagRespData6 7;
BA_ "InvalidValue" SG_ 1556 CCUR_DiagRespData6 "null";
BA_ "GenSigSendType" SG_ 1556 CCUR_DiagRespData7 7;
BA_ "InvalidValue" SG_ 1556 CCUR_DiagRespData7 "null";
BA_ "GenSigSendType" SG_ 1558 FCAM_DiagRespData0 7;
BA_ "GenSigSendType" SG_ 1558 FCAM_DiagRespData1 7;
BA_ "GenSigSendType" SG_ 1558 FCAM_DiagRespData2 7;
BA_ "GenSigSendType" SG_ 1558 FCAM_DiagRespData3 7;
BA_ "GenSigSendType" SG_ 1558 FCAM_DiagRespData4 7;
BA_ "GenSigSendType" SG_ 1558 FCAM_DiagRespData5 7;
BA_ "GenSigSendType" SG_ 1558 FCAM_DiagRespData6 7;
BA_ "GenSigSendType" SG_ 1558 FCAM_DiagRespData7 7;
BA_ "GenSigSendType" SG_ 1559 PAS_DiagRespData0 7;
BA_ "GenSigSendType" SG_ 1559 PAS_DiagRespData1 7;
BA_ "GenSigSendType" SG_ 1559 PAS_DiagRespData2 7;
BA_ "GenSigSendType" SG_ 1559 PAS_DiagRespData3 7;
BA_ "GenSigSendType" SG_ 1559 PAS_DiagRespData4 7;
BA_ "GenSigSendType" SG_ 1559 PAS_DiagRespData5 7;
BA_ "GenSigSendType" SG_ 1559 PAS_DiagRespData6 7;
BA_ "GenSigSendType" SG_ 1559 PAS_DiagRespData7 7;
BA_ "GenSigSendType" SG_ 1562 EDS_R_DiagRespData0 7;
BA_ "InvalidValue" SG_ 1562 EDS_R_DiagRespData0 "null";
BA_ "GenSigSendType" SG_ 1562 EDS_R_DiagRespData1 7;
BA_ "InvalidValue" SG_ 1562 EDS_R_DiagRespData1 "null";
BA_ "GenSigSendType" SG_ 1562 EDS_R_DiagRespData2 7;
BA_ "InvalidValue" SG_ 1562 EDS_R_DiagRespData2 "null";
BA_ "GenSigSendType" SG_ 1562 EDS_R_DiagRespData3 7;
BA_ "InvalidValue" SG_ 1562 EDS_R_DiagRespData3 "null";
BA_ "GenSigSendType" SG_ 1562 EDS_R_DiagRespData4 7;
BA_ "InvalidValue" SG_ 1562 EDS_R_DiagRespData4 "null";
BA_ "GenSigSendType" SG_ 1562 EDS_R_DiagRespData5 7;
BA_ "InvalidValue" SG_ 1562 EDS_R_DiagRespData5 "null";
BA_ "GenSigSendType" SG_ 1562 EDS_R_DiagRespData6 7;
BA_ "InvalidValue" SG_ 1562 EDS_R_DiagRespData6 "null";
BA_ "GenSigSendType" SG_ 1562 EDS_R_DiagRespData7 7;
BA_ "InvalidValue" SG_ 1562 EDS_R_DiagRespData7 "null";
BA_ "GenSigSendType" SG_ 1563 EDS_F_DiagRespData0 7;
BA_ "InvalidValue" SG_ 1563 EDS_F_DiagRespData0 "null";
BA_ "GenSigSendType" SG_ 1563 EDS_F_DiagRespData1 7;
BA_ "InvalidValue" SG_ 1563 EDS_F_DiagRespData1 "null";
BA_ "GenSigSendType" SG_ 1563 EDS_F_DiagRespData2 7;
BA_ "InvalidValue" SG_ 1563 EDS_F_DiagRespData2 "null";
BA_ "GenSigSendType" SG_ 1563 EDS_F_DiagRespData3 7;
BA_ "InvalidValue" SG_ 1563 EDS_F_DiagRespData3 "null";
BA_ "GenSigSendType" SG_ 1563 EDS_F_DiagRespData4 7;
BA_ "InvalidValue" SG_ 1563 EDS_F_DiagRespData4 "null";
BA_ "GenSigSendType" SG_ 1563 EDS_F_DiagRespData5 7;
BA_ "InvalidValue" SG_ 1563 EDS_F_DiagRespData5 "null";
BA_ "GenSigSendType" SG_ 1563 EDS_F_DiagRespData6 7;
BA_ "InvalidValue" SG_ 1563 EDS_F_DiagRespData6 "null";
BA_ "GenSigSendType" SG_ 1563 EDS_F_DiagRespData7 7;
BA_ "InvalidValue" SG_ 1563 EDS_F_DiagRespData7 "null";
BA_ "GenSigSendType" SG_ 1566 PSM_D_DiagRespData0 7;
BA_ "InvalidValue" SG_ 1566 PSM_D_DiagRespData0 "null";
BA_ "GenSigSendType" SG_ 1566 PSM_D_DiagRespData1 7;
BA_ "InvalidValue" SG_ 1566 PSM_D_DiagRespData1 "null";
BA_ "GenSigSendType" SG_ 1566 PSM_D_DiagRespData2 7;
BA_ "InvalidValue" SG_ 1566 PSM_D_DiagRespData2 "null";
BA_ "GenSigSendType" SG_ 1566 PSM_D_DiagRespData3 7;
BA_ "InvalidValue" SG_ 1566 PSM_D_DiagRespData3 "null";
BA_ "GenSigSendType" SG_ 1566 PSM_D_DiagRespData4 7;
BA_ "InvalidValue" SG_ 1566 PSM_D_DiagRespData4 "null";
BA_ "GenSigSendType" SG_ 1566 PSM_D_DiagRespData5 7;
BA_ "InvalidValue" SG_ 1566 PSM_D_DiagRespData5 "null";
BA_ "GenSigSendType" SG_ 1566 PSM_D_DiagRespData6 7;
BA_ "InvalidValue" SG_ 1566 PSM_D_DiagRespData6 "null";
BA_ "GenSigSendType" SG_ 1566 PSM_D_DiagRespData7 7;
BA_ "InvalidValue" SG_ 1566 PSM_D_DiagRespData7 "null";
BA_ "InvalidValue" SG_ 1573 MRGEN_DiagRespData0 "";
BA_ "GenSigSendType" SG_ 1573 MRGEN_DiagRespData0 7;
BA_ "InvalidValue" SG_ 1573 MRGEN_DiagRespData1 "";
BA_ "GenSigSendType" SG_ 1573 MRGEN_DiagRespData1 7;
BA_ "InvalidValue" SG_ 1573 MRGEN_DiagRespData2 "";
BA_ "GenSigSendType" SG_ 1573 MRGEN_DiagRespData2 7;
BA_ "InvalidValue" SG_ 1573 MRGEN_DiagRespData3 "";
BA_ "GenSigSendType" SG_ 1573 MRGEN_DiagRespData3 7;
BA_ "InvalidValue" SG_ 1573 MRGEN_DiagRespData4 "";
BA_ "GenSigSendType" SG_ 1573 MRGEN_DiagRespData4 7;
BA_ "InvalidValue" SG_ 1573 MRGEN_DiagRespData5 "";
BA_ "GenSigSendType" SG_ 1573 MRGEN_DiagRespData5 7;
BA_ "InvalidValue" SG_ 1573 MRGEN_DiagRespData6 "";
BA_ "GenSigSendType" SG_ 1573 MRGEN_DiagRespData6 7;
BA_ "InvalidValue" SG_ 1573 MRGEN_DiagRespData7 "";
BA_ "GenSigSendType" SG_ 1573 MRGEN_DiagRespData7 7;
BA_ "GenSigSendType" SG_ 1575 RCU_DiagRespData0 7;
BA_ "InvalidValue" SG_ 1575 RCU_DiagRespData0 "null";
BA_ "GenSigSendType" SG_ 1575 RCU_DiagRespData1 7;
BA_ "InvalidValue" SG_ 1575 RCU_DiagRespData1 "null";
BA_ "GenSigSendType" SG_ 1575 RCU_DiagRespData2 7;
BA_ "InvalidValue" SG_ 1575 RCU_DiagRespData2 "null";
BA_ "GenSigSendType" SG_ 1575 RCU_DiagRespData3 7;
BA_ "InvalidValue" SG_ 1575 RCU_DiagRespData3 "null";
BA_ "GenSigSendType" SG_ 1575 RCU_DiagRespData4 7;
BA_ "InvalidValue" SG_ 1575 RCU_DiagRespData4 "null";
BA_ "GenSigSendType" SG_ 1575 RCU_DiagRespData5 7;
BA_ "InvalidValue" SG_ 1575 RCU_DiagRespData5 "null";
BA_ "GenSigSendType" SG_ 1575 RCU_DiagRespData6 7;
BA_ "InvalidValue" SG_ 1575 RCU_DiagRespData6 "null";
BA_ "GenSigSendType" SG_ 1575 RCU_DiagRespData7 7;
BA_ "InvalidValue" SG_ 1575 RCU_DiagRespData7 "null";
BA_ "GenSigSendType" SG_ 1576 EPS_DiagRespData0 7;
BA_ "InvalidValue" SG_ 1576 EPS_DiagRespData0 "null";
BA_ "GenSigSendType" SG_ 1576 EPS_DiagRespData1 7;
BA_ "InvalidValue" SG_ 1576 EPS_DiagRespData1 "null";
BA_ "GenSigSendType" SG_ 1576 EPS_DiagRespData2 7;
BA_ "InvalidValue" SG_ 1576 EPS_DiagRespData2 "null";
BA_ "GenSigSendType" SG_ 1576 EPS_DiagRespData3 7;
BA_ "InvalidValue" SG_ 1576 EPS_DiagRespData3 "null";
BA_ "GenSigSendType" SG_ 1576 EPS_DiagRespData4 7;
BA_ "InvalidValue" SG_ 1576 EPS_DiagRespData4 "null";
BA_ "GenSigSendType" SG_ 1576 EPS_DiagRespData5 7;
BA_ "InvalidValue" SG_ 1576 EPS_DiagRespData5 "null";
BA_ "GenSigSendType" SG_ 1576 EPS_DiagRespData6 7;
BA_ "InvalidValue" SG_ 1576 EPS_DiagRespData6 "null";
BA_ "GenSigSendType" SG_ 1576 EPS_DiagRespData7 7;
BA_ "InvalidValue" SG_ 1576 EPS_DiagRespData7 "null";
BA_ "GenSigSendType" SG_ 1577 IDB_DiagRespData0 7;
BA_ "InvalidValue" SG_ 1577 IDB_DiagRespData0 "null";
BA_ "GenSigSendType" SG_ 1577 IDB_DiagRespData1 7;
BA_ "InvalidValue" SG_ 1577 IDB_DiagRespData1 "null";
BA_ "GenSigSendType" SG_ 1577 IDB_DiagRespData2 7;
BA_ "InvalidValue" SG_ 1577 IDB_DiagRespData2 "null";
BA_ "GenSigSendType" SG_ 1577 IDB_DiagRespData3 7;
BA_ "InvalidValue" SG_ 1577 IDB_DiagRespData3 "null";
BA_ "GenSigSendType" SG_ 1577 IDB_DiagRespData4 7;
BA_ "InvalidValue" SG_ 1577 IDB_DiagRespData4 "null";
BA_ "GenSigSendType" SG_ 1577 IDB_DiagRespData5 7;
BA_ "InvalidValue" SG_ 1577 IDB_DiagRespData5 "null";
BA_ "GenSigSendType" SG_ 1577 IDB_DiagRespData6 7;
BA_ "InvalidValue" SG_ 1577 IDB_DiagRespData6 "null";
BA_ "GenSigSendType" SG_ 1577 IDB_DiagRespData7 7;
BA_ "InvalidValue" SG_ 1577 IDB_DiagRespData7 "null";
BA_ "GenSigSendType" SG_ 1578 AVAS_DiagRespData0 7;
BA_ "InvalidValue" SG_ 1578 AVAS_DiagRespData0 "null";
BA_ "GenSigSendType" SG_ 1578 AVAS_DiagRespData1 7;
BA_ "InvalidValue" SG_ 1578 AVAS_DiagRespData1 "null";
BA_ "GenSigSendType" SG_ 1578 AVAS_DiagRespData2 7;
BA_ "InvalidValue" SG_ 1578 AVAS_DiagRespData2 "null";
BA_ "GenSigSendType" SG_ 1578 AVAS_DiagRespData3 7;
BA_ "InvalidValue" SG_ 1578 AVAS_DiagRespData3 "null";
BA_ "GenSigSendType" SG_ 1578 AVAS_DiagRespData4 7;
BA_ "InvalidValue" SG_ 1578 AVAS_DiagRespData4 "null";
BA_ "GenSigSendType" SG_ 1578 AVAS_DiagRespData5 7;
BA_ "InvalidValue" SG_ 1578 AVAS_DiagRespData5 "null";
BA_ "GenSigSendType" SG_ 1578 AVAS_DiagRespData6 7;
BA_ "InvalidValue" SG_ 1578 AVAS_DiagRespData6 "null";
BA_ "GenSigSendType" SG_ 1578 AVAS_DiagRespData7 7;
BA_ "InvalidValue" SG_ 1578 AVAS_DiagRespData7 "null";
BA_ "GenSigSendType" SG_ 1579 EPS2_DiagRespData0 7;
BA_ "InvalidValue" SG_ 1579 EPS2_DiagRespData0 "null";
BA_ "GenSigSendType" SG_ 1579 EPS2_DiagRespData1 7;
BA_ "InvalidValue" SG_ 1579 EPS2_DiagRespData1 "null";
BA_ "GenSigSendType" SG_ 1579 EPS2_DiagRespData2 7;
BA_ "InvalidValue" SG_ 1579 EPS2_DiagRespData2 "null";
BA_ "GenSigSendType" SG_ 1579 EPS2_DiagRespData3 7;
BA_ "InvalidValue" SG_ 1579 EPS2_DiagRespData3 "null";
BA_ "GenSigSendType" SG_ 1579 EPS2_DiagRespData4 7;
BA_ "InvalidValue" SG_ 1579 EPS2_DiagRespData4 "null";
BA_ "GenSigSendType" SG_ 1579 EPS2_DiagRespData5 7;
BA_ "InvalidValue" SG_ 1579 EPS2_DiagRespData5 "null";
BA_ "GenSigSendType" SG_ 1579 EPS2_DiagRespData6 7;
BA_ "InvalidValue" SG_ 1579 EPS2_DiagRespData6 "null";
BA_ "GenSigSendType" SG_ 1579 EPS2_DiagRespData7 7;
BA_ "InvalidValue" SG_ 1579 EPS2_DiagRespData7 "null";
BA_ "GenSigSendType" SG_ 1580 VCU_DiagRespData0 7;
BA_ "InvalidValue" SG_ 1580 VCU_DiagRespData0 "null";
BA_ "GenSigSendType" SG_ 1580 VCU_DiagRespData1 7;
BA_ "InvalidValue" SG_ 1580 VCU_DiagRespData1 "null";
BA_ "GenSigSendType" SG_ 1580 VCU_DiagRespData2 7;
BA_ "InvalidValue" SG_ 1580 VCU_DiagRespData2 "null";
BA_ "GenSigSendType" SG_ 1580 VCU_DiagRespData3 7;
BA_ "InvalidValue" SG_ 1580 VCU_DiagRespData3 "null";
BA_ "GenSigSendType" SG_ 1580 VCU_DiagRespData4 7;
BA_ "InvalidValue" SG_ 1580 VCU_DiagRespData4 "null";
BA_ "GenSigSendType" SG_ 1580 VCU_DiagRespData5 7;
BA_ "InvalidValue" SG_ 1580 VCU_DiagRespData5 "null";
BA_ "GenSigSendType" SG_ 1580 VCU_DiagRespData6 7;
BA_ "InvalidValue" SG_ 1580 VCU_DiagRespData6 "null";
BA_ "GenSigSendType" SG_ 1580 VCU_DiagRespData7 7;
BA_ "InvalidValue" SG_ 1580 VCU_DiagRespData7 "null";
BA_ "GenSigSendType" SG_ 1582 EASC_DiagRespData0 7;
BA_ "InvalidValue" SG_ 1582 EASC_DiagRespData0 "null";
BA_ "GenSigSendType" SG_ 1582 EASC_DiagRespData1 7;
BA_ "InvalidValue" SG_ 1582 EASC_DiagRespData1 "null";
BA_ "GenSigSendType" SG_ 1582 EASC_DiagRespData2 7;
BA_ "InvalidValue" SG_ 1582 EASC_DiagRespData2 "null";
BA_ "GenSigSendType" SG_ 1582 EASC_DiagRespData3 7;
BA_ "InvalidValue" SG_ 1582 EASC_DiagRespData3 "null";
BA_ "GenSigSendType" SG_ 1582 EASC_DiagRespData4 7;
BA_ "InvalidValue" SG_ 1582 EASC_DiagRespData4 "null";
BA_ "GenSigSendType" SG_ 1582 EASC_DiagRespData5 7;
BA_ "InvalidValue" SG_ 1582 EASC_DiagRespData5 "null";
BA_ "GenSigSendType" SG_ 1582 EASC_DiagRespData6 7;
BA_ "InvalidValue" SG_ 1582 EASC_DiagRespData6 "null";
BA_ "GenSigSendType" SG_ 1582 EASC_DiagRespData7 7;
BA_ "InvalidValue" SG_ 1582 EASC_DiagRespData7 "null";
BA_ "GenSigSendType" SG_ 1583 CPD_DiagRespData0 7;
BA_ "InvalidValue" SG_ 1583 CPD_DiagRespData0 "null";
BA_ "GenSigSendType" SG_ 1583 CPD_DiagRespData1 7;
BA_ "InvalidValue" SG_ 1583 CPD_DiagRespData1 "null";
BA_ "GenSigSendType" SG_ 1583 CPD_DiagRespData2 7;
BA_ "InvalidValue" SG_ 1583 CPD_DiagRespData2 "null";
BA_ "GenSigSendType" SG_ 1583 CPD_DiagRespData3 7;
BA_ "InvalidValue" SG_ 1583 CPD_DiagRespData3 "null";
BA_ "GenSigSendType" SG_ 1583 CPD_DiagRespData4 7;
BA_ "InvalidValue" SG_ 1583 CPD_DiagRespData4 "null";
BA_ "GenSigSendType" SG_ 1583 CPD_DiagRespData5 7;
BA_ "InvalidValue" SG_ 1583 CPD_DiagRespData5 "null";
BA_ "GenSigSendType" SG_ 1583 CPD_DiagRespData6 7;
BA_ "InvalidValue" SG_ 1583 CPD_DiagRespData6 "null";
BA_ "GenSigSendType" SG_ 1583 CPD_DiagRespData7 7;
BA_ "InvalidValue" SG_ 1583 CPD_DiagRespData7 "null";
BA_ "InvalidValue" SG_ 1584 PAS_LITE_DiagRespData0 "";
BA_ "GenSigSendType" SG_ 1584 PAS_LITE_DiagRespData0 7;
BA_ "InvalidValue" SG_ 1584 PAS_LITE_DiagRespData1 "";
BA_ "GenSigSendType" SG_ 1584 PAS_LITE_DiagRespData1 7;
BA_ "InvalidValue" SG_ 1584 PAS_LITE_DiagRespData2 "";
BA_ "GenSigSendType" SG_ 1584 PAS_LITE_DiagRespData2 7;
BA_ "InvalidValue" SG_ 1584 PAS_LITE_DiagRespData3 "";
BA_ "GenSigSendType" SG_ 1584 PAS_LITE_DiagRespData3 7;
BA_ "InvalidValue" SG_ 1584 PAS_LITE_DiagRespData4 "";
BA_ "GenSigSendType" SG_ 1584 PAS_LITE_DiagRespData4 7;
BA_ "InvalidValue" SG_ 1584 PAS_LITE_DiagRespData5 "";
BA_ "GenSigSendType" SG_ 1584 PAS_LITE_DiagRespData5 7;
BA_ "InvalidValue" SG_ 1584 PAS_LITE_DiagRespData6 "";
BA_ "GenSigSendType" SG_ 1584 PAS_LITE_DiagRespData6 7;
BA_ "InvalidValue" SG_ 1584 PAS_LITE_DiagRespData7 "";
BA_ "GenSigSendType" SG_ 1584 PAS_LITE_DiagRespData7 7;
BA_ "GenSigSendType" SG_ 1588 SRR_FR_DiagRespData0 7;
BA_ "GenSigSendType" SG_ 1588 SRR_FR_DiagRespData1 7;
BA_ "GenSigSendType" SG_ 1588 SRR_FR_DiagRespData2 7;
BA_ "GenSigSendType" SG_ 1588 SRR_FR_DiagRespData3 7;
BA_ "GenSigSendType" SG_ 1588 SRR_FR_DiagRespData4 7;
BA_ "GenSigSendType" SG_ 1588 SRR_FR_DiagRespData5 7;
BA_ "GenSigSendType" SG_ 1588 SRR_FR_DiagRespData6 7;
BA_ "GenSigSendType" SG_ 1588 SRR_FR_DiagRespData7 7;
BA_ "GenSigSendType" SG_ 1589 SRR_FL_DiagRespData0 7;
BA_ "GenSigSendType" SG_ 1589 SRR_FL_DiagRespData1 7;
BA_ "GenSigSendType" SG_ 1589 SRR_FL_DiagRespData2 7;
BA_ "GenSigSendType" SG_ 1589 SRR_FL_DiagRespData3 7;
BA_ "GenSigSendType" SG_ 1589 SRR_FL_DiagRespData4 7;
BA_ "GenSigSendType" SG_ 1589 SRR_FL_DiagRespData5 7;
BA_ "GenSigSendType" SG_ 1589 SRR_FL_DiagRespData6 7;
BA_ "GenSigSendType" SG_ 1589 SRR_FL_DiagRespData7 7;
BA_ "GenSigSendType" SG_ 1590 SRR_RR_DiagRespData0 7;
BA_ "GenSigSendType" SG_ 1590 SRR_RR_DiagRespData1 7;
BA_ "GenSigSendType" SG_ 1590 SRR_RR_DiagRespData2 7;
BA_ "GenSigSendType" SG_ 1590 SRR_RR_DiagRespData3 7;
BA_ "GenSigSendType" SG_ 1590 SRR_RR_DiagRespData4 7;
BA_ "GenSigSendType" SG_ 1590 SRR_RR_DiagRespData5 7;
BA_ "GenSigSendType" SG_ 1590 SRR_RR_DiagRespData6 7;
BA_ "GenSigSendType" SG_ 1590 SRR_RR_DiagRespData7 7;
BA_ "GenSigSendType" SG_ 1591 SRR_RL_DiagRespData0 7;
BA_ "GenSigSendType" SG_ 1591 SRR_RL_DiagRespData1 7;
BA_ "GenSigSendType" SG_ 1591 SRR_RL_DiagRespData2 7;
BA_ "GenSigSendType" SG_ 1591 SRR_RL_DiagRespData3 7;
BA_ "GenSigSendType" SG_ 1591 SRR_RL_DiagRespData4 7;
BA_ "GenSigSendType" SG_ 1591 SRR_RL_DiagRespData5 7;
BA_ "GenSigSendType" SG_ 1591 SRR_RL_DiagRespData6 7;
BA_ "GenSigSendType" SG_ 1591 SRR_RL_DiagRespData7 7;
BA_ "GenSigSendType" SG_ 1592 ASU_DiagRespData0 7;
BA_ "GenSigSendType" SG_ 1592 ASU_DiagRespData1 7;
BA_ "GenSigSendType" SG_ 1592 ASU_DiagRespData2 7;
BA_ "GenSigSendType" SG_ 1592 ASU_DiagRespData3 7;
BA_ "GenSigSendType" SG_ 1592 ASU_DiagRespData4 7;
BA_ "GenSigSendType" SG_ 1592 ASU_DiagRespData5 7;
BA_ "GenSigSendType" SG_ 1592 ASU_DiagRespData6 7;
BA_ "GenSigSendType" SG_ 1592 ASU_DiagRespData7 7;
BA_ "GenSigSendType" SG_ 1593 SRR_RR_M_DiagResp_Data0 7;
BA_ "GenSigSendType" SG_ 1593 SRR_RR_M_DiagResp_Data1 7;
BA_ "GenSigSendType" SG_ 1593 SRR_RR_M_DiagResp_Data2 7;
BA_ "GenSigSendType" SG_ 1593 SRR_RR_M_DiagResp_Data3 7;
BA_ "GenSigSendType" SG_ 1593 SRR_RR_M_DiagResp_Data4 7;
BA_ "GenSigSendType" SG_ 1593 SRR_RR_M_DiagResp_Data5 7;
BA_ "GenSigSendType" SG_ 1593 SRR_RR_M_DiagResp_Data6 7;
BA_ "GenSigSendType" SG_ 1593 SRR_RR_M_DiagResp_Data7 7;
BA_ "GenSigSendType" SG_ 1595 TRM_DiagRespData0 7;
BA_ "InvalidValue" SG_ 1595 TRM_DiagRespData0 "null";
BA_ "GenSigSendType" SG_ 1595 TRM_DiagRespData1 7;
BA_ "InvalidValue" SG_ 1595 TRM_DiagRespData1 "null";
BA_ "GenSigSendType" SG_ 1595 TRM_DiagRespData2 7;
BA_ "InvalidValue" SG_ 1595 TRM_DiagRespData2 "null";
BA_ "GenSigSendType" SG_ 1595 TRM_DiagRespData3 7;
BA_ "InvalidValue" SG_ 1595 TRM_DiagRespData3 "null";
BA_ "GenSigSendType" SG_ 1595 TRM_DiagRespData4 7;
BA_ "InvalidValue" SG_ 1595 TRM_DiagRespData4 "null";
BA_ "GenSigSendType" SG_ 1595 TRM_DiagRespData5 7;
BA_ "InvalidValue" SG_ 1595 TRM_DiagRespData5 "null";
BA_ "GenSigSendType" SG_ 1595 TRM_DiagRespData6 7;
BA_ "InvalidValue" SG_ 1595 TRM_DiagRespData6 "null";
BA_ "GenSigSendType" SG_ 1595 TRM_DiagRespData7 7;
BA_ "InvalidValue" SG_ 1595 TRM_DiagRespData7 "null";
BA_ "GenSigSendType" SG_ 1597 POD_DCDC_DiagRespData0 7;
BA_ "InvalidValue" SG_ 1597 POD_DCDC_DiagRespData0 "null";
BA_ "GenSigSendType" SG_ 1597 POD_DCDC_DiagRespData1 7;
BA_ "InvalidValue" SG_ 1597 POD_DCDC_DiagRespData1 "null";
BA_ "GenSigSendType" SG_ 1597 POD_DCDC_DiagRespData2 7;
BA_ "InvalidValue" SG_ 1597 POD_DCDC_DiagRespData2 "null";
BA_ "GenSigSendType" SG_ 1597 POD_DCDC_DiagRespData3 7;
BA_ "InvalidValue" SG_ 1597 POD_DCDC_DiagRespData3 "null";
BA_ "GenSigSendType" SG_ 1597 POD_DCDC_DiagRespData4 7;
BA_ "InvalidValue" SG_ 1597 POD_DCDC_DiagRespData4 "null";
BA_ "GenSigSendType" SG_ 1597 POD_DCDC_DiagRespData5 7;
BA_ "InvalidValue" SG_ 1597 POD_DCDC_DiagRespData5 "null";
BA_ "GenSigSendType" SG_ 1597 POD_DCDC_DiagRespData6 7;
BA_ "InvalidValue" SG_ 1597 POD_DCDC_DiagRespData6 "null";
BA_ "GenSigSendType" SG_ 1597 POD_DCDC_DiagRespData7 7;
BA_ "InvalidValue" SG_ 1597 POD_DCDC_DiagRespData7 "null";
BA_ "GenSigSendType" SG_ 1598 POD_OBC_DiagRespData0 7;
BA_ "InvalidValue" SG_ 1598 POD_OBC_DiagRespData0 "null";
BA_ "GenSigSendType" SG_ 1598 POD_OBC_DiagRespData1 7;
BA_ "InvalidValue" SG_ 1598 POD_OBC_DiagRespData1 "null";
BA_ "GenSigSendType" SG_ 1598 POD_OBC_DiagRespData2 7;
BA_ "InvalidValue" SG_ 1598 POD_OBC_DiagRespData2 "null";
BA_ "GenSigSendType" SG_ 1598 POD_OBC_DiagRespData3 7;
BA_ "InvalidValue" SG_ 1598 POD_OBC_DiagRespData3 "null";
BA_ "GenSigSendType" SG_ 1598 POD_OBC_DiagRespData4 7;
BA_ "InvalidValue" SG_ 1598 POD_OBC_DiagRespData4 "null";
BA_ "GenSigSendType" SG_ 1598 POD_OBC_DiagRespData5 7;
BA_ "InvalidValue" SG_ 1598 POD_OBC_DiagRespData5 "null";
BA_ "GenSigSendType" SG_ 1598 POD_OBC_DiagRespData6 7;
BA_ "InvalidValue" SG_ 1598 POD_OBC_DiagRespData6 "null";
BA_ "GenSigSendType" SG_ 1598 POD_OBC_DiagRespData7 7;
BA_ "InvalidValue" SG_ 1598 POD_OBC_DiagRespData7 "null";
BA_ "GenSigSendType" SG_ 1599 POD_DiagRespData0 7;
BA_ "InvalidValue" SG_ 1599 POD_DiagRespData0 "null";
BA_ "GenSigSendType" SG_ 1599 POD_DiagRespData1 7;
BA_ "InvalidValue" SG_ 1599 POD_DiagRespData1 "null";
BA_ "GenSigSendType" SG_ 1599 POD_DiagRespData2 7;
BA_ "InvalidValue" SG_ 1599 POD_DiagRespData2 "null";
BA_ "GenSigSendType" SG_ 1599 POD_DiagRespData3 7;
BA_ "InvalidValue" SG_ 1599 POD_DiagRespData3 "null";
BA_ "GenSigSendType" SG_ 1599 POD_DiagRespData4 7;
BA_ "InvalidValue" SG_ 1599 POD_DiagRespData4 "null";
BA_ "GenSigSendType" SG_ 1599 POD_DiagRespData5 7;
BA_ "InvalidValue" SG_ 1599 POD_DiagRespData5 "null";
BA_ "GenSigSendType" SG_ 1599 POD_DiagRespData6 7;
BA_ "InvalidValue" SG_ 1599 POD_DiagRespData6 "null";
BA_ "GenSigSendType" SG_ 1599 POD_DiagRespData7 7;
BA_ "InvalidValue" SG_ 1599 POD_DiagRespData7 "null";
BA_ "GenSigSendType" SG_ 1601 APM_DiagRespData0 7;
BA_ "InvalidValue" SG_ 1601 APM_DiagRespData0 "null";
BA_ "GenSigSendType" SG_ 1601 APM_DiagRespData1 7;
BA_ "InvalidValue" SG_ 1601 APM_DiagRespData1 "null";
BA_ "GenSigSendType" SG_ 1601 APM_DiagRespData2 7;
BA_ "InvalidValue" SG_ 1601 APM_DiagRespData2 "null";
BA_ "GenSigSendType" SG_ 1601 APM_DiagRespData3 7;
BA_ "InvalidValue" SG_ 1601 APM_DiagRespData3 "null";
BA_ "GenSigSendType" SG_ 1601 APM_DiagRespData4 7;
BA_ "InvalidValue" SG_ 1601 APM_DiagRespData4 "null";
BA_ "GenSigSendType" SG_ 1601 APM_DiagRespData5 7;
BA_ "InvalidValue" SG_ 1601 APM_DiagRespData5 "null";
BA_ "GenSigSendType" SG_ 1601 APM_DiagRespData6 7;
BA_ "InvalidValue" SG_ 1601 APM_DiagRespData6 "null";
BA_ "GenSigSendType" SG_ 1601 APM_DiagRespData7 7;
BA_ "InvalidValue" SG_ 1601 APM_DiagRespData7 "null";
BA_ "GenSigSendType" SG_ 1602 SHVU_F_DiagRespData0 7;
BA_ "InvalidValue" SG_ 1602 SHVU_F_DiagRespData0 "null";
BA_ "GenSigSendType" SG_ 1602 SHVU_F_DiagRespData1 7;
BA_ "InvalidValue" SG_ 1602 SHVU_F_DiagRespData1 "null";
BA_ "GenSigSendType" SG_ 1602 SHVU_F_DiagRespData2 7;
BA_ "InvalidValue" SG_ 1602 SHVU_F_DiagRespData2 "null";
BA_ "GenSigSendType" SG_ 1602 SHVU_F_DiagRespData3 7;
BA_ "InvalidValue" SG_ 1602 SHVU_F_DiagRespData3 "null";
BA_ "GenSigSendType" SG_ 1602 SHVU_F_DiagRespData4 7;
BA_ "InvalidValue" SG_ 1602 SHVU_F_DiagRespData4 "null";
BA_ "GenSigSendType" SG_ 1602 SHVU_F_DiagRespData5 7;
BA_ "InvalidValue" SG_ 1602 SHVU_F_DiagRespData5 "null";
BA_ "GenSigSendType" SG_ 1602 SHVU_F_DiagRespData6 7;
BA_ "InvalidValue" SG_ 1602 SHVU_F_DiagRespData6 "null";
BA_ "GenSigSendType" SG_ 1602 SHVU_F_DiagRespData7 7;
BA_ "InvalidValue" SG_ 1602 SHVU_F_DiagRespData7 "null";
BA_ "GenSigSendType" SG_ 1603 SHVU_R_DiagRespData0 7;
BA_ "InvalidValue" SG_ 1603 SHVU_R_DiagRespData0 "null";
BA_ "GenSigSendType" SG_ 1603 SHVU_R_DiagRespData1 7;
BA_ "InvalidValue" SG_ 1603 SHVU_R_DiagRespData1 "null";
BA_ "GenSigSendType" SG_ 1603 SHVU_R_DiagRespData2 7;
BA_ "InvalidValue" SG_ 1603 SHVU_R_DiagRespData2 "null";
BA_ "GenSigSendType" SG_ 1603 SHVU_R_DiagRespData3 7;
BA_ "InvalidValue" SG_ 1603 SHVU_R_DiagRespData3 "null";
BA_ "GenSigSendType" SG_ 1603 SHVU_R_DiagRespData4 7;
BA_ "InvalidValue" SG_ 1603 SHVU_R_DiagRespData4 "null";
BA_ "GenSigSendType" SG_ 1603 SHVU_R_DiagRespData5 7;
BA_ "InvalidValue" SG_ 1603 SHVU_R_DiagRespData5 "null";
BA_ "GenSigSendType" SG_ 1603 SHVU_R_DiagRespData6 7;
BA_ "InvalidValue" SG_ 1603 SHVU_R_DiagRespData6 "null";
BA_ "GenSigSendType" SG_ 1603 SHVU_R_DiagRespData7 7;
BA_ "InvalidValue" SG_ 1603 SHVU_R_DiagRespData7 "null";
BA_ "GenSigSendType" SG_ 1604 OCS_P_DiagRespData0 7;
BA_ "InvalidValue" SG_ 1604 OCS_P_DiagRespData0 "null";
BA_ "GenSigSendType" SG_ 1604 OCS_P_DiagRespData1 7;
BA_ "InvalidValue" SG_ 1604 OCS_P_DiagRespData1 "null";
BA_ "GenSigSendType" SG_ 1604 OCS_P_DiagRespData2 7;
BA_ "InvalidValue" SG_ 1604 OCS_P_DiagRespData2 "null";
BA_ "GenSigSendType" SG_ 1604 OCS_P_DiagRespData3 7;
BA_ "InvalidValue" SG_ 1604 OCS_P_DiagRespData3 "null";
BA_ "GenSigSendType" SG_ 1604 OCS_P_DiagRespData4 7;
BA_ "InvalidValue" SG_ 1604 OCS_P_DiagRespData4 "null";
BA_ "GenSigSendType" SG_ 1604 OCS_P_DiagRespData5 7;
BA_ "InvalidValue" SG_ 1604 OCS_P_DiagRespData5 "null";
BA_ "GenSigSendType" SG_ 1604 OCS_P_DiagRespData6 7;
BA_ "InvalidValue" SG_ 1604 OCS_P_DiagRespData6 "null";
BA_ "GenSigSendType" SG_ 1604 OCS_P_DiagRespData7 7;
BA_ "InvalidValue" SG_ 1604 OCS_P_DiagRespData7 "null";
BA_ "GenSigSendType" SG_ 1609 LDM_L_DiagRespData0 7;
BA_ "InvalidValue" SG_ 1609 LDM_L_DiagRespData0 "null";
BA_ "GenSigSendType" SG_ 1609 LDM_L_DiagRespData1 7;
BA_ "InvalidValue" SG_ 1609 LDM_L_DiagRespData1 "null";
BA_ "GenSigSendType" SG_ 1609 LDM_L_DiagRespData2 7;
BA_ "InvalidValue" SG_ 1609 LDM_L_DiagRespData2 "null";
BA_ "GenSigSendType" SG_ 1609 LDM_L_DiagRespData3 7;
BA_ "InvalidValue" SG_ 1609 LDM_L_DiagRespData3 "null";
BA_ "GenSigSendType" SG_ 1609 LDM_L_DiagRespData4 7;
BA_ "InvalidValue" SG_ 1609 LDM_L_DiagRespData4 "null";
BA_ "GenSigSendType" SG_ 1609 LDM_L_DiagRespData5 7;
BA_ "InvalidValue" SG_ 1609 LDM_L_DiagRespData5 "null";
BA_ "GenSigSendType" SG_ 1609 LDM_L_DiagRespData6 7;
BA_ "InvalidValue" SG_ 1609 LDM_L_DiagRespData6 "null";
BA_ "GenSigSendType" SG_ 1609 LDM_L_DiagRespData7 7;
BA_ "InvalidValue" SG_ 1609 LDM_L_DiagRespData7 "null";
BA_ "GenSigSendType" SG_ 1610 LDM_R_DiagRespData0 7;
BA_ "InvalidValue" SG_ 1610 LDM_R_DiagRespData0 "null";
BA_ "GenSigSendType" SG_ 1610 LDM_R_DiagRespData1 7;
BA_ "InvalidValue" SG_ 1610 LDM_R_DiagRespData1 "null";
BA_ "GenSigSendType" SG_ 1610 LDM_R_DiagRespData2 7;
BA_ "InvalidValue" SG_ 1610 LDM_R_DiagRespData2 "null";
BA_ "GenSigSendType" SG_ 1610 LDM_R_DiagRespData3 7;
BA_ "InvalidValue" SG_ 1610 LDM_R_DiagRespData3 "null";
BA_ "GenSigSendType" SG_ 1610 LDM_R_DiagRespData4 7;
BA_ "InvalidValue" SG_ 1610 LDM_R_DiagRespData4 "null";
BA_ "GenSigSendType" SG_ 1610 LDM_R_DiagRespData5 7;
BA_ "InvalidValue" SG_ 1610 LDM_R_DiagRespData5 "null";
BA_ "GenSigSendType" SG_ 1610 LDM_R_DiagRespData6 7;
BA_ "InvalidValue" SG_ 1610 LDM_R_DiagRespData6 "null";
BA_ "GenSigSendType" SG_ 1610 LDM_R_DiagRespData7 7;
BA_ "InvalidValue" SG_ 1610 LDM_R_DiagRespData7 "null";
BA_ "GenSigSendType" SG_ 1624 BAS_DiagRespData0 7;
BA_ "InvalidValue" SG_ 1624 BAS_DiagRespData0 "null";
BA_ "GenSigSendType" SG_ 1624 BAS_DiagRespData1 7;
BA_ "InvalidValue" SG_ 1624 BAS_DiagRespData1 "null";
BA_ "GenSigSendType" SG_ 1624 BAS_DiagRespData2 7;
BA_ "InvalidValue" SG_ 1624 BAS_DiagRespData2 "null";
BA_ "GenSigSendType" SG_ 1624 BAS_DiagRespData3 7;
BA_ "InvalidValue" SG_ 1624 BAS_DiagRespData3 "null";
BA_ "GenSigSendType" SG_ 1624 BAS_DiagRespData4 7;
BA_ "InvalidValue" SG_ 1624 BAS_DiagRespData4 "null";
BA_ "GenSigSendType" SG_ 1624 BAS_DiagRespData5 7;
BA_ "InvalidValue" SG_ 1624 BAS_DiagRespData5 "null";
BA_ "GenSigSendType" SG_ 1624 BAS_DiagRespData6 7;
BA_ "InvalidValue" SG_ 1624 BAS_DiagRespData6 "null";
BA_ "GenSigSendType" SG_ 1624 BAS_DiagRespData7 7;
BA_ "InvalidValue" SG_ 1624 BAS_DiagRespData7 "null";
BA_ "GenSigSendType" SG_ 1636 DCM_APM_DiagRespData0 7;
BA_ "InvalidValue" SG_ 1636 DCM_APM_DiagRespData0 "null";
BA_ "GenSigSendType" SG_ 1636 DCM_APM_DiagRespData1 7;
BA_ "InvalidValue" SG_ 1636 DCM_APM_DiagRespData1 "null";
BA_ "GenSigSendType" SG_ 1636 DCM_APM_DiagRespData2 7;
BA_ "InvalidValue" SG_ 1636 DCM_APM_DiagRespData2 "null";
BA_ "GenSigSendType" SG_ 1636 DCM_APM_DiagRespData3 7;
BA_ "InvalidValue" SG_ 1636 DCM_APM_DiagRespData3 "null";
BA_ "GenSigSendType" SG_ 1636 DCM_APM_DiagRespData4 7;
BA_ "InvalidValue" SG_ 1636 DCM_APM_DiagRespData4 "null";
BA_ "GenSigSendType" SG_ 1636 DCM_APM_DiagRespData5 7;
BA_ "InvalidValue" SG_ 1636 DCM_APM_DiagRespData5 "null";
BA_ "GenSigSendType" SG_ 1636 DCM_APM_DiagRespData6 7;
BA_ "InvalidValue" SG_ 1636 DCM_APM_DiagRespData6 "null";
BA_ "GenSigSendType" SG_ 1636 DCM_APM_DiagRespData7 7;
BA_ "InvalidValue" SG_ 1636 DCM_APM_DiagRespData7 "null";
BA_ "GenSigSendType" SG_ 1659 BCM_BPM_DiagRespData0 7;
BA_ "InvalidValue" SG_ 1659 BCM_BPM_DiagRespData0 "null";
BA_ "GenSigSendType" SG_ 1659 BCM_BPM_DiagRespData1 7;
BA_ "InvalidValue" SG_ 1659 BCM_BPM_DiagRespData1 "null";
BA_ "GenSigSendType" SG_ 1659 BCM_BPM_DiagRespData2 7;
BA_ "InvalidValue" SG_ 1659 BCM_BPM_DiagRespData2 "null";
BA_ "GenSigSendType" SG_ 1659 BCM_BPM_DiagRespData3 7;
BA_ "InvalidValue" SG_ 1659 BCM_BPM_DiagRespData3 "null";
BA_ "GenSigSendType" SG_ 1659 BCM_BPM_DiagRespData4 7;
BA_ "InvalidValue" SG_ 1659 BCM_BPM_DiagRespData4 "null";
BA_ "GenSigSendType" SG_ 1659 BCM_BPM_DiagRespData5 7;
BA_ "InvalidValue" SG_ 1659 BCM_BPM_DiagRespData5 "null";
BA_ "GenSigSendType" SG_ 1659 BCM_BPM_DiagRespData6 7;
BA_ "InvalidValue" SG_ 1659 BCM_BPM_DiagRespData6 "null";
BA_ "GenSigSendType" SG_ 1659 BCM_BPM_DiagRespData7 7;
BA_ "InvalidValue" SG_ 1659 BCM_BPM_DiagRespData7 "null";
BA_ "GenSigSendType" SG_ 1665 BCM_DiagReqData0 7;
BA_ "InvalidValue" SG_ 1665 BCM_DiagReqData0 "null";
BA_ "GenSigSendType" SG_ 1665 BCM_DiagReqData1 7;
BA_ "InvalidValue" SG_ 1665 BCM_DiagReqData1 "null";
BA_ "GenSigSendType" SG_ 1665 BCM_DiagReqData2 7;
BA_ "InvalidValue" SG_ 1665 BCM_DiagReqData2 "null";
BA_ "GenSigSendType" SG_ 1665 BCM_DiagReqData3 7;
BA_ "InvalidValue" SG_ 1665 BCM_DiagReqData3 "null";
BA_ "GenSigSendType" SG_ 1665 BCM_DiagReqData4 7;
BA_ "InvalidValue" SG_ 1665 BCM_DiagReqData4 "null";
BA_ "GenSigSendType" SG_ 1665 BCM_DiagReqData5 7;
BA_ "InvalidValue" SG_ 1665 BCM_DiagReqData5 "null";
BA_ "GenSigSendType" SG_ 1665 BCM_DiagReqData6 7;
BA_ "InvalidValue" SG_ 1665 BCM_DiagReqData6 "null";
BA_ "GenSigSendType" SG_ 1665 BCM_DiagReqData7 7;
BA_ "InvalidValue" SG_ 1665 BCM_DiagReqData7 "null";
BA_ "GenSigSendType" SG_ 1666 XGW_DiagReqData0 7;
BA_ "InvalidValue" SG_ 1666 XGW_DiagReqData0 "null";
BA_ "GenSigSendType" SG_ 1666 XGW_DiagReqData1 7;
BA_ "InvalidValue" SG_ 1666 XGW_DiagReqData1 "null";
BA_ "GenSigSendType" SG_ 1666 XGW_DiagReqData2 7;
BA_ "InvalidValue" SG_ 1666 XGW_DiagReqData2 "null";
BA_ "GenSigSendType" SG_ 1666 XGW_DiagReqData3 7;
BA_ "InvalidValue" SG_ 1666 XGW_DiagReqData3 "null";
BA_ "GenSigSendType" SG_ 1666 XGW_DiagReqData4 7;
BA_ "InvalidValue" SG_ 1666 XGW_DiagReqData4 "null";
BA_ "GenSigSendType" SG_ 1666 XGW_DiagReqData5 7;
BA_ "InvalidValue" SG_ 1666 XGW_DiagReqData5 "null";
BA_ "GenSigSendType" SG_ 1666 XGW_DiagReqData6 7;
BA_ "InvalidValue" SG_ 1666 XGW_DiagReqData6 "null";
BA_ "GenSigSendType" SG_ 1666 XGW_DiagReqData7 7;
BA_ "InvalidValue" SG_ 1666 XGW_DiagReqData7 "null";
BA_ "GenSigSendType" SG_ 1668 MHU_DiagReqData0 7;
BA_ "InvalidValue" SG_ 1668 MHU_DiagReqData0 "null";
BA_ "GenSigSendType" SG_ 1668 MHU_DiagReqData1 7;
BA_ "InvalidValue" SG_ 1668 MHU_DiagReqData1 "null";
BA_ "GenSigSendType" SG_ 1668 MHU_DiagReqData2 7;
BA_ "InvalidValue" SG_ 1668 MHU_DiagReqData2 "null";
BA_ "GenSigSendType" SG_ 1668 MHU_DiagReqData3 7;
BA_ "InvalidValue" SG_ 1668 MHU_DiagReqData3 "null";
BA_ "GenSigSendType" SG_ 1668 MHU_DiagReqData4 7;
BA_ "InvalidValue" SG_ 1668 MHU_DiagReqData4 "null";
BA_ "GenSigSendType" SG_ 1668 MHU_DiagReqData5 7;
BA_ "InvalidValue" SG_ 1668 MHU_DiagReqData5 "null";
BA_ "GenSigSendType" SG_ 1668 MHU_DiagReqData6 7;
BA_ "InvalidValue" SG_ 1668 MHU_DiagReqData6 "null";
BA_ "GenSigSendType" SG_ 1668 MHU_DiagReqData7 7;
BA_ "InvalidValue" SG_ 1668 MHU_DiagReqData7 "null";
BA_ "GenSigSendType" SG_ 1669 AMP_DiagReqData0 7;
BA_ "InvalidValue" SG_ 1669 AMP_DiagReqData0 "null";
BA_ "GenSigSendType" SG_ 1669 AMP_DiagReqData1 7;
BA_ "InvalidValue" SG_ 1669 AMP_DiagReqData1 "null";
BA_ "GenSigSendType" SG_ 1669 AMP_DiagReqData2 7;
BA_ "InvalidValue" SG_ 1669 AMP_DiagReqData2 "null";
BA_ "GenSigSendType" SG_ 1669 AMP_DiagReqData3 7;
BA_ "InvalidValue" SG_ 1669 AMP_DiagReqData3 "null";
BA_ "GenSigSendType" SG_ 1669 AMP_DiagReqData4 7;
BA_ "InvalidValue" SG_ 1669 AMP_DiagReqData4 "null";
BA_ "GenSigSendType" SG_ 1669 AMP_DiagReqData5 7;
BA_ "InvalidValue" SG_ 1669 AMP_DiagReqData5 "null";
BA_ "GenSigSendType" SG_ 1669 AMP_DiagReqData6 7;
BA_ "InvalidValue" SG_ 1669 AMP_DiagReqData6 "null";
BA_ "GenSigSendType" SG_ 1669 AMP_DiagReqData7 7;
BA_ "InvalidValue" SG_ 1669 AMP_DiagReqData7 "null";
BA_ "GenSigSendType" SG_ 1672 ACM_DiagReqData0 7;
BA_ "InvalidValue" SG_ 1672 ACM_DiagReqData0 "null";
BA_ "GenSigSendType" SG_ 1672 ACM_DiagReqData1 7;
BA_ "InvalidValue" SG_ 1672 ACM_DiagReqData1 "null";
BA_ "GenSigSendType" SG_ 1672 ACM_DiagReqData2 7;
BA_ "InvalidValue" SG_ 1672 ACM_DiagReqData2 "null";
BA_ "GenSigSendType" SG_ 1672 ACM_DiagReqData3 7;
BA_ "InvalidValue" SG_ 1672 ACM_DiagReqData3 "null";
BA_ "GenSigSendType" SG_ 1672 ACM_DiagReqData4 7;
BA_ "InvalidValue" SG_ 1672 ACM_DiagReqData4 "null";
BA_ "GenSigSendType" SG_ 1672 ACM_DiagReqData5 7;
BA_ "InvalidValue" SG_ 1672 ACM_DiagReqData5 "null";
BA_ "GenSigSendType" SG_ 1672 ACM_DiagReqData6 7;
BA_ "InvalidValue" SG_ 1672 ACM_DiagReqData6 "null";
BA_ "GenSigSendType" SG_ 1672 ACM_DiagReqData7 7;
BA_ "InvalidValue" SG_ 1672 ACM_DiagReqData7 "null";
BA_ "GenSigSendType" SG_ 1673 CCUF_DiagReqData0 7;
BA_ "InvalidValue" SG_ 1673 CCUF_DiagReqData0 "null";
BA_ "GenSigSendType" SG_ 1673 CCUF_DiagReqData1 7;
BA_ "InvalidValue" SG_ 1673 CCUF_DiagReqData1 "null";
BA_ "GenSigSendType" SG_ 1673 CCUF_DiagReqData2 7;
BA_ "InvalidValue" SG_ 1673 CCUF_DiagReqData2 "null";
BA_ "GenSigSendType" SG_ 1673 CCUF_DiagReqData3 7;
BA_ "InvalidValue" SG_ 1673 CCUF_DiagReqData3 "null";
BA_ "GenSigSendType" SG_ 1673 CCUF_DiagReqData4 7;
BA_ "InvalidValue" SG_ 1673 CCUF_DiagReqData4 "null";
BA_ "GenSigSendType" SG_ 1673 CCUF_DiagReqData5 7;
BA_ "InvalidValue" SG_ 1673 CCUF_DiagReqData5 "null";
BA_ "GenSigSendType" SG_ 1673 CCUF_DiagReqData6 7;
BA_ "InvalidValue" SG_ 1673 CCUF_DiagReqData6 "null";
BA_ "GenSigSendType" SG_ 1673 CCUF_DiagReqData7 7;
BA_ "InvalidValue" SG_ 1673 CCUF_DiagReqData7 "null";
BA_ "GenSigSendType" SG_ 1677 HUD_DiagReqData0 7;
BA_ "InvalidValue" SG_ 1677 HUD_DiagReqData0 "null";
BA_ "GenSigSendType" SG_ 1677 HUD_DiagReqData1 7;
BA_ "InvalidValue" SG_ 1677 HUD_DiagReqData1 "null";
BA_ "GenSigSendType" SG_ 1677 HUD_DiagReqData2 7;
BA_ "InvalidValue" SG_ 1677 HUD_DiagReqData2 "null";
BA_ "GenSigSendType" SG_ 1677 HUD_DiagReqData3 7;
BA_ "InvalidValue" SG_ 1677 HUD_DiagReqData3 "null";
BA_ "GenSigSendType" SG_ 1677 HUD_DiagReqData4 7;
BA_ "InvalidValue" SG_ 1677 HUD_DiagReqData4 "null";
BA_ "GenSigSendType" SG_ 1677 HUD_DiagReqData5 7;
BA_ "InvalidValue" SG_ 1677 HUD_DiagReqData5 "null";
BA_ "GenSigSendType" SG_ 1677 HUD_DiagReqData6 7;
BA_ "InvalidValue" SG_ 1677 HUD_DiagReqData6 "null";
BA_ "GenSigSendType" SG_ 1677 HUD_DiagReqData7 7;
BA_ "InvalidValue" SG_ 1677 HUD_DiagReqData7 "null";
BA_ "GenSigSendType" SG_ 1678 ETG_DiagReqData0 7;
BA_ "InvalidValue" SG_ 1678 ETG_DiagReqData0 "null";
BA_ "GenSigSendType" SG_ 1678 ETG_DiagReqData1 7;
BA_ "InvalidValue" SG_ 1678 ETG_DiagReqData1 "null";
BA_ "GenSigSendType" SG_ 1678 ETG_DiagReqData2 7;
BA_ "InvalidValue" SG_ 1678 ETG_DiagReqData2 "null";
BA_ "GenSigSendType" SG_ 1678 ETG_DiagReqData3 7;
BA_ "InvalidValue" SG_ 1678 ETG_DiagReqData3 "null";
BA_ "GenSigSendType" SG_ 1678 ETG_DiagReqData4 7;
BA_ "InvalidValue" SG_ 1678 ETG_DiagReqData4 "null";
BA_ "GenSigSendType" SG_ 1678 ETG_DiagReqData5 7;
BA_ "InvalidValue" SG_ 1678 ETG_DiagReqData5 "null";
BA_ "GenSigSendType" SG_ 1678 ETG_DiagReqData6 7;
BA_ "InvalidValue" SG_ 1678 ETG_DiagReqData6 "null";
BA_ "GenSigSendType" SG_ 1678 ETG_DiagReqData7 7;
BA_ "InvalidValue" SG_ 1678 ETG_DiagReqData7 "null";
BA_ "GenSigSendType" SG_ 1679 YSS_DiagReqData0 7;
BA_ "InvalidValue" SG_ 1679 YSS_DiagReqData0 "null";
BA_ "GenSigSendType" SG_ 1679 YSS_DiagReqData1 7;
BA_ "InvalidValue" SG_ 1679 YSS_DiagReqData1 "null";
BA_ "GenSigSendType" SG_ 1679 YSS_DiagReqData2 7;
BA_ "InvalidValue" SG_ 1679 YSS_DiagReqData2 "null";
BA_ "GenSigSendType" SG_ 1679 YSS_DiagReqData3 7;
BA_ "InvalidValue" SG_ 1679 YSS_DiagReqData3 "null";
BA_ "GenSigSendType" SG_ 1679 YSS_DiagReqData4 7;
BA_ "InvalidValue" SG_ 1679 YSS_DiagReqData4 "null";
BA_ "GenSigSendType" SG_ 1679 YSS_DiagReqData5 7;
BA_ "InvalidValue" SG_ 1679 YSS_DiagReqData5 "null";
BA_ "GenSigSendType" SG_ 1679 YSS_DiagReqData6 7;
BA_ "InvalidValue" SG_ 1679 YSS_DiagReqData6 "null";
BA_ "GenSigSendType" SG_ 1679 YSS_DiagReqData7 7;
BA_ "InvalidValue" SG_ 1679 YSS_DiagReqData7 "null";
BA_ "GenSigSendType" SG_ 1680 GS_DiagReqData0 7;
BA_ "InvalidValue" SG_ 1680 GS_DiagReqData0 "null";
BA_ "GenSigSendType" SG_ 1680 GS_DiagReqData1 7;
BA_ "InvalidValue" SG_ 1680 GS_DiagReqData1 "null";
BA_ "GenSigSendType" SG_ 1680 GS_DiagReqData2 7;
BA_ "InvalidValue" SG_ 1680 GS_DiagReqData2 "null";
BA_ "GenSigSendType" SG_ 1680 GS_DiagReqData3 7;
BA_ "InvalidValue" SG_ 1680 GS_DiagReqData3 "null";
BA_ "GenSigSendType" SG_ 1680 GS_DiagReqData4 7;
BA_ "InvalidValue" SG_ 1680 GS_DiagReqData4 "null";
BA_ "GenSigSendType" SG_ 1680 GS_DiagReqData5 7;
BA_ "InvalidValue" SG_ 1680 GS_DiagReqData5 "null";
BA_ "GenSigSendType" SG_ 1680 GS_DiagReqData6 7;
BA_ "InvalidValue" SG_ 1680 GS_DiagReqData6 "null";
BA_ "GenSigSendType" SG_ 1680 GS_DiagReqData7 7;
BA_ "InvalidValue" SG_ 1680 GS_DiagReqData7 "null";
BA_ "GenSigSendType" SG_ 1683 BMS_DiagReqData0 7;
BA_ "InvalidValue" SG_ 1683 BMS_DiagReqData0 "null";
BA_ "GenSigSendType" SG_ 1683 BMS_DiagReqData1 7;
BA_ "InvalidValue" SG_ 1683 BMS_DiagReqData1 "null";
BA_ "GenSigSendType" SG_ 1683 BMS_DiagReqData2 7;
BA_ "InvalidValue" SG_ 1683 BMS_DiagReqData2 "null";
BA_ "GenSigSendType" SG_ 1683 BMS_DiagReqData3 7;
BA_ "InvalidValue" SG_ 1683 BMS_DiagReqData3 "null";
BA_ "GenSigSendType" SG_ 1683 BMS_DiagReqData4 7;
BA_ "InvalidValue" SG_ 1683 BMS_DiagReqData4 "null";
BA_ "GenSigSendType" SG_ 1683 BMS_DiagReqData5 7;
BA_ "InvalidValue" SG_ 1683 BMS_DiagReqData5 "null";
BA_ "GenSigSendType" SG_ 1683 BMS_DiagReqData6 7;
BA_ "InvalidValue" SG_ 1683 BMS_DiagReqData6 "null";
BA_ "GenSigSendType" SG_ 1683 BMS_DiagReqData7 7;
BA_ "InvalidValue" SG_ 1683 BMS_DiagReqData7 "null";
BA_ "GenSigSendType" SG_ 1684 CCUR_DiagReqData0 7;
BA_ "InvalidValue" SG_ 1684 CCUR_DiagReqData0 "null";
BA_ "GenSigSendType" SG_ 1684 CCUR_DiagReqData1 7;
BA_ "InvalidValue" SG_ 1684 CCUR_DiagReqData1 "null";
BA_ "GenSigSendType" SG_ 1684 CCUR_DiagReqData2 7;
BA_ "InvalidValue" SG_ 1684 CCUR_DiagReqData2 "null";
BA_ "GenSigSendType" SG_ 1684 CCUR_DiagReqData3 7;
BA_ "InvalidValue" SG_ 1684 CCUR_DiagReqData3 "null";
BA_ "GenSigSendType" SG_ 1684 CCUR_DiagReqData4 7;
BA_ "InvalidValue" SG_ 1684 CCUR_DiagReqData4 "null";
BA_ "GenSigSendType" SG_ 1684 CCUR_DiagReqData5 7;
BA_ "InvalidValue" SG_ 1684 CCUR_DiagReqData5 "null";
BA_ "GenSigSendType" SG_ 1684 CCUR_DiagReqData6 7;
BA_ "InvalidValue" SG_ 1684 CCUR_DiagReqData6 "null";
BA_ "GenSigSendType" SG_ 1684 CCUR_DiagReqData7 7;
BA_ "InvalidValue" SG_ 1684 CCUR_DiagReqData7 "null";
BA_ "GenSigSendType" SG_ 1686 FCAM_DiagReqData0 7;
BA_ "GenSigSendType" SG_ 1686 FCAM_DiagReqData1 7;
BA_ "GenSigSendType" SG_ 1686 FCAM_DiagReqData2 7;
BA_ "GenSigSendType" SG_ 1686 FCAM_DiagReqData3 7;
BA_ "GenSigSendType" SG_ 1686 FCAM_DiagReqData4 7;
BA_ "GenSigSendType" SG_ 1686 FCAM_DiagReqData5 7;
BA_ "GenSigSendType" SG_ 1686 FCAM_DiagReqData6 7;
BA_ "GenSigSendType" SG_ 1686 FCAM_DiagReqData7 7;
BA_ "GenSigSendType" SG_ 1687 PAS_DiagReqData0 7;
BA_ "GenSigSendType" SG_ 1687 PAS_DiagReqData1 7;
BA_ "GenSigSendType" SG_ 1687 PAS_DiagReqData2 7;
BA_ "GenSigSendType" SG_ 1687 PAS_DiagReqData3 7;
BA_ "GenSigSendType" SG_ 1687 PAS_DiagReqData4 7;
BA_ "GenSigSendType" SG_ 1687 PAS_DiagReqData5 7;
BA_ "GenSigSendType" SG_ 1687 PAS_DiagReqData6 7;
BA_ "GenSigSendType" SG_ 1687 PAS_DiagReqData7 7;
BA_ "GenSigSendType" SG_ 1690 EDS_R_DiagReqData0 7;
BA_ "InvalidValue" SG_ 1690 EDS_R_DiagReqData0 "null";
BA_ "GenSigSendType" SG_ 1690 EDS_R_DiagReqData1 7;
BA_ "InvalidValue" SG_ 1690 EDS_R_DiagReqData1 "null";
BA_ "GenSigSendType" SG_ 1690 EDS_R_DiagReqData2 7;
BA_ "InvalidValue" SG_ 1690 EDS_R_DiagReqData2 "null";
BA_ "GenSigSendType" SG_ 1690 EDS_R_DiagReqData3 7;
BA_ "InvalidValue" SG_ 1690 EDS_R_DiagReqData3 "null";
BA_ "GenSigSendType" SG_ 1690 EDS_R_DiagReqData4 7;
BA_ "InvalidValue" SG_ 1690 EDS_R_DiagReqData4 "null";
BA_ "GenSigSendType" SG_ 1690 EDS_R_DiagReqData5 7;
BA_ "InvalidValue" SG_ 1690 EDS_R_DiagReqData5 "null";
BA_ "GenSigSendType" SG_ 1690 EDS_R_DiagReqData6 7;
BA_ "InvalidValue" SG_ 1690 EDS_R_DiagReqData6 "null";
BA_ "GenSigSendType" SG_ 1690 EDS_R_DiagReqData7 7;
BA_ "InvalidValue" SG_ 1690 EDS_R_DiagReqData7 "null";
BA_ "GenSigSendType" SG_ 1691 EDS_F_DiagReqData0 7;
BA_ "InvalidValue" SG_ 1691 EDS_F_DiagReqData0 "null";
BA_ "GenSigSendType" SG_ 1691 EDS_F_DiagReqData1 7;
BA_ "InvalidValue" SG_ 1691 EDS_F_DiagReqData1 "null";
BA_ "GenSigSendType" SG_ 1691 EDS_F_DiagReqData2 7;
BA_ "InvalidValue" SG_ 1691 EDS_F_DiagReqData2 "null";
BA_ "GenSigSendType" SG_ 1691 EDS_F_DiagReqData3 7;
BA_ "InvalidValue" SG_ 1691 EDS_F_DiagReqData3 "null";
BA_ "GenSigSendType" SG_ 1691 EDS_F_DiagReqData4 7;
BA_ "InvalidValue" SG_ 1691 EDS_F_DiagReqData4 "null";
BA_ "GenSigSendType" SG_ 1691 EDS_F_DiagReqData5 7;
BA_ "InvalidValue" SG_ 1691 EDS_F_DiagReqData5 "null";
BA_ "GenSigSendType" SG_ 1691 EDS_F_DiagReqData6 7;
BA_ "InvalidValue" SG_ 1691 EDS_F_DiagReqData6 "null";
BA_ "GenSigSendType" SG_ 1691 EDS_F_DiagReqData7 7;
BA_ "InvalidValue" SG_ 1691 EDS_F_DiagReqData7 "null";
BA_ "GenSigSendType" SG_ 1694 PSM_D_DiagReqData0 7;
BA_ "InvalidValue" SG_ 1694 PSM_D_DiagReqData0 "null";
BA_ "GenSigSendType" SG_ 1694 PSM_D_DiagReqData1 7;
BA_ "InvalidValue" SG_ 1694 PSM_D_DiagReqData1 "null";
BA_ "GenSigSendType" SG_ 1694 PSM_D_DiagReqData2 7;
BA_ "InvalidValue" SG_ 1694 PSM_D_DiagReqData2 "null";
BA_ "GenSigSendType" SG_ 1694 PSM_D_DiagReqData3 7;
BA_ "InvalidValue" SG_ 1694 PSM_D_DiagReqData3 "null";
BA_ "GenSigSendType" SG_ 1694 PSM_D_DiagReqData4 7;
BA_ "InvalidValue" SG_ 1694 PSM_D_DiagReqData4 "null";
BA_ "GenSigSendType" SG_ 1694 PSM_D_DiagReqData5 7;
BA_ "InvalidValue" SG_ 1694 PSM_D_DiagReqData5 "null";
BA_ "GenSigSendType" SG_ 1694 PSM_D_DiagReqData6 7;
BA_ "InvalidValue" SG_ 1694 PSM_D_DiagReqData6 "null";
BA_ "GenSigSendType" SG_ 1694 PSM_D_DiagReqData7 7;
BA_ "InvalidValue" SG_ 1694 PSM_D_DiagReqData7 "null";
BA_ "InvalidValue" SG_ 1701 MRGEN_DiagReqData0 "";
BA_ "GenSigSendType" SG_ 1701 MRGEN_DiagReqData0 7;
BA_ "InvalidValue" SG_ 1701 MRGEN_DiagReqData1 "";
BA_ "GenSigSendType" SG_ 1701 MRGEN_DiagReqData1 7;
BA_ "InvalidValue" SG_ 1701 MRGEN_DiagReqData2 "";
BA_ "GenSigSendType" SG_ 1701 MRGEN_DiagReqData2 7;
BA_ "InvalidValue" SG_ 1701 MRGEN_DiagReqData3 "";
BA_ "GenSigSendType" SG_ 1701 MRGEN_DiagReqData3 7;
BA_ "InvalidValue" SG_ 1701 MRGEN_DiagReqData4 "";
BA_ "GenSigSendType" SG_ 1701 MRGEN_DiagReqData4 7;
BA_ "InvalidValue" SG_ 1701 MRGEN_DiagReqData5 "";
BA_ "GenSigSendType" SG_ 1701 MRGEN_DiagReqData5 7;
BA_ "InvalidValue" SG_ 1701 MRGEN_DiagReqData6 "";
BA_ "GenSigSendType" SG_ 1701 MRGEN_DiagReqData6 7;
BA_ "InvalidValue" SG_ 1701 MRGEN_DiagReqData7 "";
BA_ "GenSigSendType" SG_ 1701 MRGEN_DiagReqData7 7;
BA_ "GenSigSendType" SG_ 1703 RCU_DiagReqData0 7;
BA_ "InvalidValue" SG_ 1703 RCU_DiagReqData0 "null";
BA_ "GenSigSendType" SG_ 1703 RCU_DiagReqData1 7;
BA_ "InvalidValue" SG_ 1703 RCU_DiagReqData1 "null";
BA_ "GenSigSendType" SG_ 1703 RCU_DiagReqData2 7;
BA_ "InvalidValue" SG_ 1703 RCU_DiagReqData2 "null";
BA_ "GenSigSendType" SG_ 1703 RCU_DiagReqData3 7;
BA_ "InvalidValue" SG_ 1703 RCU_DiagReqData3 "null";
BA_ "GenSigSendType" SG_ 1703 RCU_DiagReqData4 7;
BA_ "InvalidValue" SG_ 1703 RCU_DiagReqData4 "null";
BA_ "GenSigSendType" SG_ 1703 RCU_DiagReqData5 7;
BA_ "InvalidValue" SG_ 1703 RCU_DiagReqData5 "null";
BA_ "GenSigSendType" SG_ 1703 RCU_DiagReqData6 7;
BA_ "InvalidValue" SG_ 1703 RCU_DiagReqData6 "null";
BA_ "GenSigSendType" SG_ 1703 RCU_DiagReqData7 7;
BA_ "InvalidValue" SG_ 1703 RCU_DiagReqData7 "null";
BA_ "GenSigSendType" SG_ 1704 EPS_DiagReqData0 7;
BA_ "InvalidValue" SG_ 1704 EPS_DiagReqData0 "null";
BA_ "GenSigSendType" SG_ 1704 EPS_DiagReqData1 7;
BA_ "InvalidValue" SG_ 1704 EPS_DiagReqData1 "null";
BA_ "GenSigSendType" SG_ 1704 EPS_DiagReqData2 7;
BA_ "InvalidValue" SG_ 1704 EPS_DiagReqData2 "null";
BA_ "GenSigSendType" SG_ 1704 EPS_DiagReqData3 7;
BA_ "InvalidValue" SG_ 1704 EPS_DiagReqData3 "null";
BA_ "GenSigSendType" SG_ 1704 EPS_DiagReqData4 7;
BA_ "InvalidValue" SG_ 1704 EPS_DiagReqData4 "null";
BA_ "GenSigSendType" SG_ 1704 EPS_DiagReqData5 7;
BA_ "InvalidValue" SG_ 1704 EPS_DiagReqData5 "null";
BA_ "GenSigSendType" SG_ 1704 EPS_DiagReqData6 7;
BA_ "InvalidValue" SG_ 1704 EPS_DiagReqData6 "null";
BA_ "GenSigSendType" SG_ 1704 EPS_DiagReqData7 7;
BA_ "InvalidValue" SG_ 1704 EPS_DiagReqData7 "null";
BA_ "GenSigSendType" SG_ 1705 IDB_DiagReqData0 7;
BA_ "InvalidValue" SG_ 1705 IDB_DiagReqData0 "null";
BA_ "GenSigSendType" SG_ 1705 IDB_DiagReqData1 7;
BA_ "InvalidValue" SG_ 1705 IDB_DiagReqData1 "null";
BA_ "GenSigSendType" SG_ 1705 IDB_DiagReqData2 7;
BA_ "InvalidValue" SG_ 1705 IDB_DiagReqData2 "null";
BA_ "GenSigSendType" SG_ 1705 IDB_DiagReqData3 7;
BA_ "InvalidValue" SG_ 1705 IDB_DiagReqData3 "null";
BA_ "GenSigSendType" SG_ 1705 IDB_DiagReqData4 7;
BA_ "InvalidValue" SG_ 1705 IDB_DiagReqData4 "null";
BA_ "GenSigSendType" SG_ 1705 IDB_DiagReqData5 7;
BA_ "InvalidValue" SG_ 1705 IDB_DiagReqData5 "null";
BA_ "GenSigSendType" SG_ 1705 IDB_DiagReqData6 7;
BA_ "InvalidValue" SG_ 1705 IDB_DiagReqData6 "null";
BA_ "GenSigSendType" SG_ 1705 IDB_DiagReqData7 7;
BA_ "InvalidValue" SG_ 1705 IDB_DiagReqData7 "null";
BA_ "GenSigSendType" SG_ 1706 AVAS_DiagReqData0 7;
BA_ "InvalidValue" SG_ 1706 AVAS_DiagReqData0 "null";
BA_ "GenSigSendType" SG_ 1706 AVAS_DiagReqData1 7;
BA_ "InvalidValue" SG_ 1706 AVAS_DiagReqData1 "null";
BA_ "GenSigSendType" SG_ 1706 AVAS_DiagReqData2 7;
BA_ "InvalidValue" SG_ 1706 AVAS_DiagReqData2 "null";
BA_ "GenSigSendType" SG_ 1706 AVAS_DiagReqData3 7;
BA_ "InvalidValue" SG_ 1706 AVAS_DiagReqData3 "null";
BA_ "GenSigSendType" SG_ 1706 AVAS_DiagReqData4 7;
BA_ "InvalidValue" SG_ 1706 AVAS_DiagReqData4 "null";
BA_ "GenSigSendType" SG_ 1706 AVAS_DiagReqData5 7;
BA_ "InvalidValue" SG_ 1706 AVAS_DiagReqData5 "null";
BA_ "GenSigSendType" SG_ 1706 AVAS_DiagReqData6 7;
BA_ "InvalidValue" SG_ 1706 AVAS_DiagReqData6 "null";
BA_ "GenSigSendType" SG_ 1706 AVAS_DiagReqData7 7;
BA_ "InvalidValue" SG_ 1706 AVAS_DiagReqData7 "null";
BA_ "GenSigSendType" SG_ 1707 EPS2_DiagReqData0 7;
BA_ "InvalidValue" SG_ 1707 EPS2_DiagReqData0 "null";
BA_ "GenSigSendType" SG_ 1707 EPS2_DiagReqData1 7;
BA_ "InvalidValue" SG_ 1707 EPS2_DiagReqData1 "null";
BA_ "GenSigSendType" SG_ 1707 EPS2_DiagReqData2 7;
BA_ "InvalidValue" SG_ 1707 EPS2_DiagReqData2 "null";
BA_ "GenSigSendType" SG_ 1707 EPS2_DiagReqData3 7;
BA_ "InvalidValue" SG_ 1707 EPS2_DiagReqData3 "null";
BA_ "GenSigSendType" SG_ 1707 EPS2_DiagReqData4 7;
BA_ "InvalidValue" SG_ 1707 EPS2_DiagReqData4 "null";
BA_ "GenSigSendType" SG_ 1707 EPS2_DiagReqData5 7;
BA_ "InvalidValue" SG_ 1707 EPS2_DiagReqData5 "null";
BA_ "GenSigSendType" SG_ 1707 EPS2_DiagReqData6 7;
BA_ "InvalidValue" SG_ 1707 EPS2_DiagReqData6 "null";
BA_ "GenSigSendType" SG_ 1707 EPS2_DiagReqData7 7;
BA_ "InvalidValue" SG_ 1707 EPS2_DiagReqData7 "null";
BA_ "GenSigSendType" SG_ 1708 VCU_DiagReqData0 7;
BA_ "InvalidValue" SG_ 1708 VCU_DiagReqData0 "null";
BA_ "GenSigSendType" SG_ 1708 VCU_DiagReqData1 7;
BA_ "InvalidValue" SG_ 1708 VCU_DiagReqData1 "null";
BA_ "GenSigSendType" SG_ 1708 VCU_DiagReqData2 7;
BA_ "InvalidValue" SG_ 1708 VCU_DiagReqData2 "null";
BA_ "GenSigSendType" SG_ 1708 VCU_DiagReqData3 7;
BA_ "InvalidValue" SG_ 1708 VCU_DiagReqData3 "null";
BA_ "GenSigSendType" SG_ 1708 VCU_DiagReqData4 7;
BA_ "InvalidValue" SG_ 1708 VCU_DiagReqData4 "null";
BA_ "GenSigSendType" SG_ 1708 VCU_DiagReqData5 7;
BA_ "InvalidValue" SG_ 1708 VCU_DiagReqData5 "null";
BA_ "GenSigSendType" SG_ 1708 VCU_DiagReqData6 7;
BA_ "InvalidValue" SG_ 1708 VCU_DiagReqData6 "null";
BA_ "GenSigSendType" SG_ 1708 VCU_DiagReqData7 7;
BA_ "InvalidValue" SG_ 1708 VCU_DiagReqData7 "null";
BA_ "GenSigSendType" SG_ 1710 EASC_DiagReqData0 7;
BA_ "InvalidValue" SG_ 1710 EASC_DiagReqData0 "null";
BA_ "GenSigSendType" SG_ 1710 EASC_DiagReqData1 7;
BA_ "InvalidValue" SG_ 1710 EASC_DiagReqData1 "null";
BA_ "GenSigSendType" SG_ 1710 EASC_DiagReqData2 7;
BA_ "InvalidValue" SG_ 1710 EASC_DiagReqData2 "null";
BA_ "GenSigSendType" SG_ 1710 EASC_DiagReqData3 7;
BA_ "InvalidValue" SG_ 1710 EASC_DiagReqData3 "null";
BA_ "GenSigSendType" SG_ 1710 EASC_DiagReqData4 7;
BA_ "InvalidValue" SG_ 1710 EASC_DiagReqData4 "null";
BA_ "GenSigSendType" SG_ 1710 EASC_DiagReqData5 7;
BA_ "InvalidValue" SG_ 1710 EASC_DiagReqData5 "null";
BA_ "GenSigSendType" SG_ 1710 EASC_DiagReqData6 7;
BA_ "InvalidValue" SG_ 1710 EASC_DiagReqData6 "null";
BA_ "GenSigSendType" SG_ 1710 EASC_DiagReqData7 7;
BA_ "InvalidValue" SG_ 1710 EASC_DiagReqData7 "null";
BA_ "GenSigSendType" SG_ 1711 CPD_DiagReqData0 7;
BA_ "InvalidValue" SG_ 1711 CPD_DiagReqData0 "null";
BA_ "GenSigSendType" SG_ 1711 CPD_DiagReqData1 7;
BA_ "InvalidValue" SG_ 1711 CPD_DiagReqData1 "null";
BA_ "GenSigSendType" SG_ 1711 CPD_DiagReqData2 7;
BA_ "InvalidValue" SG_ 1711 CPD_DiagReqData2 "null";
BA_ "GenSigSendType" SG_ 1711 CPD_DiagReqData3 7;
BA_ "InvalidValue" SG_ 1711 CPD_DiagReqData3 "null";
BA_ "GenSigSendType" SG_ 1711 CPD_DiagReqData4 7;
BA_ "InvalidValue" SG_ 1711 CPD_DiagReqData4 "null";
BA_ "GenSigSendType" SG_ 1711 CPD_DiagReqData5 7;
BA_ "InvalidValue" SG_ 1711 CPD_DiagReqData5 "null";
BA_ "GenSigSendType" SG_ 1711 CPD_DiagReqData6 7;
BA_ "InvalidValue" SG_ 1711 CPD_DiagReqData6 "null";
BA_ "GenSigSendType" SG_ 1711 CPD_DiagReqData7 7;
BA_ "InvalidValue" SG_ 1711 CPD_DiagReqData7 "null";
BA_ "InvalidValue" SG_ 1712 PAS_LITE_DiagReqData0 "";
BA_ "GenSigSendType" SG_ 1712 PAS_LITE_DiagReqData0 7;
BA_ "InvalidValue" SG_ 1712 PAS_LITE_DiagReqData1 "";
BA_ "GenSigSendType" SG_ 1712 PAS_LITE_DiagReqData1 7;
BA_ "InvalidValue" SG_ 1712 PAS_LITE_DiagReqData2 "";
BA_ "GenSigSendType" SG_ 1712 PAS_LITE_DiagReqData2 7;
BA_ "InvalidValue" SG_ 1712 PAS_LITE_DiagReqData3 "";
BA_ "GenSigSendType" SG_ 1712 PAS_LITE_DiagReqData3 7;
BA_ "InvalidValue" SG_ 1712 PAS_LITE_DiagReqData4 "";
BA_ "GenSigSendType" SG_ 1712 PAS_LITE_DiagReqData4 7;
BA_ "InvalidValue" SG_ 1712 PAS_LITE_DiagReqData5 "";
BA_ "GenSigSendType" SG_ 1712 PAS_LITE_DiagReqData5 7;
BA_ "InvalidValue" SG_ 1712 PAS_LITE_DiagReqData6 "";
BA_ "GenSigSendType" SG_ 1712 PAS_LITE_DiagReqData6 7;
BA_ "InvalidValue" SG_ 1712 PAS_LITE_DiagReqData7 "";
BA_ "GenSigSendType" SG_ 1712 PAS_LITE_DiagReqData7 7;
BA_ "GenSigSendType" SG_ 1716 SRR_FR_DiagReqData0 7;
BA_ "InvalidValue" SG_ 1716 SRR_FR_DiagReqData0 "null";
BA_ "GenSigSendType" SG_ 1716 SRR_FR_DiagReqData1 7;
BA_ "InvalidValue" SG_ 1716 SRR_FR_DiagReqData1 "null";
BA_ "GenSigSendType" SG_ 1716 SRR_FR_DiagReqData2 7;
BA_ "InvalidValue" SG_ 1716 SRR_FR_DiagReqData2 "null";
BA_ "GenSigSendType" SG_ 1716 SRR_FR_DiagReqData3 7;
BA_ "InvalidValue" SG_ 1716 SRR_FR_DiagReqData3 "null";
BA_ "GenSigSendType" SG_ 1716 SRR_FR_DiagReqData4 7;
BA_ "InvalidValue" SG_ 1716 SRR_FR_DiagReqData4 "null";
BA_ "GenSigSendType" SG_ 1716 SRR_FR_DiagReqData5 7;
BA_ "InvalidValue" SG_ 1716 SRR_FR_DiagReqData5 "null";
BA_ "GenSigSendType" SG_ 1716 SRR_FR_DiagReqData6 7;
BA_ "InvalidValue" SG_ 1716 SRR_FR_DiagReqData6 "null";
BA_ "GenSigSendType" SG_ 1716 SRR_FR_DiagReqData7 7;
BA_ "InvalidValue" SG_ 1716 SRR_FR_DiagReqData7 "null";
BA_ "GenSigSendType" SG_ 1717 SRR_FL_DiagReqData0 7;
BA_ "InvalidValue" SG_ 1717 SRR_FL_DiagReqData0 "null";
BA_ "GenSigSendType" SG_ 1717 SRR_FL_DiagReqData1 7;
BA_ "InvalidValue" SG_ 1717 SRR_FL_DiagReqData1 "null";
BA_ "GenSigSendType" SG_ 1717 SRR_FL_DiagReqData2 7;
BA_ "InvalidValue" SG_ 1717 SRR_FL_DiagReqData2 "null";
BA_ "GenSigSendType" SG_ 1717 SRR_FL_DiagReqData3 7;
BA_ "InvalidValue" SG_ 1717 SRR_FL_DiagReqData3 "null";
BA_ "GenSigSendType" SG_ 1717 SRR_FL_DiagReqData4 7;
BA_ "InvalidValue" SG_ 1717 SRR_FL_DiagReqData4 "null";
BA_ "GenSigSendType" SG_ 1717 SRR_FL_DiagReqData5 7;
BA_ "InvalidValue" SG_ 1717 SRR_FL_DiagReqData5 "null";
BA_ "GenSigSendType" SG_ 1717 SRR_FL_DiagReqData6 7;
BA_ "InvalidValue" SG_ 1717 SRR_FL_DiagReqData6 "null";
BA_ "GenSigSendType" SG_ 1717 SRR_FL_DiagReqData7 7;
BA_ "InvalidValue" SG_ 1717 SRR_FL_DiagReqData7 "null";
BA_ "GenSigSendType" SG_ 1718 SRR_RR_DiagReqData0 7;
BA_ "InvalidValue" SG_ 1718 SRR_RR_DiagReqData0 "null";
BA_ "GenSigSendType" SG_ 1718 SRR_RR_DiagReqData1 7;
BA_ "InvalidValue" SG_ 1718 SRR_RR_DiagReqData1 "null";
BA_ "GenSigSendType" SG_ 1718 SRR_RR_DiagReqData2 7;
BA_ "InvalidValue" SG_ 1718 SRR_RR_DiagReqData2 "null";
BA_ "GenSigSendType" SG_ 1718 SRR_RR_DiagReqData3 7;
BA_ "InvalidValue" SG_ 1718 SRR_RR_DiagReqData3 "null";
BA_ "GenSigSendType" SG_ 1718 SRR_RR_DiagReqData4 7;
BA_ "InvalidValue" SG_ 1718 SRR_RR_DiagReqData4 "null";
BA_ "GenSigSendType" SG_ 1718 SRR_RR_DiagReqData5 7;
BA_ "InvalidValue" SG_ 1718 SRR_RR_DiagReqData5 "null";
BA_ "GenSigSendType" SG_ 1718 SRR_RR_DiagReqData6 7;
BA_ "InvalidValue" SG_ 1718 SRR_RR_DiagReqData6 "null";
BA_ "GenSigSendType" SG_ 1718 SRR_RR_DiagReqData7 7;
BA_ "InvalidValue" SG_ 1718 SRR_RR_DiagReqData7 "null";
BA_ "GenSigSendType" SG_ 1719 SRR_RL_DiagReqData0 7;
BA_ "InvalidValue" SG_ 1719 SRR_RL_DiagReqData0 "null";
BA_ "GenSigSendType" SG_ 1719 SRR_RL_DiagReqData1 7;
BA_ "InvalidValue" SG_ 1719 SRR_RL_DiagReqData1 "null";
BA_ "GenSigSendType" SG_ 1719 SRR_RL_DiagReqData2 7;
BA_ "InvalidValue" SG_ 1719 SRR_RL_DiagReqData2 "null";
BA_ "GenSigSendType" SG_ 1719 SRR_RL_DiagReqData3 7;
BA_ "InvalidValue" SG_ 1719 SRR_RL_DiagReqData3 "null";
BA_ "GenSigSendType" SG_ 1719 SRR_RL_DiagReqData4 7;
BA_ "InvalidValue" SG_ 1719 SRR_RL_DiagReqData4 "null";
BA_ "GenSigSendType" SG_ 1719 SRR_RL_DiagReqData5 7;
BA_ "InvalidValue" SG_ 1719 SRR_RL_DiagReqData5 "null";
BA_ "GenSigSendType" SG_ 1719 SRR_RL_DiagReqData6 7;
BA_ "InvalidValue" SG_ 1719 SRR_RL_DiagReqData6 "null";
BA_ "GenSigSendType" SG_ 1719 SRR_RL_DiagReqData7 7;
BA_ "InvalidValue" SG_ 1719 SRR_RL_DiagReqData7 "null";
BA_ "GenSigSendType" SG_ 1721 SRR_RR_M_DiagReq_Data0 7;
BA_ "InvalidValue" SG_ 1721 SRR_RR_M_DiagReq_Data0 "null";
BA_ "GenSigSendType" SG_ 1721 SRR_RR_M_DiagReq_Data1 7;
BA_ "InvalidValue" SG_ 1721 SRR_RR_M_DiagReq_Data1 "null";
BA_ "GenSigSendType" SG_ 1721 SRR_RR_M_DiagReq_Data2 7;
BA_ "InvalidValue" SG_ 1721 SRR_RR_M_DiagReq_Data2 "null";
BA_ "GenSigSendType" SG_ 1721 SRR_RR_M_DiagReq_Data3 7;
BA_ "InvalidValue" SG_ 1721 SRR_RR_M_DiagReq_Data3 "null";
BA_ "GenSigSendType" SG_ 1721 SRR_RR_M_DiagReq_Data4 7;
BA_ "InvalidValue" SG_ 1721 SRR_RR_M_DiagReq_Data4 "null";
BA_ "GenSigSendType" SG_ 1721 SRR_RR_M_DiagReq_Data5 7;
BA_ "InvalidValue" SG_ 1721 SRR_RR_M_DiagReq_Data5 "null";
BA_ "GenSigSendType" SG_ 1721 SRR_RR_M_DiagReq_Data6 7;
BA_ "InvalidValue" SG_ 1721 SRR_RR_M_DiagReq_Data6 "null";
BA_ "GenSigSendType" SG_ 1721 SRR_RR_M_DiagReq_Data7 7;
BA_ "InvalidValue" SG_ 1721 SRR_RR_M_DiagReq_Data7 "null";
BA_ "GenSigSendType" SG_ 1723 TRM_DiagReqData0 7;
BA_ "InvalidValue" SG_ 1723 TRM_DiagReqData0 "null";
BA_ "GenSigSendType" SG_ 1723 TRM_DiagReqData1 7;
BA_ "InvalidValue" SG_ 1723 TRM_DiagReqData1 "null";
BA_ "GenSigSendType" SG_ 1723 TRM_DiagReqData2 7;
BA_ "InvalidValue" SG_ 1723 TRM_DiagReqData2 "null";
BA_ "GenSigSendType" SG_ 1723 TRM_DiagReqData3 7;
BA_ "InvalidValue" SG_ 1723 TRM_DiagReqData3 "null";
BA_ "GenSigSendType" SG_ 1723 TRM_DiagReqData4 7;
BA_ "InvalidValue" SG_ 1723 TRM_DiagReqData4 "null";
BA_ "GenSigSendType" SG_ 1723 TRM_DiagReqData5 7;
BA_ "InvalidValue" SG_ 1723 TRM_DiagReqData5 "null";
BA_ "GenSigSendType" SG_ 1723 TRM_DiagReqData6 7;
BA_ "InvalidValue" SG_ 1723 TRM_DiagReqData6 "null";
BA_ "GenSigSendType" SG_ 1723 TRM_DiagReqData7 7;
BA_ "InvalidValue" SG_ 1723 TRM_DiagReqData7 "null";
BA_ "GenSigSendType" SG_ 1725 POD_DCDC_DiagReqData0 7;
BA_ "InvalidValue" SG_ 1725 POD_DCDC_DiagReqData0 "null";
BA_ "GenSigSendType" SG_ 1725 POD_DCDC_DiagReqData1 7;
BA_ "InvalidValue" SG_ 1725 POD_DCDC_DiagReqData1 "null";
BA_ "GenSigSendType" SG_ 1725 POD_DCDC_DiagReqData2 7;
BA_ "InvalidValue" SG_ 1725 POD_DCDC_DiagReqData2 "null";
BA_ "GenSigSendType" SG_ 1725 POD_DCDC_DiagReqData3 7;
BA_ "InvalidValue" SG_ 1725 POD_DCDC_DiagReqData3 "null";
BA_ "GenSigSendType" SG_ 1725 POD_DCDC_DiagReqData4 7;
BA_ "InvalidValue" SG_ 1725 POD_DCDC_DiagReqData4 "null";
BA_ "GenSigSendType" SG_ 1725 POD_DCDC_DiagReqData5 7;
BA_ "InvalidValue" SG_ 1725 POD_DCDC_DiagReqData5 "null";
BA_ "GenSigSendType" SG_ 1725 POD_DCDC_DiagReqData6 7;
BA_ "InvalidValue" SG_ 1725 POD_DCDC_DiagReqData6 "null";
BA_ "GenSigSendType" SG_ 1725 POD_DCDC_DiagReqData7 7;
BA_ "InvalidValue" SG_ 1725 POD_DCDC_DiagReqData7 "null";
BA_ "GenSigSendType" SG_ 1726 POD_OBC_DiagReqData0 7;
BA_ "InvalidValue" SG_ 1726 POD_OBC_DiagReqData0 "null";
BA_ "GenSigSendType" SG_ 1726 POD_OBC_DiagReqData1 7;
BA_ "InvalidValue" SG_ 1726 POD_OBC_DiagReqData1 "null";
BA_ "GenSigSendType" SG_ 1726 POD_OBC_DiagReqData2 7;
BA_ "InvalidValue" SG_ 1726 POD_OBC_DiagReqData2 "null";
BA_ "GenSigSendType" SG_ 1726 POD_OBC_DiagReqData3 7;
BA_ "InvalidValue" SG_ 1726 POD_OBC_DiagReqData3 "null";
BA_ "GenSigSendType" SG_ 1726 POD_OBC_DiagReqData4 7;
BA_ "InvalidValue" SG_ 1726 POD_OBC_DiagReqData4 "null";
BA_ "GenSigSendType" SG_ 1726 POD_OBC_DiagReqData5 7;
BA_ "InvalidValue" SG_ 1726 POD_OBC_DiagReqData5 "null";
BA_ "GenSigSendType" SG_ 1726 POD_OBC_DiagReqData6 7;
BA_ "InvalidValue" SG_ 1726 POD_OBC_DiagReqData6 "null";
BA_ "GenSigSendType" SG_ 1726 POD_OBC_DiagReqData7 7;
BA_ "InvalidValue" SG_ 1726 POD_OBC_DiagReqData7 "null";
BA_ "GenSigSendType" SG_ 1727 POD_DiagReqData0 7;
BA_ "InvalidValue" SG_ 1727 POD_DiagReqData0 "null";
BA_ "GenSigSendType" SG_ 1727 POD_DiagReqData1 7;
BA_ "InvalidValue" SG_ 1727 POD_DiagReqData1 "null";
BA_ "GenSigSendType" SG_ 1727 POD_DiagReqData2 7;
BA_ "InvalidValue" SG_ 1727 POD_DiagReqData2 "null";
BA_ "GenSigSendType" SG_ 1727 POD_DiagReqData3 7;
BA_ "InvalidValue" SG_ 1727 POD_DiagReqData3 "null";
BA_ "GenSigSendType" SG_ 1727 POD_DiagReqData4 7;
BA_ "InvalidValue" SG_ 1727 POD_DiagReqData4 "null";
BA_ "GenSigSendType" SG_ 1727 POD_DiagReqData5 7;
BA_ "InvalidValue" SG_ 1727 POD_DiagReqData5 "null";
BA_ "GenSigSendType" SG_ 1727 POD_DiagReqData6 7;
BA_ "InvalidValue" SG_ 1727 POD_DiagReqData6 "null";
BA_ "GenSigSendType" SG_ 1727 POD_DiagReqData7 7;
BA_ "InvalidValue" SG_ 1727 POD_DiagReqData7 "null";
BA_ "GenSigSendType" SG_ 1729 APM_DiagReqData0 7;
BA_ "InvalidValue" SG_ 1729 APM_DiagReqData0 "null";
BA_ "GenSigSendType" SG_ 1729 APM_DiagReqData1 7;
BA_ "InvalidValue" SG_ 1729 APM_DiagReqData1 "null";
BA_ "GenSigSendType" SG_ 1729 APM_DiagReqData2 7;
BA_ "InvalidValue" SG_ 1729 APM_DiagReqData2 "null";
BA_ "GenSigSendType" SG_ 1729 APM_DiagReqData3 7;
BA_ "InvalidValue" SG_ 1729 APM_DiagReqData3 "null";
BA_ "GenSigSendType" SG_ 1729 APM_DiagReqData4 7;
BA_ "InvalidValue" SG_ 1729 APM_DiagReqData4 "null";
BA_ "GenSigSendType" SG_ 1729 APM_DiagReqData5 7;
BA_ "InvalidValue" SG_ 1729 APM_DiagReqData5 "null";
BA_ "GenSigSendType" SG_ 1729 APM_DiagReqData6 7;
BA_ "InvalidValue" SG_ 1729 APM_DiagReqData6 "null";
BA_ "GenSigSendType" SG_ 1729 APM_DiagReqData7 7;
BA_ "InvalidValue" SG_ 1729 APM_DiagReqData7 "null";
BA_ "GenSigSendType" SG_ 1730 SHVU_F_DiagReqData0 7;
BA_ "InvalidValue" SG_ 1730 SHVU_F_DiagReqData0 "null";
BA_ "GenSigSendType" SG_ 1730 SHVU_F_DiagReqData1 7;
BA_ "InvalidValue" SG_ 1730 SHVU_F_DiagReqData1 "null";
BA_ "GenSigSendType" SG_ 1730 SHVU_F_DiagReqData2 7;
BA_ "InvalidValue" SG_ 1730 SHVU_F_DiagReqData2 "null";
BA_ "GenSigSendType" SG_ 1730 SHVU_F_DiagReqData3 7;
BA_ "InvalidValue" SG_ 1730 SHVU_F_DiagReqData3 "null";
BA_ "GenSigSendType" SG_ 1730 SHVU_F_DiagReqData4 7;
BA_ "InvalidValue" SG_ 1730 SHVU_F_DiagReqData4 "null";
BA_ "GenSigSendType" SG_ 1730 SHVU_F_DiagReqData5 7;
BA_ "InvalidValue" SG_ 1730 SHVU_F_DiagReqData5 "null";
BA_ "GenSigSendType" SG_ 1730 SHVU_F_DiagReqData6 7;
BA_ "InvalidValue" SG_ 1730 SHVU_F_DiagReqData6 "null";
BA_ "GenSigSendType" SG_ 1730 SHVU_F_DiagReqData7 7;
BA_ "InvalidValue" SG_ 1730 SHVU_F_DiagReqData7 "null";
BA_ "GenSigSendType" SG_ 1731 SHVU_R_DiagReqData0 7;
BA_ "InvalidValue" SG_ 1731 SHVU_R_DiagReqData0 "null";
BA_ "GenSigSendType" SG_ 1731 SHVU_R_DiagReqData1 7;
BA_ "InvalidValue" SG_ 1731 SHVU_R_DiagReqData1 "null";
BA_ "GenSigSendType" SG_ 1731 SHVU_R_DiagReqData2 7;
BA_ "InvalidValue" SG_ 1731 SHVU_R_DiagReqData2 "null";
BA_ "GenSigSendType" SG_ 1731 SHVU_R_DiagReqData3 7;
BA_ "InvalidValue" SG_ 1731 SHVU_R_DiagReqData3 "null";
BA_ "GenSigSendType" SG_ 1731 SHVU_R_DiagReqData4 7;
BA_ "InvalidValue" SG_ 1731 SHVU_R_DiagReqData4 "null";
BA_ "GenSigSendType" SG_ 1731 SHVU_R_DiagReqData5 7;
BA_ "InvalidValue" SG_ 1731 SHVU_R_DiagReqData5 "null";
BA_ "GenSigSendType" SG_ 1731 SHVU_R_DiagReqData6 7;
BA_ "InvalidValue" SG_ 1731 SHVU_R_DiagReqData6 "null";
BA_ "GenSigSendType" SG_ 1731 SHVU_R_DiagReqData7 7;
BA_ "InvalidValue" SG_ 1731 SHVU_R_DiagReqData7 "null";
BA_ "GenSigSendType" SG_ 1732 OCS_P_DiagReqData0 7;
BA_ "InvalidValue" SG_ 1732 OCS_P_DiagReqData0 "null";
BA_ "GenSigSendType" SG_ 1732 OCS_P_DiagReqData1 7;
BA_ "InvalidValue" SG_ 1732 OCS_P_DiagReqData1 "null";
BA_ "GenSigSendType" SG_ 1732 OCS_P_DiagReqData2 7;
BA_ "InvalidValue" SG_ 1732 OCS_P_DiagReqData2 "null";
BA_ "GenSigSendType" SG_ 1732 OCS_P_DiagReqData3 7;
BA_ "InvalidValue" SG_ 1732 OCS_P_DiagReqData3 "null";
BA_ "GenSigSendType" SG_ 1732 OCS_P_DiagReqData4 7;
BA_ "InvalidValue" SG_ 1732 OCS_P_DiagReqData4 "null";
BA_ "GenSigSendType" SG_ 1732 OCS_P_DiagReqData5 7;
BA_ "InvalidValue" SG_ 1732 OCS_P_DiagReqData5 "null";
BA_ "GenSigSendType" SG_ 1732 OCS_P_DiagReqData6 7;
BA_ "InvalidValue" SG_ 1732 OCS_P_DiagReqData6 "null";
BA_ "GenSigSendType" SG_ 1732 OCS_P_DiagReqData7 7;
BA_ "InvalidValue" SG_ 1732 OCS_P_DiagReqData7 "null";
BA_ "GenSigSendType" SG_ 1737 LDM_L_DiagReqData0 7;
BA_ "InvalidValue" SG_ 1737 LDM_L_DiagReqData0 "null";
BA_ "GenSigSendType" SG_ 1737 LDM_L_DiagReqData1 7;
BA_ "InvalidValue" SG_ 1737 LDM_L_DiagReqData1 "null";
BA_ "GenSigSendType" SG_ 1737 LDM_L_DiagReqData2 7;
BA_ "InvalidValue" SG_ 1737 LDM_L_DiagReqData2 "null";
BA_ "GenSigSendType" SG_ 1737 LDM_L_DiagReqData3 7;
BA_ "InvalidValue" SG_ 1737 LDM_L_DiagReqData3 "null";
BA_ "GenSigSendType" SG_ 1737 LDM_L_DiagReqData4 7;
BA_ "InvalidValue" SG_ 1737 LDM_L_DiagReqData4 "null";
BA_ "GenSigSendType" SG_ 1737 LDM_L_DiagReqData5 7;
BA_ "InvalidValue" SG_ 1737 LDM_L_DiagReqData5 "null";
BA_ "GenSigSendType" SG_ 1737 LDM_L_DiagReqData6 7;
BA_ "InvalidValue" SG_ 1737 LDM_L_DiagReqData6 "null";
BA_ "GenSigSendType" SG_ 1737 LDM_L_DiagReqData7 7;
BA_ "InvalidValue" SG_ 1737 LDM_L_DiagReqData7 "null";
BA_ "GenSigSendType" SG_ 1738 LDM_R_DiagReqData0 7;
BA_ "InvalidValue" SG_ 1738 LDM_R_DiagReqData0 "null";
BA_ "GenSigSendType" SG_ 1738 LDM_R_DiagReqData1 7;
BA_ "InvalidValue" SG_ 1738 LDM_R_DiagReqData1 "null";
BA_ "GenSigSendType" SG_ 1738 LDM_R_DiagReqData2 7;
BA_ "InvalidValue" SG_ 1738 LDM_R_DiagReqData2 "null";
BA_ "GenSigSendType" SG_ 1738 LDM_R_DiagReqData3 7;
BA_ "InvalidValue" SG_ 1738 LDM_R_DiagReqData3 "null";
BA_ "GenSigSendType" SG_ 1738 LDM_R_DiagReqData4 7;
BA_ "InvalidValue" SG_ 1738 LDM_R_DiagReqData4 "null";
BA_ "GenSigSendType" SG_ 1738 LDM_R_DiagReqData5 7;
BA_ "InvalidValue" SG_ 1738 LDM_R_DiagReqData5 "null";
BA_ "GenSigSendType" SG_ 1738 LDM_R_DiagReqData6 7;
BA_ "InvalidValue" SG_ 1738 LDM_R_DiagReqData6 "null";
BA_ "GenSigSendType" SG_ 1738 LDM_R_DiagReqData7 7;
BA_ "InvalidValue" SG_ 1738 LDM_R_DiagReqData7 "null";
BA_ "GenSigSendType" SG_ 1752 BAS_DiagReqData0 7;
BA_ "InvalidValue" SG_ 1752 BAS_DiagReqData0 "null";
BA_ "GenSigSendType" SG_ 1752 BAS_DiagReqData1 7;
BA_ "InvalidValue" SG_ 1752 BAS_DiagReqData1 "null";
BA_ "GenSigSendType" SG_ 1752 BAS_DiagReqData2 7;
BA_ "InvalidValue" SG_ 1752 BAS_DiagReqData2 "null";
BA_ "GenSigSendType" SG_ 1752 BAS_DiagReqData3 7;
BA_ "InvalidValue" SG_ 1752 BAS_DiagReqData3 "null";
BA_ "GenSigSendType" SG_ 1752 BAS_DiagReqData4 7;
BA_ "InvalidValue" SG_ 1752 BAS_DiagReqData4 "null";
BA_ "GenSigSendType" SG_ 1752 BAS_DiagReqData5 7;
BA_ "InvalidValue" SG_ 1752 BAS_DiagReqData5 "null";
BA_ "GenSigSendType" SG_ 1752 BAS_DiagReqData6 7;
BA_ "InvalidValue" SG_ 1752 BAS_DiagReqData6 "null";
BA_ "GenSigSendType" SG_ 1752 BAS_DiagReqData7 7;
BA_ "InvalidValue" SG_ 1752 BAS_DiagReqData7 "null";
BA_ "GenSigSendType" SG_ 1764 DCM_APM_DiagReqData0 7;
BA_ "InvalidValue" SG_ 1764 DCM_APM_DiagReqData0 "null";
BA_ "GenSigSendType" SG_ 1764 DCM_APM_DiagReqData1 7;
BA_ "InvalidValue" SG_ 1764 DCM_APM_DiagReqData1 "null";
BA_ "GenSigSendType" SG_ 1764 DCM_APM_DiagReqData2 7;
BA_ "InvalidValue" SG_ 1764 DCM_APM_DiagReqData2 "null";
BA_ "GenSigSendType" SG_ 1764 DCM_APM_DiagReqData3 7;
BA_ "InvalidValue" SG_ 1764 DCM_APM_DiagReqData3 "null";
BA_ "GenSigSendType" SG_ 1764 DCM_APM_DiagReqData4 7;
BA_ "InvalidValue" SG_ 1764 DCM_APM_DiagReqData4 "null";
BA_ "GenSigSendType" SG_ 1764 DCM_APM_DiagReqData5 7;
BA_ "InvalidValue" SG_ 1764 DCM_APM_DiagReqData5 "null";
BA_ "GenSigSendType" SG_ 1764 DCM_APM_DiagReqData6 7;
BA_ "InvalidValue" SG_ 1764 DCM_APM_DiagReqData6 "null";
BA_ "GenSigSendType" SG_ 1764 DCM_APM_DiagReqData7 7;
BA_ "InvalidValue" SG_ 1764 DCM_APM_DiagReqData7 "null";
BA_ "GenSigSendType" SG_ 1774 MHU_FOTA_ReqAll_00 7;
BA_ "GenSigSendType" SG_ 1774 MHU_FOTA_ReqAll_01 7;
BA_ "GenSigSendType" SG_ 1774 MHU_FOTA_ReqAll_02 7;
BA_ "GenSigSendType" SG_ 1774 MHU_FOTA_ReqAll_03 7;
BA_ "GenSigSendType" SG_ 1774 MHU_FOTA_ReqAll_04 7;
BA_ "GenSigSendType" SG_ 1774 MHU_FOTA_ReqAll_05 7;
BA_ "GenSigSendType" SG_ 1774 MHU_FOTA_ReqAll_06 7;
BA_ "GenSigSendType" SG_ 1774 MHU_FOTA_ReqAll_07 7;
BA_ "GenSigSendType" SG_ 1777 ASU_DiagReqData0 7;
BA_ "GenSigSendType" SG_ 1777 ASU_DiagReqData1 7;
BA_ "GenSigSendType" SG_ 1777 ASU_DiagReqData2 7;
BA_ "GenSigSendType" SG_ 1777 ASU_DiagReqData3 7;
BA_ "GenSigSendType" SG_ 1777 ASU_DiagReqData4 7;
BA_ "GenSigSendType" SG_ 1777 ASU_DiagReqData5 7;
BA_ "GenSigSendType" SG_ 1777 ASU_DiagReqData6 7;
BA_ "GenSigSendType" SG_ 1777 ASU_DiagReqData7 7;
BA_ "GenSigSendType" SG_ 1787 BCM_BPM_DiagReqData0 7;
BA_ "InvalidValue" SG_ 1787 BCM_BPM_DiagReqData0 "null";
BA_ "GenSigSendType" SG_ 1787 BCM_BPM_DiagReqData1 7;
BA_ "InvalidValue" SG_ 1787 BCM_BPM_DiagReqData1 "null";
BA_ "GenSigSendType" SG_ 1787 BCM_BPM_DiagReqData2 7;
BA_ "InvalidValue" SG_ 1787 BCM_BPM_DiagReqData2 "null";
BA_ "GenSigSendType" SG_ 1787 BCM_BPM_DiagReqData3 7;
BA_ "InvalidValue" SG_ 1787 BCM_BPM_DiagReqData3 "null";
BA_ "GenSigSendType" SG_ 1787 BCM_BPM_DiagReqData4 7;
BA_ "InvalidValue" SG_ 1787 BCM_BPM_DiagReqData4 "null";
BA_ "GenSigSendType" SG_ 1787 BCM_BPM_DiagReqData5 7;
BA_ "InvalidValue" SG_ 1787 BCM_BPM_DiagReqData5 "null";
BA_ "GenSigSendType" SG_ 1787 BCM_BPM_DiagReqData6 7;
BA_ "InvalidValue" SG_ 1787 BCM_BPM_DiagReqData6 "null";
BA_ "GenSigSendType" SG_ 1787 BCM_BPM_DiagReqData7 7;
BA_ "InvalidValue" SG_ 1787 BCM_BPM_DiagReqData7 "null";
BA_ "GenSigSendType" SG_ 1791 DiagReqAllEcuData0 7;
BA_ "InvalidValue" SG_ 1791 DiagReqAllEcuData0 "null";
BA_ "GenSigSendType" SG_ 1791 DiagReqAllEcuData1 7;
BA_ "InvalidValue" SG_ 1791 DiagReqAllEcuData1 "null";
BA_ "GenSigSendType" SG_ 1791 DiagReqAllEcuData2 7;
BA_ "InvalidValue" SG_ 1791 DiagReqAllEcuData2 "null";
BA_ "GenSigSendType" SG_ 1791 DiagReqAllEcuData3 7;
BA_ "InvalidValue" SG_ 1791 DiagReqAllEcuData3 "null";
BA_ "GenSigSendType" SG_ 1791 DiagReqAllEcuData4 7;
BA_ "InvalidValue" SG_ 1791 DiagReqAllEcuData4 "null";
BA_ "GenSigSendType" SG_ 1791 DiagReqAllEcuData5 7;
BA_ "InvalidValue" SG_ 1791 DiagReqAllEcuData5 "null";
BA_ "GenSigSendType" SG_ 1791 DiagReqAllEcuData6 7;
BA_ "InvalidValue" SG_ 1791 DiagReqAllEcuData6 "null";
BA_ "GenSigSendType" SG_ 1791 DiagReqAllEcuData7 7;
BA_ "InvalidValue" SG_ 1791 DiagReqAllEcuData7 "null";
BA_ "GenSigSendType" SG_ 1803 SEED_CAN_Req6 7;
BA_ "InvalidValue" SG_ 1803 SEED_CAN_Req6 "null";
BA_ "GenSigSendType" SG_ 1805 SEED_CAN_Req7 7;
BA_ "InvalidValue" SG_ 1805 SEED_CAN_Req7 "null";
BA_ "GenSigSendType" SG_ 1841 SEED_CAN_Req17 7;
BA_ "InvalidValue" SG_ 1841 SEED_CAN_Req17 "null";
BA_ "GenSigSendType" SG_ 1843 SEED_CAN_Req18 7;
BA_ "InvalidValue" SG_ 1843 SEED_CAN_Req18 "null";
BA_ "GenSigSendType" SG_ 1845 SEED_CAN_Req20 7;
BA_ "InvalidValue" SG_ 1845 SEED_CAN_Req20 "null";
BA_ "GenSigSendType" SG_ 1847 SEED_CAN_Req21 7;
BA_ "InvalidValue" SG_ 1847 SEED_CAN_Req21 "null";
BA_ "GenSigSendType" SG_ 1850 SEED_CAN_Req25 7;
BA_ "GenSigSendType" SG_ 1853 SEED_CAN_Req29 7;
BA_ "GenSigTimeoutTime_ALL" SG_ 1873 VCU_DebugDiag2 500;
BA_ "InvalidValue" SG_ 1873 VCU_DebugDiag2 "null";
BA_ "GenSigTimeoutTime_ALL" SG_ 1873 VCU_DebugDiag1 500;
BA_ "InvalidValue" SG_ 1873 VCU_DebugDiag1 "null";
BA_ "GenSigTimeoutTime_ALL" SG_ 1873 VCU_DebugDiag5 500;
BA_ "InvalidValue" SG_ 1873 VCU_DebugDiag5 "null";
BA_ "GenSigTimeoutTime_ALL" SG_ 1873 VCU_DebugDiag4 500;
BA_ "InvalidValue" SG_ 1873 VCU_DebugDiag4 "null";
BA_ "GenSigTimeoutTime_ALL" SG_ 1873 VCU_DebugDiag3 500;
BA_ "InvalidValue" SG_ 1873 VCU_DebugDiag3 "null";
BA_ "GenSigTimeoutTime_ALL" SG_ 1873 VCU_DebugDiag8 500;
BA_ "InvalidValue" SG_ 1873 VCU_DebugDiag8 "null";
BA_ "GenSigTimeoutTime_ALL" SG_ 1873 VCU_DebugDiag7 500;
BA_ "InvalidValue" SG_ 1873 VCU_DebugDiag7 "null";
BA_ "GenSigTimeoutTime_ALL" SG_ 1873 VCU_DebugDiag6 500;
BA_ "InvalidValue" SG_ 1873 VCU_DebugDiag6 "null";
BA_ "GenSigTimeoutTime_ALL" SG_ 1873 VCU_DebugDiag10 500;
BA_ "InvalidValue" SG_ 1873 VCU_DebugDiag10 "null";
BA_ "GenSigTimeoutTime_ALL" SG_ 1873 VCU_DebugDiag9 500;
BA_ "InvalidValue" SG_ 1873 VCU_DebugDiag9 "null";
BA_ "GenSigTimeoutTime_ALL" SG_ 1873 VCU_DebugDiag13 500;
BA_ "InvalidValue" SG_ 1873 VCU_DebugDiag13 "null";
BA_ "GenSigTimeoutTime_ALL" SG_ 1873 VCU_DebugDiag12 500;
BA_ "InvalidValue" SG_ 1873 VCU_DebugDiag12 "null";
BA_ "GenSigTimeoutTime_ALL" SG_ 1873 VCU_DebugDiag11 500;
BA_ "InvalidValue" SG_ 1873 VCU_DebugDiag11 "null";
BA_ "GenSigTimeoutTime_ALL" SG_ 1873 VCU_DebugDiag16 500;
BA_ "InvalidValue" SG_ 1873 VCU_DebugDiag16 "null";
BA_ "GenSigTimeoutTime_ALL" SG_ 1873 VCU_DebugDiag15 500;
BA_ "InvalidValue" SG_ 1873 VCU_DebugDiag15 "null";
BA_ "GenSigTimeoutTime_ALL" SG_ 1873 VCU_DebugDiag14 500;
BA_ "InvalidValue" SG_ 1873 VCU_DebugDiag14 "null";
BA_ "GenSigTimeoutTime_ALL" SG_ 1873 VCU_DebugDiag18 500;
BA_ "InvalidValue" SG_ 1873 VCU_DebugDiag18 "null";
BA_ "GenSigTimeoutTime_ALL" SG_ 1873 VCU_DebugDiag17 500;
BA_ "InvalidValue" SG_ 1873 VCU_DebugDiag17 "null";
BA_ "GenSigTimeoutTime_ALL" SG_ 1873 VCU_DebugDiag20 500;
BA_ "InvalidValue" SG_ 1873 VCU_DebugDiag20 "null";
BA_ "GenSigTimeoutTime_ALL" SG_ 1873 VCU_DebugDiag19 500;
BA_ "InvalidValue" SG_ 1873 VCU_DebugDiag19 "null";
BA_ "GenSigSendType" SG_ 2015 Diag_Request_ECU_Data0 7;
BA_ "InvalidValue" SG_ 2015 Diag_Request_ECU_Data0 "null";
BA_ "GenSigSendType" SG_ 2015 Diag_Request_ECU_Data1 7;
BA_ "InvalidValue" SG_ 2015 Diag_Request_ECU_Data1 "null";
BA_ "GenSigSendType" SG_ 2015 Diag_Request_ECU_Data2 7;
BA_ "InvalidValue" SG_ 2015 Diag_Request_ECU_Data2 "null";
BA_ "GenSigSendType" SG_ 2015 Diag_Request_ECU_Data3 7;
BA_ "InvalidValue" SG_ 2015 Diag_Request_ECU_Data3 "null";
BA_ "GenSigSendType" SG_ 2015 Diag_Request_ECU_Data4 7;
BA_ "InvalidValue" SG_ 2015 Diag_Request_ECU_Data4 "null";
BA_ "GenSigSendType" SG_ 2015 Diag_Request_ECU_Data5 7;
BA_ "InvalidValue" SG_ 2015 Diag_Request_ECU_Data5 "null";
BA_ "GenSigSendType" SG_ 2015 Diag_Request_ECU_Data6 7;
BA_ "InvalidValue" SG_ 2015 Diag_Request_ECU_Data6 "null";
BA_ "GenSigSendType" SG_ 2015 Diag_Request_ECU_Data7 7;
BA_ "InvalidValue" SG_ 2015 Diag_Request_ECU_Data7 "null";
BA_ "GenSigTimeoutTime_ALL" SG_ 280 CHKSM_BCM_MHU_Ctrl_Fbk 2500;
BA_ "InvalidValue" SG_ 280 CHKSM_BCM_MHU_Ctrl_Fbk "null";
BA_ "GenSigTimeoutTime_ALL" SG_ 280 ALV_BCM_MHU_Ctrl_Fbk 2500;
BA_ "InvalidValue" SG_ 280 ALV_BCM_MHU_Ctrl_Fbk "Fh";
BA_ "GenSigTimeoutTime_ALL" SG_ 280 BCM_DrvInhibitStsFbk 2500;
BA_ "InvalidValue" SG_ 280 BCM_DrvInhibitStsFbk "0h";
BA_ "GenSigSendType" SG_ 287 MHU_DrvInhibitSts 2;
BA_ "InvalidValue" SG_ 287 MHU_DrvInhibitSts "0h";
BA_ "GenSigSendType" SG_ 287 TBOX_AuthCode_0x11F 2;
BA_ "InvalidValue" SG_ 287 TBOX_AuthCode_0x11F "null";
VAL_ 1873 VCU_DebugDiag2 0 "No Error" 1 "Error Level 1" 2 "Error Level 2" 3 "Error Level 3" 4 "Error Level 4";
VAL_ 1873 VCU_DebugDiag1 0 "No Error" 1 "Error Level 1" 2 "Error Level 2" 3 "Error Level 3" 4 "Error Level 4";
VAL_ 1873 VCU_DebugDiag5 0 "No Error" 1 "Error Level 1" 2 "Error Level 2" 3 "Error Level 3" 4 "Error Level 4";
VAL_ 1873 VCU_DebugDiag4 0 "No Error" 1 "Error Level 1" 2 "Error Level 2" 3 "Error Level 3" 4 "Error Level 4";
VAL_ 1873 VCU_DebugDiag3 0 "No Error" 1 "Error Level 1" 2 "Error Level 2" 3 "Error Level 3" 4 "Error Level 4";
VAL_ 1873 VCU_DebugDiag8 0 "No Error" 1 "Error Level 1" 2 "Error Level 2" 3 "Error Level 3" 4 "Error Level 4";
VAL_ 1873 VCU_DebugDiag7 0 "No Error" 1 "Error Level 1" 2 "Error Level 2" 3 "Error Level 3" 4 "Error Level 4";
VAL_ 1873 VCU_DebugDiag6 0 "No Error" 1 "Error Level 1" 2 "Error Level 2" 3 "Error Level 3" 4 "Error Level 4";
VAL_ 1873 VCU_DebugDiag10 0 "No Error" 1 "Error Level 1" 2 "Error Level 2" 3 "Error Level 3" 4 "Error Level 4";
VAL_ 1873 VCU_DebugDiag9 0 "No Error" 1 "Error Level 1" 2 "Error Level 2" 3 "Error Level 3" 4 "Error Level 4";
VAL_ 1873 VCU_DebugDiag13 0 "No Error" 1 "Error Level 1" 2 "Error Level 2" 3 "Error Level 3" 4 "Error Level 4";
VAL_ 1873 VCU_DebugDiag12 0 "No Error" 1 "Error Level 1" 2 "Error Level 2" 3 "Error Level 3" 4 "Error Level 4";
VAL_ 1873 VCU_DebugDiag11 0 "No Error" 1 "Error Level 1" 2 "Error Level 2" 3 "Error Level 3" 4 "Error Level 4";
VAL_ 1873 VCU_DebugDiag16 0 "No Error" 1 "Error Level 1" 2 "Error Level 2" 3 "Error Level 3" 4 "Error Level 4";
VAL_ 1873 VCU_DebugDiag15 0 "No Error" 1 "Error Level 1" 2 "Error Level 2" 3 "Error Level 3" 4 "Error Level 4";
VAL_ 1873 VCU_DebugDiag14 0 "No Error" 1 "Error Level 1" 2 "Error Level 2" 3 "Error Level 3" 4 "Error Level 4";
VAL_ 1873 VCU_DebugDiag18 0 "No Error" 1 "Error Level 1" 2 "Error Level 2" 3 "Error Level 3" 4 "Error Level 4";
VAL_ 1873 VCU_DebugDiag17 0 "No Error" 1 "Error Level 1" 2 "Error Level 2" 3 "Error Level 3" 4 "Error Level 4";
VAL_ 1873 VCU_DebugDiag20 0 "No Error" 1 "Error Level 1" 2 "Error Level 2" 3 "Error Level 3" 4 "Error Level 4";
VAL_ 1873 VCU_DebugDiag19 0 "No Error" 1 "Error Level 1" 2 "Error Level 2" 3 "Error Level 3" 4 "Error Level 4";
VAL_ 287 MHU_DrvInhibitSts 0 "No effect" 1 "Inhibited" 2 "UnInhibited" 3 "Signal Invalid";
VAL_ 280 BCM_DrvInhibitStsFbk 0 "No effect" 1 "Inhibited" 2 "UnInhibited" 3 "Signal Invalid";
